VERSION "HNPBNNNYNNNNNNNNNNNNNNNNNNNNNNNNYNYYYYYYYY>4>%%%/4>'%**4YYY///"

NS_ :

BS_:

BU_: TPM TCM SCCM RF_HUB PTS ORC IC HaLF ETM ESM ESC EPS ECM Diagnost DTCM DASM CBC AFLS ADCM

BO_ 1099 VehCfgBu5: 8 RF_HUB
 SG_ VC_BU_VehCfg5_Stat : 0|2@1+ (1,0) [0|0] ""  CBC
 SG_ VC_BU_LUCI_PRSNT : 2|1@1+ (1,0) [0|0] ""  CBC
 SG_ VC_BU_RR_DuallyPrsnt : 3|1@1+ (1,0) [0|0] ""  CBC
 SG_ VC_BU_NonReg_TPIS : 4|1@1+ (1,0) [0|0] ""  CBC
 SG_ VC_BU_WTS_Prsnt : 5|1@1+ (1,0) [0|0] ""  CBC
 SG_ VC_BU_AmbTempLct : 6|2@1+ (1,0) [0|0] ""  CBC
 SG_ VC_BU_Strng_Rt_0 : 8|8@1+ (0.1,0) [0|25.4] ""  CBC
 SG_ VC_BU_Strng_Rt_pls1 : 16|8@1+ (0.1,0) [0|25.4] ""  CBC
 SG_ VC_BU_Strng_Rt_pls2 : 24|8@1+ (0.1,0) [0|25.4] ""  CBC
 SG_ VC_BU_Strng_Rt_pls3 : 32|8@1+ (0.1,0) [0|25.4] ""  CBC
 SG_ VC_BU_Strng_Rt_pls4 : 40|8@1+ (0.1,0) [0|25.4] ""  CBC
 SG_ VC_BU_Strng_Rt_pls5 : 48|8@1+ (0.1,0) [0|25.4] ""  CBC
 SG_ VC_BU_RearDoorLocks2DCM : 56|1@1+ (1,0) [0|0] ""  CBC
 SG_ VC_BU_SpdLmt_PRSNT : 57|1@1+ (1,0) [0|0] ""  CBC
 SG_ VC_BU_SBR_Prsnt : 58|1@1+ (1,0) [0|0] ""  CBC
 SG_ VC_BU_ChildDisp_Prsnt : 59|1@1+ (1,0) [0|0] ""  CBC
 SG_ VC_BU_OffRoadPg : 60|1@1+ (1,0) [0|0] ""  CBC
 SG_ VC_BU_AmbLtgPrsnt : 61|1@1+ (1,0) [0|0] ""  CBC
 SG_ VC_BU_PPPA_Prsnt : 62|1@1+ (1,0) [0|0] ""  CBC
 SG_ VC_BU_ParkStopPrsnt : 63|1@1+ (1,0) [0|0] ""  CBC

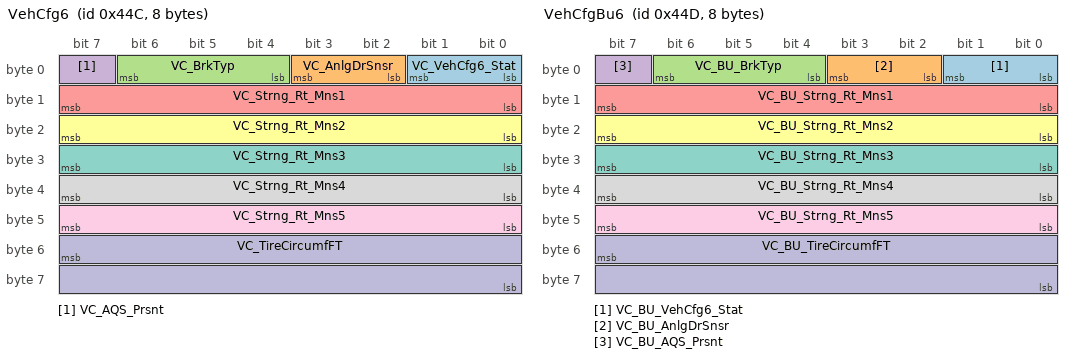
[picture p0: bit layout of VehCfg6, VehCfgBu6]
BO_ 1100 VehCfg6: 8 CBC
 SG_ VC_VehCfg6_Stat : 0|2@1+ (1,0) [0|0] ""  ORC,TCM,ECM,ESC,RF_HUB
 SG_ VC_AnlgDrSnsr : 2|2@1+ (1,0) [0|0] ""  ECM,RF_HUB
 SG_ VC_BrkTyp : 4|3@1+ (1,0) [0|0] ""  TCM,RF_HUB
 SG_ VC_AQS_Prsnt : 7|1@1+ (1,0) [0|0] ""  RF_HUB
 SG_ VC_Strng_Rt_Mns1 : 8|8@1+ (0.1,0) [0|25.4] ""  ESC,RF_HUB
 SG_ VC_Strng_Rt_Mns2 : 16|8@1+ (0.1,0) [0|25.4] ""  ESC,RF_HUB
 SG_ VC_Strng_Rt_Mns3 : 24|8@1+ (0.1,0) [0|25.4] ""  ESC,RF_HUB
 SG_ VC_Strng_Rt_Mns4 : 32|8@1+ (0.1,0) [0|25.4] ""  ESC,RF_HUB
 SG_ VC_Strng_Rt_Mns5 : 40|8@1+ (0.1,0) [0|25.4] ""  ESC,RF_HUB
 SG_ VC_TireCircumfFT : 55|16@0+ (1,0) [0|65534] "mm"  ORC,TCM,ECM,ESC,RF_HUB

BO_ 1101 VehCfgBu6: 8 RF_HUB
 SG_ VC_BU_VehCfg6_Stat : 0|2@1+ (1,0) [0|0] ""  CBC
 SG_ VC_BU_AnlgDrSnsr : 2|2@1+ (1,0) [0|0] ""  CBC
 SG_ VC_BU_BrkTyp : 4|3@1+ (1,0) [0|0] ""  CBC
 SG_ VC_BU_AQS_Prsnt : 7|1@1+ (1,0) [0|0] ""  CBC
 SG_ VC_BU_Strng_Rt_Mns1 : 8|8@1+ (0.1,0) [0|25.4] ""  CBC
 SG_ VC_BU_Strng_Rt_Mns2 : 16|8@1+ (0.1,0) [0|25.4] ""  CBC
 SG_ VC_BU_Strng_Rt_Mns3 : 24|8@1+ (0.1,0) [0|25.4] ""  CBC
 SG_ VC_BU_Strng_Rt_Mns4 : 32|8@1+ (0.1,0) [0|25.4] ""  CBC
 SG_ VC_BU_Strng_Rt_Mns5 : 40|8@1+ (0.1,0) [0|25.4] ""  CBC
 SG_ VC_BU_TireCircumfFT : 55|16@0+ (1,0) [0|65534] "mm"  CBC

BO_ 1216 D_RS_RF_HUB: 8 RF_HUB
 SG_ D_RS_RF_HUB : 7|64@0+ (1,0) [0|0] ""  Diagnost,ETM

BO_ 1218 D_RS_IC: 8 IC
 SG_ D_RS_IC : 7|64@0+ (1,0) [0|0] ""  Diagnost,ETM

BO_ 1219 D_RS_TPM: 8 TPM
 SG_ D_RS_TPM : 7|64@0+ (1,0) [0|0] ""  Diagnost,ETM

BO_ 1220 D_RS_ORC: 8 ORC
 SG_ D_RS_ORC : 7|64@0+ (1,0) [0|0] ""  Diagnost,ETM

BO_ 1221 D_RS_RBT_DR: 8 Vector__XXX
 SG_ D_RS_RBT_DR : 7|64@0+ (1,0) [0|0] ""  Diagnost,ETM

BO_ 1222 D_RS_RBT_PASS: 8 Vector__XXX
 SG_ D_RS_RBT_PASS : 7|64@0+ (1,0) [0|0] ""  Diagnost,ETM

BO_ 1223 D_RS_ESC: 8 ESC
 SG_ D_RS_ESC : 7|64@0+ (1,0) [0|0] ""  Diagnost,ETM

BO_ 1225 D_RS_ESM: 8 ESM
 SG_ D_RS_ESM : 7|64@0+ (1,0) [0|0] ""  Diagnost,ETM

BO_ 1227 D_RS_DTCM: 8 DTCM
 SG_ D_RS_DTCM : 7|64@0+ (1,0) [0|0] ""  Diagnost,ETM

BO_ 1228 D_RS_FDCM: 8 Vector__XXX
 SG_ D_RS_FDCM : 7|64@0+ (1,0) [0|0] ""  Diagnost,ETM

BO_ 1232 D_RS_SCRSM: 8 Vector__XXX
 SG_ D_RS_SCRSM : 7|64@0+ (1,0) [0|0] ""  Diagnost,ETM

BO_ 1235 D_RS_DASM: 8 DASM
 SG_ D_RS_DASM : 7|64@0+ (1,0) [0|0] ""  Diagnost,ETM

BO_ 1236 D_RS_ITBM: 8 Vector__XXX
 SG_ D_RS_ITBM : 7|64@0+ (1,0) [0|0] ""  Diagnost,ETM

BO_ 1239 D_RS_ADCM: 8 ADCM
 SG_ D_RS_ADCM : 7|64@0+ (1,0) [0|0] ""  Diagnost,ETM

BO_ 1241 D_RS_EPB: 8 Vector__XXX
 SG_ D_RS_EPB : 7|64@0+ (1,0) [0|0] ""  Diagnost,ETM

BO_ 1242 D_RS_EPS: 8 EPS
 SG_ D_RS_EPS : 7|64@0+ (1,0) [0|0] ""  Diagnost,ETM

BO_ 1246 D_RS_OCM: 8 Vector__XXX
 SG_ D_RS_OCM : 7|64@0+ (1,0) [0|0] ""  Diagnost,ETM

BO_ 1247 D_RS_EPPM: 8 Vector__XXX
 SG_ D_RS_EPPM : 7|64@0+ (1,0) [0|0] ""  Diagnost,ETM

BO_ 1250 D_RS_PTS: 8 PTS
 SG_ D_RS_PTS : 7|64@0+ (1,0) [0|0] ""  Diagnost,ETM

BO_ 1251 D_RS_SCCM: 8 SCCM
 SG_ D_RS_SCCM : 7|64@0+ (1,0) [0|0] ""  Diagnost,ETM

BO_ 1252 D_RS_HaLF: 8 HaLF
 SG_ D_RS_HaLF : 7|64@0+ (1,0) [0|0] ""  Diagnost,ETM

BO_ 1253 D_RS_ANC: 8 Vector__XXX
 SG_ D_RS_ANC : 7|64@0+ (1,0) [0|0] ""  Diagnost

BO_ 1254 D_RS_ASCM: 8 Vector__XXX
 SG_ D_RS_ASCM : 7|64@0+ (1,0) [0|0] ""  Diagnost,ETM

BO_ 1256 D_RS_AFLS: 8 AFLS
 SG_ D_RS_AFLS : 7|64@0+ (1,0) [0|0] ""  Diagnost,ETM

BO_ 1257 D_RS_AHLM: 8 Vector__XXX
 SG_ D_RS_AHLM : 7|64@0+ (1,0) [0|0] ""  Diagnost,ETM

BO_ 1264 D_RS_ELSD: 8 Vector__XXX
 SG_ D_RS_ELSD : 7|64@0+ (1,0) [0|0] ""  Diagnost,ETM

BO_ 1265 D_RS_VSIM: 8 Vector__XXX
 SG_ D_RS_VSIM : 7|64@0+ (1,0) [0|0] ""  Diagnost

BO_ 1271 D_RS_VGT: 8 Vector__XXX
 SG_ D_RS_VGT : 7|64@0+ (1,0) [0|0] ""  Diagnost

BO_ 1284 D_RS_CBC: 8 CBC
 SG_ D_RS_CBC : 7|64@0+ (1,0) [0|0] ""  Diagnost,ETM

BO_ 1408 ECU_APPL_RF_HUB: 8 RF_HUB
 SG_ ECU_APPL_RF_HUB : 7|64@0+ (1,0) [0|0] ""  Diagnost

BO_ 1409 ECU_APPL_CBC: 8 CBC
 SG_ ECU_APPL_CBC : 7|64@0+ (1,0) [0|0] ""  Diagnost

BO_ 1410 ECU_APPL_IC: 8 IC
 SG_ ECU_APPL_IC : 7|64@0+ (1,0) [0|0] ""  Diagnost

BO_ 1411 ECU_APPL_TPM: 8 TPM
 SG_ ECU_APPL_TPM : 7|64@0+ (1,0) [0|0] ""  Diagnost

BO_ 1412 ECU_APPL_ORC: 8 ORC
 SG_ ECU_APPL_ORC : 7|64@0+ (1,0) [0|0] ""  Diagnost

BO_ 1413 ECU_APPL_RBT_DR: 8 Vector__XXX
 SG_ ECU_APPL_RBT_DR : 7|64@0+ (1,0) [0|0] ""  Diagnost

BO_ 1414 ECU_APPL_RBT_PASS: 8 Vector__XXX
 SG_ ECU_APPL_RBT_PASS : 7|64@0+ (1,0) [0|0] ""  Diagnost

BO_ 1415 ECU_APPL_ESC: 8 ESC
 SG_ ECU_APPL_ESC : 7|64@0+ (1,0) [0|0] ""  Diagnost

BO_ 1417 ECU_APPL_ESM: 8 ESM
 SG_ ECU_APPL_ESM : 7|64@0+ (1,0) [0|0] ""  Diagnost

BO_ 1419 ECU_APPL_DTCM: 8 DTCM
 SG_ ECU_APPL_DTCM : 7|64@0+ (1,0) [0|0] ""  Diagnost

BO_ 1420 ECU_APPL_FDCM: 8 Vector__XXX
 SG_ ECU_APPL_FDCM : 7|64@0+ (1,0) [0|0] ""  Diagnost

BO_ 1427 ECU_APPL_DASM: 8 DASM
 SG_ ECU_APPL_DASM : 7|64@0+ (1,0) [0|0] ""  Diagnost

BO_ 1428 ECU_APPL_ITBM: 8 Vector__XXX
 SG_ ECU_APPL_ITBM : 7|64@0+ (1,0) [0|0] ""  Diagnost

BO_ 1431 ECU_APPL_ADCM: 8 ADCM
 SG_ ECU_APPL_ADCM : 7|64@0+ (1,0) [0|0] ""  Diagnost

BO_ 1433 ECU_APPL_EPB: 8 Vector__XXX
 SG_ ECU_APPL_EPB : 7|64@0+ (1,0) [0|0] ""  Diagnost

BO_ 1434 ECU_APPL_EPS: 8 EPS
 SG_ ECU_APPL_EPS : 7|64@0+ (1,0) [0|0] ""  Diagnost

BO_ 1438 ECU_APPL_OCM: 8 Vector__XXX
 SG_ ECU_APPL_OCM : 7|64@0+ (1,0) [0|0] ""  Diagnost

BO_ 1439 ECU_APPL_EPPM: 8 Vector__XXX
 SG_ ECU_APPL_EPPM : 7|64@0+ (1,0) [0|0] ""  Diagnost

BO_ 1442 ECU_APPL_PTS: 8 PTS
 SG_ ECU_APPL_PTS : 7|64@0+ (1,0) [0|0] ""  Diagnost

BO_ 1443 ECU_APPL_SCCM: 8 SCCM
 SG_ ECU_APPL_SCCM : 7|64@0+ (1,0) [0|0] ""  Diagnost

BO_ 1444 ECU_APPL_HaLF: 8 HaLF
 SG_ ECU_APPL_HaLF : 7|64@0+ (1,0) [0|0] ""  Diagnost

BO_ 1445 ECU_APPL_ANC: 8 Vector__XXX
 SG_ ECU_APPL_ANC : 7|64@0+ (1,0) [0|0] ""  Diagnost

BO_ 1446 ECU_APPL_ASCM: 8 Vector__XXX
 SG_ ECU_APPL_ASCM : 7|64@0+ (1,0) [0|0] ""  Diagnost

BO_ 1448 ECU_APPL_AFLS: 8 AFLS
 SG_ ECU_APPL_AFLS : 7|64@0+ (1,0) [0|0] ""  Diagnost

BO_ 1449 ECU_APPL_AHLM: 8 Vector__XXX
 SG_ ECU_APPL_AHLM : 7|64@0+ (1,0) [0|0] ""  Diagnost

BO_ 1456 ECU_APPL_ELSD: 8 Vector__XXX
 SG_ ECU_APPL_ELSD : 7|64@0+ (1,0) [0|0] ""  Diagnost

BO_ 1457 ECU_APPL_VSIM: 8 Vector__XXX
 SG_ ECU_APPL_VSIM : 7|64@0+ (1,0) [0|0] ""  Diagnost

BO_ 1464 ECU_APPL_ECM: 8 ECM
 SG_ ECU_APPL_ECM : 7|64@0+ (1,0) [0|0] ""  Diagnost

BO_ 1465 ECU_APPL_TCM: 8 ECM
 SG_ ECU_APPL_TCM : 7|64@0+ (1,0) [0|0] ""  Diagnost

BO_ 1536 SD_RS_RF_HUB: 8 RF_HUB
 SG_ SD_RS_RF_HUB : 7|64@0+ (1,0) [0|0] ""  Diagnost,ETM

BO_ 1537 SD_RS_CBC: 8 CBC
 SG_ SD_RS_CBC : 7|64@0+ (1,0) [0|0] ""  Diagnost,ETM

BO_ 1538 SD_RS_IC: 8 IC
 SG_ SD_RS_IC : 7|64@0+ (1,0) [0|0] ""  Diagnost,ETM

BO_ 1539 SD_RS_TPM: 8 TPM
 SG_ SD_RS_TPM : 7|64@0+ (1,0) [0|0] ""  Diagnost,ETM

BO_ 1540 SD_RS_ORC: 8 ORC
 SG_ SD_RS_ORC : 7|64@0+ (1,0) [0|0] ""  Diagnost,ETM

BO_ 1541 SD_RS_RBT_DR: 8 Vector__XXX
 SG_ SD_RS_RBT_DR : 7|64@0+ (1,0) [0|0] ""  Diagnost,ETM

BO_ 1542 SD_RS_RBT_PASS: 8 Vector__XXX
 SG_ SD_RS_RBT_PASS : 7|64@0+ (1,0) [0|0] ""  Diagnost,ETM

BO_ 1543 SD_RS_ESC: 8 ESC
 SG_ SD_RS_ESC : 7|64@0+ (1,0) [0|0] ""  Diagnost,ETM

BO_ 1545 SD_RS_ESM: 8 ESM
 SG_ SD_RS_ESM : 7|64@0+ (1,0) [0|0] ""  Diagnost,ETM

BO_ 1547 SD_RS_DTCM: 8 DTCM
 SG_ SD_RS_DTCM : 7|64@0+ (1,0) [0|0] ""  Diagnost,ETM

BO_ 1548 SD_RS_FDCM: 8 Vector__XXX
 SG_ SD_RS_FDCM : 7|64@0+ (1,0) [0|0] ""  Diagnost,ETM

BO_ 1555 SD_RS_DASM: 8 DASM
 SG_ SD_RS_DASM : 7|64@0+ (1,0) [0|0] ""  Diagnost,ETM

BO_ 1556 SD_RS_ITBM: 8 Vector__XXX
 SG_ SD_RS_ITBM : 7|64@0+ (1,0) [0|0] ""  Diagnost,ETM

BO_ 1559 SD_RS_ADCM: 8 ADCM
 SG_ SD_RS_ADCM : 7|64@0+ (1,0) [0|0] ""  Diagnost,ETM

BO_ 1561 SD_RS_EPB: 8 Vector__XXX
 SG_ SD_RS_EPB : 7|64@0+ (1,0) [0|0] ""  Diagnost,ETM

BO_ 1562 SD_RS_EPS: 8 EPS
 SG_ SD_RS_EPS : 7|64@0+ (1,0) [0|0] ""  Diagnost,ETM

BO_ 1566 SD_RS_OCM: 8 Vector__XXX
 SG_ SD_RS_OCM : 7|64@0+ (1,0) [0|0] ""  Diagnost,ETM

BO_ 1567 SD_RS_EPPM: 8 Vector__XXX
 SG_ SD_RS_EPPM : 7|64@0+ (1,0) [0|0] ""  Diagnost,ETM

BO_ 1568 D_RQ_CBC: 8 ETM
 SG_ D_RQ_CBC : 7|64@0+ (1,0) [0|0] ""  CBC

BO_ 1570 SD_RS_PTS: 8 PTS
 SG_ SD_RS_PTS : 7|64@0+ (1,0) [0|0] ""  Diagnost,ETM

BO_ 1571 SD_RS_SCCM: 8 SCCM
 SG_ SD_RS_SCCM : 7|64@0+ (1,0) [0|0] ""  Diagnost,ETM

BO_ 1572 SD_RS_HaLF: 8 HaLF
 SG_ SD_RS_HaLF : 7|64@0+ (1,0) [0|0] ""  Diagnost,ETM

BO_ 1573 SD_RS_ANC: 8 Vector__XXX
 SG_ SD_RS_ANC : 7|64@0+ (1,0) [0|0] ""  Diagnost

BO_ 1574 SD_RS_ASCM: 8 Vector__XXX
 SG_ SD_RS_ASCM : 7|64@0+ (1,0) [0|0] ""  Diagnost,ETM

BO_ 1576 SD_RS_AFLS: 8 AFLS
 SG_ SD_RS_AFLS : 7|64@0+ (1,0) [0|0] ""  Diagnost,ETM

BO_ 1577 SD_RS_AHLM: 8 Vector__XXX
 SG_ SD_RS_AHLM : 7|64@0+ (1,0) [0|0] ""  Diagnost,ETM

BO_ 1584 SD_RS_ELSD: 8 Vector__XXX
 SG_ SD_RS_ELSD : 7|64@0+ (1,0) [0|0] ""  Diagnost,ETM

BO_ 1585 SD_RS_VSIM: 8 Vector__XXX
 SG_ SD_RS_VSIM : 7|64@0+ (1,0) [0|0] ""  Diagnost

BO_ 1592 SD_RS_ECM: 8 ECM
 SG_ SD_RS_ECM : 7|64@0+ (1,0) [0|0] ""  Diagnost,ETM

BO_ 1593 SD_RS_TCM: 8 ECM
 SG_ SD_RS_TCM : 7|64@0+ (1,0) [0|0] ""  Diagnost,ETM

BO_ 1728 APPL_ECU_RF_HUB: 8 Diagnost
 SG_ APPL_ECU_RF_HUB : 7|64@0+ (1,0) [0|0] ""  RF_HUB

BO_ 1729 APPL_ECU_CBC: 8 Diagnost
 SG_ APPL_ECU_CBC : 7|64@0+ (1,0) [0|0] ""  CBC

BO_ 1730 APPL_ECU_IC: 8 Diagnost
 SG_ APPL_ECU_IC : 7|64@0+ (1,0) [0|0] ""  IC

BO_ 1731 APPL_ECU_TPM: 8 Diagnost
 SG_ APPL_ECU_TPM : 7|64@0+ (1,0) [0|0] ""  TPM

BO_ 1732 APPL_ECU_ORC: 8 Diagnost
 SG_ APPL_ECU_ORC : 7|64@0+ (1,0) [0|0] ""  ORC

BO_ 1733 APPL_ECU_RBT_DR: 8 Diagnost
 SG_ APPL_ECU_RBT_DR : 7|64@0+ (1,0) [0|0] "" Vector__XXX

BO_ 1734 APPL_ECU_RBT_PASS: 8 Diagnost
 SG_ APPL_ECU_RBT_PASS : 7|64@0+ (1,0) [0|0] "" Vector__XXX

BO_ 1735 APPL_ECU_ESC: 8 Diagnost
 SG_ APPL_ECU_ESC : 7|64@0+ (1,0) [0|0] ""  ESC

BO_ 1737 APPL_ECU_ESM: 8 Diagnost
 SG_ APPL_ECU_ESM : 7|64@0+ (1,0) [0|0] ""  ESM

BO_ 1739 APPL_ECU_DTCM: 8 Diagnost
 SG_ APPL_ECU_DTCM : 7|64@0+ (1,0) [0|0] ""  DTCM

BO_ 1740 APPL_ECU_FDCM: 8 Diagnost
 SG_ APPL_ECU_FDCM : 7|64@0+ (1,0) [0|0] "" Vector__XXX

BO_ 1747 APPL_ECU_DASM: 8 Diagnost
 SG_ APPL_ECU_DASM : 7|64@0+ (1,0) [0|0] ""  DASM

BO_ 1748 APPL_ECU_ITBM: 8 Diagnost
 SG_ APPL_ECU_ITBM : 7|64@0+ (1,0) [0|0] "" Vector__XXX

BO_ 1751 APPL_ECU_ADCM: 8 Diagnost
 SG_ APPL_ECU_ADCM : 7|64@0+ (1,0) [0|0] ""  ADCM

BO_ 1753 APPL_ECU_EPB: 8 Diagnost
 SG_ APPL_ECU_EPB : 7|64@0+ (1,0) [0|0] "" Vector__XXX

BO_ 1754 APPL_ECU_EPS: 8 Diagnost
 SG_ APPL_ECU_EPS : 7|64@0+ (1,0) [0|0] ""  EPS

BO_ 1758 APPL_ECU_OCM: 8 Diagnost
 SG_ APPL_ECU_OCM : 7|64@0+ (1,0) [0|0] "" Vector__XXX

BO_ 1759 APPL_ECU_EPPM: 8 Diagnost
 SG_ APPL_ECU_EPPM : 7|64@0+ (1,0) [0|0] "" Vector__XXX

BO_ 1762 APPL_ECU_PTS: 8 Diagnost
 SG_ APPL_ECU_PTS : 7|64@0+ (1,0) [0|0] ""  PTS

BO_ 1763 APPL_ECU_SCCM: 8 Diagnost
 SG_ APPL_ECU_SCCM : 7|64@0+ (1,0) [0|0] ""  SCCM

BO_ 1764 APPL_ECU_HALF: 8 Diagnost
 SG_ APPL_ECU_HaLF : 7|64@0+ (1,0) [0|0] ""  HaLF

BO_ 1765 APPL_ECU_ANC: 8 Diagnost
 SG_ APPL_ECU_ANC : 7|64@0+ (1,0) [0|0] "" Vector__XXX

BO_ 1766 APPL_ECU_ASCM: 8 Diagnost
 SG_ APPL_ECU_ASCM : 7|64@0+ (1,0) [0|0] "" Vector__XXX

BO_ 1768 APPL_ECU_AFLS: 8 Diagnost
 SG_ APPL_ECU_AFLS : 7|64@0+ (1,0) [0|0] ""  AFLS

BO_ 1769 APPL_ECU_AHLM: 8 Diagnost
 SG_ APPL_ECU_AHLM : 7|64@0+ (1,0) [0|0] "" Vector__XXX

BO_ 1776 APPL_ECU_ELSD: 8 Diagnost
 SG_ APPL_ECU_ELSD : 7|64@0+ (1,0) [0|0] "" Vector__XXX

BO_ 1777 APPL_ECU_VSIM: 8 Diagnost
 SG_ APPL_ECU_VSIM : 7|64@0+ (1,0) [0|0] "" Vector__XXX

BO_ 1784 APPL_ECU_ECM: 8 Diagnost
 SG_ APPL_ECU_ECM : 7|64@0+ (1,0) [0|0] ""  ECM

BO_ 1785 APPL_ECU_TCM: 8 Diagnost
 SG_ APPL_ECU_TCM : 7|64@0+ (1,0) [0|0] ""  ECM

BO_ 1856 D_RQ_RF_HUB: 8 ETM
 SG_ D_RQ_RF_HUB : 7|64@0+ (1,0) [0|0] ""  RF_HUB

BO_ 1858 D_RQ_IC: 8 ETM
 SG_ D_RQ_IC : 7|64@0+ (1,0) [0|0] ""  IC

BO_ 1859 D_RQ_TPM: 8 ETM
 SG_ D_RQ_TPM : 7|64@0+ (1,0) [0|0] ""  TPM

BO_ 1860 D_RQ_ORC: 8 ETM
 SG_ D_RQ_ORC : 7|64@0+ (1,0) [0|0] ""  ORC

BO_ 1861 D_RQ_RBT_DR: 8 ETM
 SG_ D_RQ_RBT_DR : 7|64@0+ (1,0) [0|0] "" Vector__XXX

BO_ 1862 D_RQ_RBT_PASS: 8 ETM
 SG_ D_RQ_RBT_PASS : 7|64@0+ (1,0) [0|0] "" Vector__XXX

BO_ 1863 D_RQ_ESC: 8 ETM
 SG_ D_RQ_ESC : 7|64@0+ (1,0) [0|0] ""  ESC

BO_ 1865 D_RQ_ESM: 8 ETM
 SG_ D_RQ_ESM : 7|64@0+ (1,0) [0|0] ""  ESM

BO_ 1867 D_RQ_DTCM: 8 ETM
 SG_ D_RQ_DTCM : 7|64@0+ (1,0) [0|0] ""  DTCM

BO_ 1868 D_RQ_FDCM: 8 ETM
 SG_ D_RQ_FDCM : 7|64@0+ (1,0) [0|0] "" Vector__XXX

BO_ 1872 D_RQ_SCRSM: 8 ETM
 SG_ D_RQ_SCRSM : 7|64@0+ (1,0) [0|0] "" Vector__XXX

BO_ 1875 D_RQ_DASM: 8 ETM
 SG_ D_RQ_DASM : 7|64@0+ (1,0) [0|0] ""  DASM

BO_ 1876 D_RQ_ITBM: 8 ETM
 SG_ D_RQ_ITBM : 7|64@0+ (1,0) [0|0] "" Vector__XXX

BO_ 1879 D_RQ_ADCM: 8 ETM
 SG_ D_RQ_ADCM : 7|64@0+ (1,0) [0|0] ""  ADCM

BO_ 1881 D_RQ_EPB: 8 ETM
 SG_ D_RQ_EPB : 7|64@0+ (1,0) [0|0] "" Vector__XXX

BO_ 1882 D_RQ_EPS: 8 ETM
 SG_ D_RQ_EPS : 7|64@0+ (1,0) [0|0] ""  EPS

BO_ 1883 APPL_ECU_75Bh: 8 Diagnost
 SG_ APPL_ECU_75Bh : 7|64@0+ (1,0) [0|0] ""  Diagnost

BO_ 1884 APPL_ECU_75Ch: 8 Diagnost
 SG_ APPL_ECU_75Ch : 7|64@0+ (1,0) [0|0] ""  Diagnost

BO_ 1885 APPL_ECU_75Dh: 8 Diagnost
 SG_ APPL_ECU_75Dh : 7|64@0+ (1,0) [0|0] ""  Diagnost

BO_ 1886 D_RQ_OCM: 8 ETM
 SG_ D_RQ_OCM : 7|64@0+ (1,0) [0|0] "" Vector__XXX

BO_ 1887 D_RQ_EPPM: 8 ETM
 SG_ D_RQ_EPPM : 7|64@0+ (1,0) [0|0] "" Vector__XXX

BO_ 1890 D_RQ_PTS: 8 ETM
 SG_ D_RQ_PTS : 7|64@0+ (1,0) [0|0] ""  PTS

BO_ 1891 D_RQ_SCCM: 8 ETM
 SG_ D_RQ_SCCM : 7|64@0+ (1,0) [0|0] ""  SCCM

BO_ 1892 D_RQ_HaLF: 8 ETM
 SG_ D_RQ_HaLF : 7|64@0+ (1,0) [0|0] ""  HaLF

BO_ 1893 D_RQ_ANC: 8 Diagnost
 SG_ D_RQ_ANC : 7|64@0+ (1,0) [0|0] "" Vector__XXX

BO_ 1894 D_RQ_ASCM: 8 ETM
 SG_ D_RQ_ASCM : 7|64@0+ (1,0) [0|0] "" Vector__XXX

BO_ 1896 D_RQ_AFLS: 8 ETM
 SG_ D_RQ_AFLS : 7|64@0+ (1,0) [0|0] ""  AFLS

BO_ 1897 D_RQ_AHLM: 8 ETM
 SG_ D_RQ_AHLM : 7|64@0+ (1,0) [0|0] "" Vector__XXX

BO_ 1904 D_RQ_ELSD: 8 ETM
 SG_ D_RQ_ELSD : 7|64@0+ (1,0) [0|0] "" Vector__XXX

BO_ 1905 D_RQ_VSIM: 8 Diagnost
 SG_ D_RQ_VSIM : 7|64@0+ (1,0) [0|0] "" Vector__XXX

BO_ 1911 D_RQ_VGT: 8 Diagnost
 SG_ D_RQ_VGT : 7|64@0+ (1,0) [0|0] "" Vector__XXX

BO_ 2015 DG_RQ_GLOBAL: 8 Diagnost
 SG_ DG_RQ_GLOBAL : 7|64@0+ (1,0) [0|0] ""  ETM,DTCM,TCM,ECM

BO_ 2016 D_RQ_ECM: 8 ETM
 SG_ D_RQ_ECM : 7|64@0+ (1,0) [0|0] ""  ECM

BO_ 2017 D_RQ_TCM: 8 ETM
 SG_ D_RQ_TCM : 7|64@0+ (1,0) [0|0] ""  TCM,ECM

BO_ 2024 D_RS_ECM: 8 ECM
 SG_ D_RS_ECM : 7|64@0+ (1,0) [0|0] ""  Diagnost,ETM

BO_ 2025 D_RS_TCM: 8 ECM
 SG_ D_RS_TCM : 7|64@0+ (1,0) [0|0] ""  Diagnost,ETM

CM_ SG_ 1099 VC_BU_VehCfg5_Stat "Backup for Configuration messages status 5";
CM_ SG_ 1099 VC_BU_LUCI_PRSNT "Backup for Luci feature present; present = [1]";
CM_ SG_ 1099 VC_BU_RR_DuallyPrsnt "Backup for vehicle is equipped with rear duals; present = [1]";
CM_ SG_ 1099 VC_BU_NonReg_TPIS "Backup for non-regulated tire pressure indicator system; True = 1";
CM_ SG_ 1099 VC_BU_WTS_Prsnt "Backup for wait to start feature is present; present = [1]";
CM_ SG_ 1099 VC_BU_AmbTempLct "Backup for ambient temperature sensor location";
CM_ SG_ 1099 VC_BU_Strng_Rt_0 "Backup for Steering Ratio at zero";
CM_ SG_ 1099 VC_BU_Strng_Rt_pls1 "Backup for Steering Ratio at positve angle 1";
CM_ SG_ 1099 VC_BU_Strng_Rt_pls2 "Backup for Steering Ratio at positve angle 2";
CM_ SG_ 1099 VC_BU_Strng_Rt_pls3 "Backup for Steering Ratio at positve angle 3";
CM_ SG_ 1099 VC_BU_Strng_Rt_pls4 "Backup for Steering Ratio at positve angle 4";
CM_ SG_ 1099 VC_BU_Strng_Rt_pls5 "Backup for Steering Ratio at positve angle 5";
CM_ SG_ 1099 VC_BU_RearDoorLocks2DCM "Backup for Rear door lock switch present; present = [1]";
CM_ SG_ 1099 VC_BU_SpdLmt_PRSNT "Backup for Speed limiter is present; present = [1]";
CM_ SG_ 1099 VC_BU_SBR_Prsnt "Backup for seat belt reminder module is present; True = 1";
CM_ SG_ 1099 VC_BU_ChildDisp_Prsnt "Backup for child display feature is present; True = 1";
CM_ SG_ 1099 VC_BU_OffRoadPg "Backup for off road pages present; True = [1]";
CM_ SG_ 1099 VC_BU_AmbLtgPrsnt "Backup for ambient lighting feature is present; True = 1";
CM_ SG_ 1099 VC_BU_PPPA_Prsnt "Backup for semi automatic parking system present; True = 1";
CM_ SG_ 1099 VC_BU_ParkStopPrsnt "Backup for park with stop is present; True = 1";
CM_ SG_ 1100 VC_VehCfg6_Stat "Configuration messages status 6";
CM_ SG_ 1100 VC_AnlgDrSnsr "Analog door sensor configuration";
CM_ SG_ 1100 VC_BrkTyp "Brake type configuration (M156/7)";
CM_ SG_ 1100 VC_AQS_Prsnt "Air quality sensor present; present = [1]";
CM_ SG_ 1100 VC_Strng_Rt_Mns1 "Steering Ratio at negative angle 1";
CM_ SG_ 1100 VC_Strng_Rt_Mns2 "Steering Ratio at negative angle 2";
CM_ SG_ 1100 VC_Strng_Rt_Mns3 "Steering Ratio at negative angle 3";
CM_ SG_ 1100 VC_Strng_Rt_Mns4 "Steering Ratio at negative angle 4";
CM_ SG_ 1100 VC_Strng_Rt_Mns5 "Steering Ratio at negative angle 5";
CM_ SG_ 1100 VC_TireCircumfFT "Dynamic tire circumference - front only";
CM_ SG_ 1101 VC_BU_VehCfg6_Stat "Backup for Configuration messages status 6";
CM_ SG_ 1101 VC_BU_AnlgDrSnsr "Analog door sensor configuration backup";
CM_ SG_ 1101 VC_BU_BrkTyp "Backup for brake type configuration (M156/7)";
CM_ SG_ 1101 VC_BU_AQS_Prsnt "Backup for air quality sensor present; present = [1]";
CM_ SG_ 1101 VC_BU_Strng_Rt_Mns1 "Backup for Steering Ratio at negative angle 1";
CM_ SG_ 1101 VC_BU_Strng_Rt_Mns2 "Backup for Steering Ratio at negative angle 2";
CM_ SG_ 1101 VC_BU_Strng_Rt_Mns3 "Backup for Steering Ratio at negative angle 3";
CM_ SG_ 1101 VC_BU_Strng_Rt_Mns4 "Backup for Steering Ratio at negative angle 4";
CM_ SG_ 1101 VC_BU_Strng_Rt_Mns5 "Backup for Steering Ratio at negative angle 5";
CM_ SG_ 1101 VC_BU_TireCircumfFT "Backup for Dynamic tire circumference - front only";
CM_ SG_ 1216 D_RS_RF_HUB "Diagnostic-Response";
CM_ SG_ 1218 D_RS_IC "Diagnostic-Response";
CM_ SG_ 1219 D_RS_TPM "Diagnostic-Response";
CM_ SG_ 1220 D_RS_ORC "Diagnostic-Response";
CM_ SG_ 1221 D_RS_RBT_DR "Diagnostic-Response";
CM_ SG_ 1222 D_RS_RBT_PASS "Diagnostic-Response";
CM_ SG_ 1223 D_RS_ESC "Diagnostic-Response";
CM_ SG_ 1225 D_RS_ESM "Diagnostic-Response";
CM_ SG_ 1227 D_RS_DTCM "Diagnostic-Response";
CM_ SG_ 1228 D_RS_FDCM "Diagnostic-Response";
CM_ SG_ 1232 D_RS_SCRSM "Diagnostic-Response";
CM_ SG_ 1235 D_RS_DASM "Diagnostic-Response";
CM_ SG_ 1236 D_RS_ITBM "Diagnostic-Response";
CM_ SG_ 1239 D_RS_ADCM "Diagnostic-Response";
CM_ SG_ 1241 D_RS_EPB "Diagnostic-Response";
CM_ SG_ 1242 D_RS_EPS "Diagnostic-Response";
CM_ SG_ 1246 D_RS_OCM "Diagnostic-Response";
CM_ SG_ 1247 D_RS_EPPM "Diagnostic-Response";
CM_ SG_ 1250 D_RS_PTS "Diagnostic-Response";
CM_ SG_ 1251 D_RS_SCCM "Diagnostic-Response";
CM_ SG_ 1252 D_RS_HaLF "Diagnostic-Response";
CM_ SG_ 1253 D_RS_ANC "Diagnostic-Response";
CM_ SG_ 1254 D_RS_ASCM "Diagnostic-Response";
CM_ SG_ 1256 D_RS_AFLS "Diagnostic-Response";
CM_ SG_ 1257 D_RS_AHLM "Diagnostic-Response";
CM_ SG_ 1264 D_RS_ELSD "Diagnostic-Response";
CM_ SG_ 1265 D_RS_VSIM "Diagnostic-Response";
CM_ SG_ 1271 D_RS_VGT "Diagnostic-Response";
CM_ SG_ 1284 D_RS_CBC "Diagnostic-Response";
CM_ SG_ 1408 ECU_APPL_RF_HUB "ECU to External Application";
CM_ SG_ 1409 ECU_APPL_CBC "ECU to External Application";
CM_ SG_ 1410 ECU_APPL_IC "ECU to External Application";
CM_ SG_ 1411 ECU_APPL_TPM "ECU to External Application";
CM_ SG_ 1412 ECU_APPL_ORC "ECU to External Application";
CM_ SG_ 1413 ECU_APPL_RBT_DR "ECU to External Application";
CM_ SG_ 1414 ECU_APPL_RBT_PASS "ECU to External Application";
CM_ SG_ 1415 ECU_APPL_ESC "ECU to External Application";
CM_ SG_ 1417 ECU_APPL_ESM "ECU to External Application";
CM_ SG_ 1419 ECU_APPL_DTCM "ECU to External Application";
CM_ SG_ 1420 ECU_APPL_FDCM "ECU to External Application";
CM_ SG_ 1427 ECU_APPL_DASM "ECU to External Application";
CM_ SG_ 1428 ECU_APPL_ITBM "ECU to External Application";
CM_ SG_ 1431 ECU_APPL_ADCM "ECU to External Application";
CM_ SG_ 1433 ECU_APPL_EPB "ECU to External Application";
CM_ SG_ 1434 ECU_APPL_EPS "ECU to External Application";
CM_ SG_ 1438 ECU_APPL_OCM "ECU to External Application";
CM_ SG_ 1439 ECU_APPL_EPPM "ECU to External Application";
CM_ SG_ 1442 ECU_APPL_PTS "ECU to External Application";
CM_ SG_ 1443 ECU_APPL_SCCM "ECU to External Application";
CM_ SG_ 1444 ECU_APPL_HaLF "ECU to External Application";
CM_ SG_ 1445 ECU_APPL_ANC "ECU to External Application";
CM_ SG_ 1446 ECU_APPL_ASCM "ECU to External Application";
CM_ SG_ 1448 ECU_APPL_AFLS "ECU to External Application";
CM_ SG_ 1449 ECU_APPL_AHLM "ECU to External Application";
CM_ SG_ 1456 ECU_APPL_ELSD "ECU to External Application";
CM_ SG_ 1457 ECU_APPL_VSIM "ECU to External Application";
CM_ SG_ 1464 ECU_APPL_ECM "ECU to External Application";
CM_ SG_ 1465 ECU_APPL_TCM "ECU to External Application";
CM_ SG_ 1536 SD_RS_RF_HUB "Response on Event - light";
CM_ SG_ 1537 SD_RS_CBC "Response on Event - light";
CM_ SG_ 1538 SD_RS_IC "Response on Event - light";
CM_ SG_ 1539 SD_RS_TPM "Response on Event - light";
CM_ SG_ 1540 SD_RS_ORC "Response on Event - light";
CM_ SG_ 1541 SD_RS_RBT_DR "Response on Event - light";
CM_ SG_ 1542 SD_RS_RBT_PASS "Response on Event - light";
CM_ SG_ 1543 SD_RS_ESC "Response on Event - light";
CM_ SG_ 1545 SD_RS_ESM "Response on Event - light";
CM_ SG_ 1547 SD_RS_DTCM "Response on Event - light";
CM_ SG_ 1548 SD_RS_FDCM "Response on Event - light";
CM_ SG_ 1555 SD_RS_DASM "Response on Event - light";
CM_ SG_ 1556 SD_RS_ITBM "Response on Event - light";
CM_ SG_ 1559 SD_RS_ADCM "Response on Event - light";
CM_ SG_ 1561 SD_RS_EPB "Response on Event - light";
CM_ SG_ 1562 SD_RS_EPS "Response on Event - light";
CM_ SG_ 1566 SD_RS_OCM "Response on Event - light";
CM_ SG_ 1567 SD_RS_EPPM "Response on Event - light";
CM_ SG_ 1568 D_RQ_CBC "Diagnostic-Request";
CM_ SG_ 1570 SD_RS_PTS "Response on Event - light";
CM_ SG_ 1571 SD_RS_SCCM "Response on Event - light";
CM_ SG_ 1572 SD_RS_HaLF "Response on Event - light";
CM_ SG_ 1573 SD_RS_ANC "Response on Event - light";
CM_ SG_ 1574 SD_RS_ASCM "Response on Event - light";
CM_ SG_ 1576 SD_RS_AFLS "Response on Event - light";
CM_ SG_ 1577 SD_RS_AHLM "Response on Event - light";
CM_ SG_ 1584 SD_RS_ELSD "Response on Event - light";
CM_ SG_ 1585 SD_RS_VSIM "Response on Event - light";
CM_ SG_ 1592 SD_RS_ECM "Response on Event - light";
CM_ SG_ 1593 SD_RS_TCM "Response on Event - light";
CM_ SG_ 1728 APPL_ECU_RF_HUB "External Application to ECU";
CM_ SG_ 1729 APPL_ECU_CBC "External Application to ECU";
CM_ SG_ 1730 APPL_ECU_IC "External Application to ECU";
CM_ SG_ 1731 APPL_ECU_TPM "External Application to ECU";
CM_ SG_ 1732 APPL_ECU_ORC "External Application to ECU";
CM_ SG_ 1733 APPL_ECU_RBT_DR "External Application to ECU";
CM_ SG_ 1734 APPL_ECU_RBT_PASS "External Application to ECU";
CM_ SG_ 1735 APPL_ECU_ESC "External Application to ECU";
CM_ SG_ 1737 APPL_ECU_ESM "External Application to ECU";
CM_ SG_ 1739 APPL_ECU_DTCM "External Application to ECU";
CM_ SG_ 1740 APPL_ECU_FDCM "External Application to ECU";
CM_ SG_ 1747 APPL_ECU_DASM "External Application to ECU";
CM_ SG_ 1748 APPL_ECU_ITBM "External Application to ECU";
CM_ SG_ 1751 APPL_ECU_ADCM "External Application to ECU";
CM_ SG_ 1753 APPL_ECU_EPB "External Application to ECU";
CM_ SG_ 1754 APPL_ECU_EPS "External Application to ECU";
CM_ SG_ 1758 APPL_ECU_OCM "External Application to ECU";
CM_ SG_ 1759 APPL_ECU_EPPM "External Application to ECU";
CM_ SG_ 1762 APPL_ECU_PTS "External Application to ECU";
CM_ SG_ 1763 APPL_ECU_SCCM "External Application to ECU";
CM_ SG_ 1764 APPL_ECU_HaLF "External Application to ECU";
CM_ SG_ 1765 APPL_ECU_ANC "External Application to ECU";
CM_ SG_ 1766 APPL_ECU_ASCM "External Application to ECU";
CM_ SG_ 1768 APPL_ECU_AFLS "External Application to ECU";
CM_ SG_ 1769 APPL_ECU_AHLM "External Application to ECU";
CM_ SG_ 1776 APPL_ECU_ELSD "External Application to ECU";
CM_ SG_ 1777 APPL_ECU_VSIM "External Application to ECU";
CM_ SG_ 1784 APPL_ECU_ECM "External Application to ECU";
CM_ SG_ 1785 APPL_ECU_TCM "External Application to ECU";
CM_ SG_ 1856 D_RQ_RF_HUB "Diagnostic-Request";
CM_ SG_ 1858 D_RQ_IC "Diagnostic-Request";
CM_ SG_ 1859 D_RQ_TPM "Diagnostic-Request";
CM_ SG_ 1860 D_RQ_ORC "Diagnostic-Request";
CM_ SG_ 1861 D_RQ_RBT_DR "Diagnostic-Request";
CM_ SG_ 1862 D_RQ_RBT_PASS "Diagnostic-Request";
CM_ SG_ 1863 D_RQ_ESC "Diagnostic-Request";
CM_ SG_ 1865 D_RQ_ESM "Diagnostic-Request";
CM_ SG_ 1867 D_RQ_DTCM "Diagnostic-Request";
CM_ SG_ 1868 D_RQ_FDCM "Diagnostic-Request";
CM_ SG_ 1872 D_RQ_SCRSM "Diagnostic-Request";
CM_ SG_ 1875 D_RQ_DASM "Diagnostic-Request";
CM_ SG_ 1876 D_RQ_ITBM "Diagnostic-Request";
CM_ SG_ 1879 D_RQ_ADCM "Diagnostic-Request";
CM_ SG_ 1881 D_RQ_EPB "Diagnostic-Request";
CM_ SG_ 1882 D_RQ_EPS "Diagnostic-Request";
CM_ SG_ 1883 APPL_ECU_75Bh "ID 75Bh held for use by CPG/APG test equipment";
CM_ SG_ 1884 APPL_ECU_75Ch "ID 75Ch held for use by CPG/APG test equipment";
CM_ SG_ 1885 APPL_ECU_75Dh "ID 75Dh held for use by CPG/APG test equipment";
CM_ SG_ 1886 D_RQ_OCM "Diagnostic-Request";
CM_ SG_ 1887 D_RQ_EPPM "Diagnostic-Request";
CM_ SG_ 1890 D_RQ_PTS "Diagnostic-Request";
CM_ SG_ 1891 D_RQ_SCCM "Diagnostic-Request";
CM_ SG_ 1892 D_RQ_HaLF "Diagnostic-Request";
CM_ SG_ 1893 D_RQ_ANC "Diagnostic-Request";
CM_ SG_ 1894 D_RQ_ASCM "Diagnostic-Request";
CM_ SG_ 1896 D_RQ_AFLS "Diagnostic-Request";
CM_ SG_ 1897 D_RQ_AHLM "Diagnostic-Request";
CM_ SG_ 1904 D_RQ_ELSD "Diagnostic-Request";
CM_ SG_ 1905 D_RQ_VSIM "Diagnostic-Request";
CM_ SG_ 1911 D_RQ_VGT "Diagnostic-Request";
CM_ SG_ 2015 DG_RQ_GLOBAL "Diagnostic-Request";
CM_ SG_ 2016 D_RQ_ECM "Diagnostic-Request";
CM_ SG_ 2017 D_RQ_TCM "Diagnostic-Request";
CM_ SG_ 2024 D_RS_ECM "Diagnostic-Response";
CM_ SG_ 2025 D_RS_TCM "Diagnostic-Response";
BA_DEF_ SG_  "GenSigTimeout_ADCM" INT 0 65535;
BA_DEF_ SG_  "GenSigTimeout_AFLS" INT 0 65535;
BA_DEF_ SG_  "GenSigTimeout_CBC" INT 0 65535;
BA_DEF_ SG_  "GenSigTimeout_DTCM" INT 0 65535;
BA_DEF_ SG_  "GenSigTimeout_ECM" INT 0 65535;
BA_DEF_ SG_  "GenSigTimeout_EPS" INT 0 65535;
BA_DEF_ SG_  "GenSigTimeout_ESC" INT 0 65535;
BA_DEF_ SG_  "GenSigTimeout_ESM" INT 0 65535;
BA_DEF_ SG_  "GenSigTimeout_ETM" INT 0 65535;
BA_DEF_ SG_  "GenSigTimeout_HaLF" INT 0 65535;
BA_DEF_ SG_  "GenSigTimeout_IC" INT 0 65535;
BA_DEF_ SG_  "GenSigTimeout_ORC" INT 0 65535;
BA_DEF_ SG_  "GenSigTimeout_PTS" INT 0 65535;
BA_DEF_ SG_  "GenSigTimeout_RF_HUB" INT 0 65535;
BA_DEF_ SG_  "GenSigTimeout_SCCM" INT 0 65535;
BA_DEF_ SG_  "GenSigTimeout_TPM" INT 0 65535;
BA_DEF_ BO_  "GenMsgStartValue" STRING ;
BA_DEF_ SG_  "GenSigSNA" STRING ;
BA_DEF_ SG_  "FlexKomIsMotorola" ENUM  "nein","ja";
BA_DEF_ SG_  "FlexKomSigLaenge" INT 0 64;
BA_DEF_ SG_  "FlexKomSigStartPos" INT 0 63;
BA_DEF_ SG_  "FlexKomComment" STRING ;
BA_DEF_ SG_  "FlexKomSigName" STRING ;
BA_DEF_ SG_  "FlexKomSID" INT 0 2147483647;
BA_DEF_ SG_  "GenSigStartValue" HEX 0 4294967295;
BA_DEF_ SG_  "FlexKomSigStartValue" STRING ;
BA_DEF_ SG_  "GenSigCycleTimeActive" INT 0 65535;
BA_DEF_ SG_  "GenSigCycleTime" INT 0 65535;
BA_DEF_ SG_  "GenSigSendType" ENUM  "cyclicX","spontanX","cyclicIfActiveX","spontanWithDelay","cyclicAndSpontanX","cyclicAndSpontanWithDelay","spontanWithRepitition","cyclicIfActiveAndSpontanWD","cyclicIfActiveFast","cyclicWithRepeatOnDemand","none";
BA_DEF_ BO_  "GenMsgNrOfRepetitions" INT 0 65535;
BA_DEF_ BO_  "GenMsgDelayTime" INT 0 65535;
BA_DEF_ BO_  "GenMsgStartDelayTime" INT 0 65535;
BA_DEF_ BO_  "GenMsgCycleTimeActive" INT 0 65535;
BA_DEF_ BO_  "GenMsgCycleTime" INT 0 65535;
BA_DEF_ BO_  "GenMsgSendType" ENUM  "cyclicX","spontanX","cyclicIfActiveX","spontanWithDelay","cyclicAndSpontanX","cyclicAndSpontanWithDelay","spontanWithRepitition","cyclicIfActiveAndSpontanWD","cyclicIfActiveFast","cyclicWithRepeatOnDemand","none";
BA_DEF_ BO_  "DiagResponse" ENUM  "nein","ja";
BA_DEF_ BO_  "DiagRequest" ENUM  "nein","ja";
BA_DEF_ BO_  "DiagState" ENUM  "nein","ja";
BA_DEF_ BO_  "App-Botschaft" ENUM  "nein","ja";
BA_DEF_ BO_  "NWM-Botschaft" ENUM  "nein","ja";
BA_DEF_DEF_  "GenSigTimeout_ADCM" 0;
BA_DEF_DEF_  "GenSigTimeout_AFLS" 0;
BA_DEF_DEF_  "GenSigTimeout_CBC" 0;
BA_DEF_DEF_  "GenSigTimeout_DTCM" 0;
BA_DEF_DEF_  "GenSigTimeout_ECM" 0;
BA_DEF_DEF_  "GenSigTimeout_EPS" 0;
BA_DEF_DEF_  "GenSigTimeout_ESC" 0;
BA_DEF_DEF_  "GenSigTimeout_ESM" 0;
BA_DEF_DEF_  "GenSigTimeout_ETM" 0;
BA_DEF_DEF_  "GenSigTimeout_HaLF" 0;
BA_DEF_DEF_  "GenSigTimeout_IC" 0;
BA_DEF_DEF_  "GenSigTimeout_ORC" 0;
BA_DEF_DEF_  "GenSigTimeout_PTS" 0;
BA_DEF_DEF_  "GenSigTimeout_RF_HUB" 0;
BA_DEF_DEF_  "GenSigTimeout_SCCM" 0;
BA_DEF_DEF_  "GenSigTimeout_TPM" 0;
BA_DEF_DEF_  "GenMsgStartValue" "";
BA_DEF_DEF_  "GenSigSNA" "";
BA_DEF_DEF_  "FlexKomIsMotorola" "nein";
BA_DEF_DEF_  "FlexKomSigLaenge" 0;
BA_DEF_DEF_  "FlexKomSigStartPos" 0;
BA_DEF_DEF_  "FlexKomComment" "";
BA_DEF_DEF_  "FlexKomSigName" "";
BA_DEF_DEF_  "FlexKomSID" 0;
BA_DEF_DEF_  "GenSigStartValue" 0;
BA_DEF_DEF_  "FlexKomSigStartValue" "";
BA_DEF_DEF_  "GenSigCycleTimeActive" 0;
BA_DEF_DEF_  "GenSigCycleTime" 0;
BA_DEF_DEF_  "GenSigSendType" "cyclicX";
BA_DEF_DEF_  "GenMsgNrOfRepetitions" 0;
BA_DEF_DEF_  "GenMsgDelayTime" 0;
BA_DEF_DEF_  "GenMsgStartDelayTime" 0;
BA_DEF_DEF_  "GenMsgCycleTimeActive" 0;
BA_DEF_DEF_  "GenMsgCycleTime" 0;
BA_DEF_DEF_  "GenMsgSendType" "cyclicX";
BA_DEF_DEF_  "DiagResponse" "nein";
BA_DEF_DEF_  "DiagRequest" "nein";
BA_DEF_DEF_  "DiagState" "nein";
BA_DEF_DEF_  "App-Botschaft" "nein";
BA_DEF_DEF_  "NWM-Botschaft" "nein";
BA_ "GenMsgSendType" BO_ 1099 1;
BA_ "GenMsgDelayTime" BO_ 1099 20;
BA_ "GenMsgNrOfRepetitions" BO_ 1099 2;
BA_ "GenMsgStartValue" BO_ 1099 "C3FFFFFFFFFFFF00h";
BA_ "GenMsgSendType" BO_ 1100 5;
BA_ "GenMsgCycleTime" BO_ 1100 2000;
BA_ "GenMsgDelayTime" BO_ 1100 20;
BA_ "GenMsgNrOfRepetitions" BO_ 1100 2;
BA_ "GenMsgStartValue" BO_ 1100 "73FFFFFFFFFFFFFFh";
BA_ "GenMsgStartDelayTime" BO_ 1100 70;
BA_ "GenMsgSendType" BO_ 1101 1;
BA_ "GenMsgDelayTime" BO_ 1101 20;
BA_ "GenMsgNrOfRepetitions" BO_ 1101 2;
BA_ "GenMsgStartValue" BO_ 1101 "73FFFFFFFFFFFFFFh";
BA_ "DiagResponse" BO_ 1216 1;
BA_ "GenMsgDelayTime" BO_ 1216 20;
BA_ "GenMsgNrOfRepetitions" BO_ 1216 2;
BA_ "GenMsgStartValue" BO_ 1216 "0000000000000000h";
BA_ "DiagResponse" BO_ 1218 1;
BA_ "GenMsgDelayTime" BO_ 1218 20;
BA_ "GenMsgNrOfRepetitions" BO_ 1218 2;
BA_ "GenMsgStartValue" BO_ 1218 "0000000000000000h";
BA_ "DiagResponse" BO_ 1219 1;
BA_ "GenMsgDelayTime" BO_ 1219 20;
BA_ "GenMsgNrOfRepetitions" BO_ 1219 2;
BA_ "GenMsgStartValue" BO_ 1219 "0000000000000000h";
BA_ "DiagResponse" BO_ 1220 1;
BA_ "GenMsgDelayTime" BO_ 1220 20;
BA_ "GenMsgNrOfRepetitions" BO_ 1220 2;
BA_ "GenMsgStartValue" BO_ 1220 "0000000000000000h";
BA_ "DiagResponse" BO_ 1221 1;
BA_ "GenMsgDelayTime" BO_ 1221 20;
BA_ "GenMsgNrOfRepetitions" BO_ 1221 2;
BA_ "GenMsgStartValue" BO_ 1221 "0000000000000000h";
BA_ "DiagResponse" BO_ 1222 1;
BA_ "GenMsgDelayTime" BO_ 1222 20;
BA_ "GenMsgNrOfRepetitions" BO_ 1222 2;
BA_ "GenMsgStartValue" BO_ 1222 "0000000000000000h";
BA_ "DiagResponse" BO_ 1223 1;
BA_ "GenMsgDelayTime" BO_ 1223 20;
BA_ "GenMsgNrOfRepetitions" BO_ 1223 2;
BA_ "GenMsgStartValue" BO_ 1223 "0000000000000000h";
BA_ "DiagResponse" BO_ 1225 1;
BA_ "GenMsgDelayTime" BO_ 1225 20;
BA_ "GenMsgNrOfRepetitions" BO_ 1225 2;
BA_ "GenMsgStartValue" BO_ 1225 "0000000000000000h";
BA_ "DiagResponse" BO_ 1227 1;
BA_ "GenMsgDelayTime" BO_ 1227 20;
BA_ "GenMsgNrOfRepetitions" BO_ 1227 2;
BA_ "GenMsgStartValue" BO_ 1227 "0000000000000000h";
BA_ "DiagResponse" BO_ 1228 1;
BA_ "GenMsgDelayTime" BO_ 1228 20;
BA_ "GenMsgNrOfRepetitions" BO_ 1228 2;
BA_ "GenMsgStartValue" BO_ 1228 "0000000000000000h";
BA_ "DiagResponse" BO_ 1232 1;
BA_ "GenMsgDelayTime" BO_ 1232 20;
BA_ "GenMsgNrOfRepetitions" BO_ 1232 2;
BA_ "GenMsgStartValue" BO_ 1232 "0000000000000000h";
BA_ "DiagResponse" BO_ 1235 1;
BA_ "GenMsgDelayTime" BO_ 1235 20;
BA_ "GenMsgNrOfRepetitions" BO_ 1235 2;
BA_ "GenMsgStartValue" BO_ 1235 "0000000000000000h";
BA_ "DiagResponse" BO_ 1236 1;
BA_ "GenMsgDelayTime" BO_ 1236 20;
BA_ "GenMsgNrOfRepetitions" BO_ 1236 2;
BA_ "GenMsgStartValue" BO_ 1236 "0000000000000000h";
BA_ "DiagResponse" BO_ 1239 1;
BA_ "GenMsgDelayTime" BO_ 1239 20;
BA_ "GenMsgNrOfRepetitions" BO_ 1239 2;
BA_ "GenMsgStartValue" BO_ 1239 "0000000000000000h";
BA_ "DiagResponse" BO_ 1241 1;
BA_ "GenMsgDelayTime" BO_ 1241 20;
BA_ "GenMsgNrOfRepetitions" BO_ 1241 2;
BA_ "GenMsgStartValue" BO_ 1241 "0000000000000000h";
BA_ "DiagResponse" BO_ 1242 1;
BA_ "GenMsgDelayTime" BO_ 1242 20;
BA_ "GenMsgNrOfRepetitions" BO_ 1242 2;
BA_ "GenMsgStartValue" BO_ 1242 "0000000000000000h";
BA_ "DiagResponse" BO_ 1246 1;
BA_ "GenMsgDelayTime" BO_ 1246 20;
BA_ "GenMsgNrOfRepetitions" BO_ 1246 2;
BA_ "GenMsgStartValue" BO_ 1246 "0000000000000000h";
BA_ "DiagResponse" BO_ 1247 1;
BA_ "GenMsgDelayTime" BO_ 1247 20;
BA_ "GenMsgNrOfRepetitions" BO_ 1247 2;
BA_ "GenMsgStartValue" BO_ 1247 "0000000000000000h";
BA_ "DiagResponse" BO_ 1250 1;
BA_ "GenMsgDelayTime" BO_ 1250 20;
BA_ "GenMsgNrOfRepetitions" BO_ 1250 2;
BA_ "GenMsgStartValue" BO_ 1250 "0000000000000000h";
BA_ "DiagResponse" BO_ 1251 1;
BA_ "GenMsgDelayTime" BO_ 1251 20;
BA_ "GenMsgNrOfRepetitions" BO_ 1251 2;
BA_ "GenMsgStartValue" BO_ 1251 "0000000000000000h";
BA_ "DiagResponse" BO_ 1252 1;
BA_ "GenMsgDelayTime" BO_ 1252 20;
BA_ "GenMsgNrOfRepetitions" BO_ 1252 2;
BA_ "GenMsgStartValue" BO_ 1252 "0000000000000000h";
BA_ "DiagResponse" BO_ 1253 1;
BA_ "GenMsgDelayTime" BO_ 1253 20;
BA_ "GenMsgNrOfRepetitions" BO_ 1253 2;
BA_ "GenMsgStartValue" BO_ 1253 "0000000000000000h";
BA_ "DiagResponse" BO_ 1254 1;
BA_ "GenMsgDelayTime" BO_ 1254 20;
BA_ "GenMsgNrOfRepetitions" BO_ 1254 2;
BA_ "GenMsgStartValue" BO_ 1254 "0000000000000000h";
BA_ "DiagResponse" BO_ 1256 1;
BA_ "GenMsgDelayTime" BO_ 1256 20;
BA_ "GenMsgNrOfRepetitions" BO_ 1256 2;
BA_ "GenMsgStartValue" BO_ 1256 "0000000000000000h";
BA_ "DiagResponse" BO_ 1257 1;
BA_ "GenMsgDelayTime" BO_ 1257 20;
BA_ "GenMsgNrOfRepetitions" BO_ 1257 2;
BA_ "GenMsgStartValue" BO_ 1257 "0000000000000000h";
BA_ "DiagResponse" BO_ 1264 1;
BA_ "GenMsgDelayTime" BO_ 1264 20;
BA_ "GenMsgNrOfRepetitions" BO_ 1264 2;
BA_ "GenMsgStartValue" BO_ 1264 "0000000000000000h";
BA_ "DiagResponse" BO_ 1265 1;
BA_ "GenMsgDelayTime" BO_ 1265 20;
BA_ "GenMsgNrOfRepetitions" BO_ 1265 2;
BA_ "GenMsgStartValue" BO_ 1265 "0000000000000000h";
BA_ "DiagResponse" BO_ 1271 1;
BA_ "GenMsgDelayTime" BO_ 1271 20;
BA_ "GenMsgNrOfRepetitions" BO_ 1271 2;
BA_ "GenMsgStartValue" BO_ 1271 "0000000000000000h";
BA_ "DiagResponse" BO_ 1284 1;
BA_ "GenMsgDelayTime" BO_ 1284 20;
BA_ "GenMsgNrOfRepetitions" BO_ 1284 2;
BA_ "GenMsgStartValue" BO_ 1284 "0000000000000000h";
BA_ "App-Botschaft" BO_ 1408 1;
BA_ "GenMsgSendType" BO_ 1408 1;
BA_ "GenMsgDelayTime" BO_ 1408 20;
BA_ "GenMsgNrOfRepetitions" BO_ 1408 2;
BA_ "GenMsgStartValue" BO_ 1408 "0000000000000000h";
BA_ "App-Botschaft" BO_ 1409 1;
BA_ "GenMsgSendType" BO_ 1409 1;
BA_ "GenMsgDelayTime" BO_ 1409 20;
BA_ "GenMsgNrOfRepetitions" BO_ 1409 2;
BA_ "GenMsgStartValue" BO_ 1409 "0000000000000000h";
BA_ "App-Botschaft" BO_ 1410 1;
BA_ "GenMsgSendType" BO_ 1410 1;
BA_ "GenMsgDelayTime" BO_ 1410 20;
BA_ "GenMsgNrOfRepetitions" BO_ 1410 2;
BA_ "GenMsgStartValue" BO_ 1410 "0000000000000000h";
BA_ "App-Botschaft" BO_ 1411 1;
BA_ "GenMsgSendType" BO_ 1411 1;
BA_ "GenMsgDelayTime" BO_ 1411 20;
BA_ "GenMsgNrOfRepetitions" BO_ 1411 2;
BA_ "GenMsgStartValue" BO_ 1411 "0000000000000000h";
BA_ "App-Botschaft" BO_ 1412 1;
BA_ "GenMsgSendType" BO_ 1412 1;
BA_ "GenMsgDelayTime" BO_ 1412 20;
BA_ "GenMsgNrOfRepetitions" BO_ 1412 2;
BA_ "GenMsgStartValue" BO_ 1412 "0000000000000000h";
BA_ "App-Botschaft" BO_ 1413 1;
BA_ "GenMsgSendType" BO_ 1413 1;
BA_ "GenMsgDelayTime" BO_ 1413 20;
BA_ "GenMsgNrOfRepetitions" BO_ 1413 2;
BA_ "GenMsgStartValue" BO_ 1413 "0000000000000000h";
BA_ "App-Botschaft" BO_ 1414 1;
BA_ "GenMsgSendType" BO_ 1414 1;
BA_ "GenMsgDelayTime" BO_ 1414 20;
BA_ "GenMsgNrOfRepetitions" BO_ 1414 2;
BA_ "GenMsgStartValue" BO_ 1414 "0000000000000000h";
BA_ "App-Botschaft" BO_ 1415 1;
BA_ "GenMsgSendType" BO_ 1415 1;
BA_ "GenMsgDelayTime" BO_ 1415 20;
BA_ "GenMsgNrOfRepetitions" BO_ 1415 2;
BA_ "GenMsgStartValue" BO_ 1415 "0000000000000000h";
BA_ "App-Botschaft" BO_ 1417 1;
BA_ "GenMsgSendType" BO_ 1417 1;
BA_ "GenMsgDelayTime" BO_ 1417 20;
BA_ "GenMsgNrOfRepetitions" BO_ 1417 2;
BA_ "GenMsgStartValue" BO_ 1417 "0000000000000000h";
BA_ "App-Botschaft" BO_ 1419 1;
BA_ "GenMsgSendType" BO_ 1419 1;
BA_ "GenMsgDelayTime" BO_ 1419 20;
BA_ "GenMsgNrOfRepetitions" BO_ 1419 2;
BA_ "GenMsgStartValue" BO_ 1419 "0000000000000000h";
BA_ "App-Botschaft" BO_ 1420 1;
BA_ "GenMsgSendType" BO_ 1420 1;
BA_ "GenMsgDelayTime" BO_ 1420 20;
BA_ "GenMsgNrOfRepetitions" BO_ 1420 2;
BA_ "GenMsgStartValue" BO_ 1420 "0000000000000000h";
BA_ "App-Botschaft" BO_ 1427 1;
BA_ "GenMsgSendType" BO_ 1427 1;
BA_ "GenMsgDelayTime" BO_ 1427 20;
BA_ "GenMsgNrOfRepetitions" BO_ 1427 2;
BA_ "GenMsgStartValue" BO_ 1427 "0000000000000000h";
BA_ "App-Botschaft" BO_ 1428 1;
BA_ "GenMsgSendType" BO_ 1428 1;
BA_ "GenMsgDelayTime" BO_ 1428 20;
BA_ "GenMsgNrOfRepetitions" BO_ 1428 2;
BA_ "GenMsgStartValue" BO_ 1428 "0000000000000000h";
BA_ "App-Botschaft" BO_ 1431 1;
BA_ "GenMsgSendType" BO_ 1431 1;
BA_ "GenMsgDelayTime" BO_ 1431 20;
BA_ "GenMsgNrOfRepetitions" BO_ 1431 2;
BA_ "GenMsgStartValue" BO_ 1431 "0000000000000000h";
BA_ "App-Botschaft" BO_ 1433 1;
BA_ "GenMsgSendType" BO_ 1433 1;
BA_ "GenMsgDelayTime" BO_ 1433 20;
BA_ "GenMsgNrOfRepetitions" BO_ 1433 2;
BA_ "GenMsgStartValue" BO_ 1433 "0000000000000000h";
BA_ "App-Botschaft" BO_ 1434 1;
BA_ "GenMsgSendType" BO_ 1434 1;
BA_ "GenMsgDelayTime" BO_ 1434 20;
BA_ "GenMsgNrOfRepetitions" BO_ 1434 2;
BA_ "GenMsgStartValue" BO_ 1434 "0000000000000000h";
BA_ "App-Botschaft" BO_ 1438 1;
BA_ "GenMsgSendType" BO_ 1438 1;
BA_ "GenMsgDelayTime" BO_ 1438 20;
BA_ "GenMsgNrOfRepetitions" BO_ 1438 2;
BA_ "GenMsgStartValue" BO_ 1438 "0000000000000000h";
BA_ "App-Botschaft" BO_ 1439 1;
BA_ "GenMsgSendType" BO_ 1439 1;
BA_ "GenMsgDelayTime" BO_ 1439 20;
BA_ "GenMsgNrOfRepetitions" BO_ 1439 2;
BA_ "GenMsgStartValue" BO_ 1439 "0000000000000000h";
BA_ "App-Botschaft" BO_ 1442 1;
BA_ "GenMsgSendType" BO_ 1442 1;
BA_ "GenMsgDelayTime" BO_ 1442 20;
BA_ "GenMsgNrOfRepetitions" BO_ 1442 2;
BA_ "GenMsgStartValue" BO_ 1442 "0000000000000000h";
BA_ "App-Botschaft" BO_ 1443 1;
BA_ "GenMsgSendType" BO_ 1443 1;
BA_ "GenMsgDelayTime" BO_ 1443 20;
BA_ "GenMsgNrOfRepetitions" BO_ 1443 2;
BA_ "GenMsgStartValue" BO_ 1443 "0000000000000000h";
BA_ "App-Botschaft" BO_ 1444 1;
BA_ "GenMsgSendType" BO_ 1444 1;
BA_ "GenMsgDelayTime" BO_ 1444 20;
BA_ "GenMsgNrOfRepetitions" BO_ 1444 2;
BA_ "GenMsgStartValue" BO_ 1444 "0000000000000000h";
BA_ "App-Botschaft" BO_ 1445 1;
BA_ "GenMsgSendType" BO_ 1445 1;
BA_ "GenMsgDelayTime" BO_ 1445 20;
BA_ "GenMsgNrOfRepetitions" BO_ 1445 2;
BA_ "GenMsgStartValue" BO_ 1445 "0000000000000000h";
BA_ "App-Botschaft" BO_ 1446 1;
BA_ "GenMsgSendType" BO_ 1446 1;
BA_ "GenMsgDelayTime" BO_ 1446 20;
BA_ "GenMsgNrOfRepetitions" BO_ 1446 2;
BA_ "GenMsgStartValue" BO_ 1446 "0000000000000000h";
BA_ "App-Botschaft" BO_ 1448 1;
BA_ "GenMsgSendType" BO_ 1448 1;
BA_ "GenMsgDelayTime" BO_ 1448 20;
BA_ "GenMsgNrOfRepetitions" BO_ 1448 2;
BA_ "GenMsgStartValue" BO_ 1448 "0000000000000000h";
BA_ "App-Botschaft" BO_ 1449 1;
BA_ "GenMsgSendType" BO_ 1449 1;
BA_ "GenMsgDelayTime" BO_ 1449 20;
BA_ "GenMsgNrOfRepetitions" BO_ 1449 2;
BA_ "GenMsgStartValue" BO_ 1449 "0000000000000000h";
BA_ "App-Botschaft" BO_ 1456 1;
BA_ "GenMsgSendType" BO_ 1456 1;
BA_ "GenMsgDelayTime" BO_ 1456 20;
BA_ "GenMsgNrOfRepetitions" BO_ 1456 2;
BA_ "GenMsgStartValue" BO_ 1456 "0000000000000000h";
BA_ "App-Botschaft" BO_ 1457 1;
BA_ "GenMsgSendType" BO_ 1457 1;
BA_ "GenMsgDelayTime" BO_ 1457 20;
BA_ "GenMsgNrOfRepetitions" BO_ 1457 2;
BA_ "GenMsgStartValue" BO_ 1457 "0000000000000000h";
BA_ "App-Botschaft" BO_ 1464 1;
BA_ "GenMsgSendType" BO_ 1464 1;
BA_ "GenMsgDelayTime" BO_ 1464 20;
BA_ "GenMsgNrOfRepetitions" BO_ 1464 2;
BA_ "GenMsgStartValue" BO_ 1464 "0000000000000000h";
BA_ "App-Botschaft" BO_ 1465 1;
BA_ "GenMsgSendType" BO_ 1465 1;
BA_ "GenMsgDelayTime" BO_ 1465 20;
BA_ "GenMsgNrOfRepetitions" BO_ 1465 2;
BA_ "GenMsgStartValue" BO_ 1465 "0000000000000000h";
BA_ "GenMsgSendType" BO_ 1536 1;
BA_ "GenMsgDelayTime" BO_ 1536 20;
BA_ "GenMsgNrOfRepetitions" BO_ 1536 2;
BA_ "GenMsgStartValue" BO_ 1536 "0000000000000000h";
BA_ "GenMsgSendType" BO_ 1537 1;
BA_ "GenMsgDelayTime" BO_ 1537 20;
BA_ "GenMsgNrOfRepetitions" BO_ 1537 2;
BA_ "GenMsgStartValue" BO_ 1537 "0000000000000000h";
BA_ "GenMsgSendType" BO_ 1538 1;
BA_ "GenMsgDelayTime" BO_ 1538 20;
BA_ "GenMsgNrOfRepetitions" BO_ 1538 2;
BA_ "GenMsgStartValue" BO_ 1538 "0000000000000000h";
BA_ "GenMsgSendType" BO_ 1539 1;
BA_ "GenMsgDelayTime" BO_ 1539 20;
BA_ "GenMsgNrOfRepetitions" BO_ 1539 2;
BA_ "GenMsgStartValue" BO_ 1539 "0000000000000000h";
BA_ "GenMsgSendType" BO_ 1540 1;
BA_ "GenMsgDelayTime" BO_ 1540 20;
BA_ "GenMsgNrOfRepetitions" BO_ 1540 2;
BA_ "GenMsgStartValue" BO_ 1540 "0000000000000000h";
BA_ "GenMsgSendType" BO_ 1541 1;
BA_ "GenMsgDelayTime" BO_ 1541 20;
BA_ "GenMsgNrOfRepetitions" BO_ 1541 2;
BA_ "GenMsgStartValue" BO_ 1541 "0000000000000000h";
BA_ "GenMsgSendType" BO_ 1542 1;
BA_ "GenMsgDelayTime" BO_ 1542 20;
BA_ "GenMsgNrOfRepetitions" BO_ 1542 2;
BA_ "GenMsgStartValue" BO_ 1542 "0000000000000000h";
BA_ "GenMsgSendType" BO_ 1543 1;
BA_ "GenMsgDelayTime" BO_ 1543 20;
BA_ "GenMsgNrOfRepetitions" BO_ 1543 2;
BA_ "GenMsgStartValue" BO_ 1543 "0000000000000000h";
BA_ "GenMsgSendType" BO_ 1545 1;
BA_ "GenMsgDelayTime" BO_ 1545 20;
BA_ "GenMsgNrOfRepetitions" BO_ 1545 2;
BA_ "GenMsgStartValue" BO_ 1545 "0000000000000000h";
BA_ "GenMsgSendType" BO_ 1547 1;
BA_ "GenMsgDelayTime" BO_ 1547 20;
BA_ "GenMsgNrOfRepetitions" BO_ 1547 2;
BA_ "GenMsgStartValue" BO_ 1547 "0000000000000000h";
BA_ "GenMsgSendType" BO_ 1548 1;
BA_ "GenMsgDelayTime" BO_ 1548 20;
BA_ "GenMsgNrOfRepetitions" BO_ 1548 2;
BA_ "GenMsgStartValue" BO_ 1548 "0000000000000000h";
BA_ "GenMsgSendType" BO_ 1555 1;
BA_ "GenMsgDelayTime" BO_ 1555 20;
BA_ "GenMsgNrOfRepetitions" BO_ 1555 2;
BA_ "GenMsgStartValue" BO_ 1555 "0000000000000000h";
BA_ "GenMsgSendType" BO_ 1556 1;
BA_ "GenMsgDelayTime" BO_ 1556 20;
BA_ "GenMsgNrOfRepetitions" BO_ 1556 2;
BA_ "GenMsgStartValue" BO_ 1556 "0000000000000000h";
BA_ "GenMsgSendType" BO_ 1559 1;
BA_ "GenMsgDelayTime" BO_ 1559 20;
BA_ "GenMsgNrOfRepetitions" BO_ 1559 2;
BA_ "GenMsgStartValue" BO_ 1559 "0000000000000000h";
BA_ "GenMsgSendType" BO_ 1561 1;
BA_ "GenMsgDelayTime" BO_ 1561 20;
BA_ "GenMsgNrOfRepetitions" BO_ 1561 2;
BA_ "GenMsgStartValue" BO_ 1561 "0000000000000000h";
BA_ "GenMsgSendType" BO_ 1562 1;
BA_ "GenMsgDelayTime" BO_ 1562 20;
BA_ "GenMsgNrOfRepetitions" BO_ 1562 2;
BA_ "GenMsgStartValue" BO_ 1562 "0000000000000000h";
BA_ "GenMsgSendType" BO_ 1566 9;
BA_ "GenMsgCycleTime" BO_ 1566 200;
BA_ "GenMsgDelayTime" BO_ 1566 200;
BA_ "GenMsgStartValue" BO_ 1566 "0000000000000000h";
BA_ "GenMsgSendType" BO_ 1567 1;
BA_ "GenMsgDelayTime" BO_ 1567 20;
BA_ "GenMsgNrOfRepetitions" BO_ 1567 2;
BA_ "GenMsgStartValue" BO_ 1567 "0000000000000000h";
BA_ "DiagRequest" BO_ 1568 1;
BA_ "GenMsgDelayTime" BO_ 1568 20;
BA_ "GenMsgNrOfRepetitions" BO_ 1568 2;
BA_ "GenMsgStartValue" BO_ 1568 "0000000000000000h";
BA_ "GenMsgSendType" BO_ 1570 1;
BA_ "GenMsgDelayTime" BO_ 1570 20;
BA_ "GenMsgNrOfRepetitions" BO_ 1570 2;
BA_ "GenMsgStartValue" BO_ 1570 "0000000000000000h";
BA_ "GenMsgSendType" BO_ 1571 1;
BA_ "GenMsgDelayTime" BO_ 1571 20;
BA_ "GenMsgNrOfRepetitions" BO_ 1571 2;
BA_ "GenMsgStartValue" BO_ 1571 "0000000000000000h";
BA_ "GenMsgSendType" BO_ 1572 1;
BA_ "GenMsgDelayTime" BO_ 1572 20;
BA_ "GenMsgNrOfRepetitions" BO_ 1572 2;
BA_ "GenMsgStartValue" BO_ 1572 "0000000000000000h";
BA_ "GenMsgSendType" BO_ 1573 1;
BA_ "GenMsgDelayTime" BO_ 1573 20;
BA_ "GenMsgNrOfRepetitions" BO_ 1573 2;
BA_ "GenMsgStartValue" BO_ 1573 "0000000000000000h";
BA_ "GenMsgSendType" BO_ 1574 1;
BA_ "GenMsgDelayTime" BO_ 1574 20;
BA_ "GenMsgNrOfRepetitions" BO_ 1574 2;
BA_ "GenMsgStartValue" BO_ 1574 "0000000000000000h";
BA_ "GenMsgSendType" BO_ 1576 1;
BA_ "GenMsgDelayTime" BO_ 1576 20;
BA_ "GenMsgNrOfRepetitions" BO_ 1576 2;
BA_ "GenMsgStartValue" BO_ 1576 "0000000000000000h";
BA_ "GenMsgSendType" BO_ 1577 1;
BA_ "GenMsgDelayTime" BO_ 1577 20;
BA_ "GenMsgNrOfRepetitions" BO_ 1577 2;
BA_ "GenMsgStartValue" BO_ 1577 "0000000000000000h";
BA_ "GenMsgSendType" BO_ 1584 1;
BA_ "GenMsgDelayTime" BO_ 1584 20;
BA_ "GenMsgNrOfRepetitions" BO_ 1584 2;
BA_ "GenMsgStartValue" BO_ 1584 "0000000000000000h";
BA_ "GenMsgSendType" BO_ 1585 1;
BA_ "GenMsgDelayTime" BO_ 1585 20;
BA_ "GenMsgNrOfRepetitions" BO_ 1585 2;
BA_ "GenMsgStartValue" BO_ 1585 "0000000000000000h";
BA_ "GenMsgSendType" BO_ 1592 1;
BA_ "GenMsgDelayTime" BO_ 1592 20;
BA_ "GenMsgNrOfRepetitions" BO_ 1592 2;
BA_ "GenMsgStartValue" BO_ 1592 "0000000000000000h";
BA_ "GenMsgSendType" BO_ 1593 1;
BA_ "GenMsgDelayTime" BO_ 1593 20;
BA_ "GenMsgNrOfRepetitions" BO_ 1593 2;
BA_ "GenMsgStartValue" BO_ 1593 "0000000000000000h";
BA_ "App-Botschaft" BO_ 1728 1;
BA_ "GenMsgSendType" BO_ 1728 1;
BA_ "GenMsgDelayTime" BO_ 1728 20;
BA_ "GenMsgNrOfRepetitions" BO_ 1728 2;
BA_ "GenMsgStartValue" BO_ 1728 "0000000000000000h";
BA_ "App-Botschaft" BO_ 1729 1;
BA_ "GenMsgSendType" BO_ 1729 1;
BA_ "GenMsgDelayTime" BO_ 1729 20;
BA_ "GenMsgNrOfRepetitions" BO_ 1729 2;
BA_ "GenMsgStartValue" BO_ 1729 "0000000000000000h";
BA_ "App-Botschaft" BO_ 1730 1;
BA_ "GenMsgSendType" BO_ 1730 1;
BA_ "GenMsgDelayTime" BO_ 1730 20;
BA_ "GenMsgNrOfRepetitions" BO_ 1730 2;
BA_ "GenMsgStartValue" BO_ 1730 "0000000000000000h";
BA_ "App-Botschaft" BO_ 1731 1;
BA_ "GenMsgSendType" BO_ 1731 1;
BA_ "GenMsgDelayTime" BO_ 1731 20;
BA_ "GenMsgNrOfRepetitions" BO_ 1731 2;
BA_ "GenMsgStartValue" BO_ 1731 "0000000000000000h";
BA_ "App-Botschaft" BO_ 1732 1;
BA_ "GenMsgSendType" BO_ 1732 1;
BA_ "GenMsgDelayTime" BO_ 1732 20;
BA_ "GenMsgNrOfRepetitions" BO_ 1732 2;
BA_ "GenMsgStartValue" BO_ 1732 "0000000000000000h";
BA_ "App-Botschaft" BO_ 1733 1;
BA_ "GenMsgSendType" BO_ 1733 1;
BA_ "GenMsgDelayTime" BO_ 1733 20;
BA_ "GenMsgNrOfRepetitions" BO_ 1733 2;
BA_ "GenMsgStartValue" BO_ 1733 "0000000000000000h";
BA_ "App-Botschaft" BO_ 1734 1;
BA_ "GenMsgSendType" BO_ 1734 1;
BA_ "GenMsgDelayTime" BO_ 1734 20;
BA_ "GenMsgNrOfRepetitions" BO_ 1734 2;
BA_ "GenMsgStartValue" BO_ 1734 "0000000000000000h";
BA_ "App-Botschaft" BO_ 1735 1;
BA_ "GenMsgSendType" BO_ 1735 1;
BA_ "GenMsgDelayTime" BO_ 1735 20;
BA_ "GenMsgNrOfRepetitions" BO_ 1735 2;
BA_ "GenMsgStartValue" BO_ 1735 "0000000000000000h";
BA_ "App-Botschaft" BO_ 1737 1;
BA_ "GenMsgSendType" BO_ 1737 1;
BA_ "GenMsgDelayTime" BO_ 1737 20;
BA_ "GenMsgNrOfRepetitions" BO_ 1737 2;
BA_ "GenMsgStartValue" BO_ 1737 "0000000000000000h";
BA_ "App-Botschaft" BO_ 1739 1;
BA_ "GenMsgSendType" BO_ 1739 1;
BA_ "GenMsgDelayTime" BO_ 1739 20;
BA_ "GenMsgNrOfRepetitions" BO_ 1739 2;
BA_ "GenMsgStartValue" BO_ 1739 "0000000000000000h";
BA_ "App-Botschaft" BO_ 1740 1;
BA_ "GenMsgSendType" BO_ 1740 1;
BA_ "GenMsgDelayTime" BO_ 1740 20;
BA_ "GenMsgNrOfRepetitions" BO_ 1740 2;
BA_ "GenMsgStartValue" BO_ 1740 "0000000000000000h";
BA_ "App-Botschaft" BO_ 1747 1;
BA_ "GenMsgSendType" BO_ 1747 1;
BA_ "GenMsgDelayTime" BO_ 1747 20;
BA_ "GenMsgNrOfRepetitions" BO_ 1747 2;
BA_ "GenMsgStartValue" BO_ 1747 "0000000000000000h";
BA_ "App-Botschaft" BO_ 1748 1;
BA_ "GenMsgSendType" BO_ 1748 1;
BA_ "GenMsgDelayTime" BO_ 1748 20;
BA_ "GenMsgNrOfRepetitions" BO_ 1748 2;
BA_ "GenMsgStartValue" BO_ 1748 "0000000000000000h";
BA_ "App-Botschaft" BO_ 1751 1;
BA_ "GenMsgSendType" BO_ 1751 1;
BA_ "GenMsgDelayTime" BO_ 1751 20;
BA_ "GenMsgNrOfRepetitions" BO_ 1751 2;
BA_ "GenMsgStartValue" BO_ 1751 "0000000000000000h";
BA_ "App-Botschaft" BO_ 1753 1;
BA_ "GenMsgSendType" BO_ 1753 1;
BA_ "GenMsgDelayTime" BO_ 1753 20;
BA_ "GenMsgNrOfRepetitions" BO_ 1753 2;
BA_ "GenMsgStartValue" BO_ 1753 "0000000000000000h";
BA_ "App-Botschaft" BO_ 1754 1;
BA_ "GenMsgSendType" BO_ 1754 1;
BA_ "GenMsgDelayTime" BO_ 1754 20;
BA_ "GenMsgNrOfRepetitions" BO_ 1754 2;
BA_ "GenMsgStartValue" BO_ 1754 "0000000000000000h";
BA_ "App-Botschaft" BO_ 1758 1;
BA_ "GenMsgSendType" BO_ 1758 1;
BA_ "GenMsgDelayTime" BO_ 1758 20;
BA_ "GenMsgNrOfRepetitions" BO_ 1758 2;
BA_ "GenMsgStartValue" BO_ 1758 "0000000000000000h";
BA_ "App-Botschaft" BO_ 1759 1;
BA_ "GenMsgSendType" BO_ 1759 1;
BA_ "GenMsgDelayTime" BO_ 1759 20;
BA_ "GenMsgNrOfRepetitions" BO_ 1759 2;
BA_ "GenMsgStartValue" BO_ 1759 "0000000000000000h";
BA_ "App-Botschaft" BO_ 1762 1;
BA_ "GenMsgSendType" BO_ 1762 1;
BA_ "GenMsgDelayTime" BO_ 1762 20;
BA_ "GenMsgNrOfRepetitions" BO_ 1762 2;
BA_ "GenMsgStartValue" BO_ 1762 "0000000000000000h";
BA_ "App-Botschaft" BO_ 1763 1;
BA_ "GenMsgSendType" BO_ 1763 1;
BA_ "GenMsgDelayTime" BO_ 1763 20;
BA_ "GenMsgNrOfRepetitions" BO_ 1763 2;
BA_ "GenMsgStartValue" BO_ 1763 "0000000000000000h";
BA_ "App-Botschaft" BO_ 1764 1;
BA_ "GenMsgSendType" BO_ 1764 1;
BA_ "GenMsgDelayTime" BO_ 1764 20;
BA_ "GenMsgNrOfRepetitions" BO_ 1764 2;
BA_ "GenMsgStartValue" BO_ 1764 "0000000000000000h";
BA_ "App-Botschaft" BO_ 1765 1;
BA_ "GenMsgSendType" BO_ 1765 1;
BA_ "GenMsgDelayTime" BO_ 1765 20;
BA_ "GenMsgNrOfRepetitions" BO_ 1765 2;
BA_ "GenMsgStartValue" BO_ 1765 "0000000000000000h";
BA_ "App-Botschaft" BO_ 1766 1;
BA_ "GenMsgSendType" BO_ 1766 1;
BA_ "GenMsgDelayTime" BO_ 1766 20;
BA_ "GenMsgNrOfRepetitions" BO_ 1766 2;
BA_ "GenMsgStartValue" BO_ 1766 "0000000000000000h";
BA_ "App-Botschaft" BO_ 1768 1;
BA_ "GenMsgSendType" BO_ 1768 1;
BA_ "GenMsgDelayTime" BO_ 1768 20;
BA_ "GenMsgNrOfRepetitions" BO_ 1768 2;
BA_ "GenMsgStartValue" BO_ 1768 "0000000000000000h";
BA_ "App-Botschaft" BO_ 1769 1;
BA_ "GenMsgSendType" BO_ 1769 1;
BA_ "GenMsgDelayTime" BO_ 1769 20;
BA_ "GenMsgNrOfRepetitions" BO_ 1769 2;
BA_ "GenMsgStartValue" BO_ 1769 "0000000000000000h";
BA_ "App-Botschaft" BO_ 1776 1;
BA_ "GenMsgSendType" BO_ 1776 1;
BA_ "GenMsgDelayTime" BO_ 1776 20;
BA_ "GenMsgNrOfRepetitions" BO_ 1776 2;
BA_ "GenMsgStartValue" BO_ 1776 "0000000000000000h";
BA_ "App-Botschaft" BO_ 1777 1;
BA_ "GenMsgSendType" BO_ 1777 1;
BA_ "GenMsgDelayTime" BO_ 1777 20;
BA_ "GenMsgNrOfRepetitions" BO_ 1777 2;
BA_ "GenMsgStartValue" BO_ 1777 "0000000000000000h";
BA_ "App-Botschaft" BO_ 1784 1;
BA_ "GenMsgSendType" BO_ 1784 1;
BA_ "GenMsgDelayTime" BO_ 1784 20;
BA_ "GenMsgNrOfRepetitions" BO_ 1784 2;
BA_ "GenMsgStartValue" BO_ 1784 "0000000000000000h";
BA_ "App-Botschaft" BO_ 1785 1;
BA_ "GenMsgSendType" BO_ 1785 1;
BA_ "GenMsgDelayTime" BO_ 1785 20;
BA_ "GenMsgNrOfRepetitions" BO_ 1785 2;
BA_ "GenMsgStartValue" BO_ 1785 "0000000000000000h";
BA_ "DiagRequest" BO_ 1856 1;
BA_ "GenMsgDelayTime" BO_ 1856 20;
BA_ "GenMsgNrOfRepetitions" BO_ 1856 2;
BA_ "GenMsgStartValue" BO_ 1856 "0000000000000000h";
BA_ "DiagRequest" BO_ 1858 1;
BA_ "GenMsgDelayTime" BO_ 1858 20;
BA_ "GenMsgNrOfRepetitions" BO_ 1858 2;
BA_ "GenMsgStartValue" BO_ 1858 "0000000000000000h";
BA_ "DiagRequest" BO_ 1859 1;
BA_ "GenMsgDelayTime" BO_ 1859 20;
BA_ "GenMsgNrOfRepetitions" BO_ 1859 2;
BA_ "GenMsgStartValue" BO_ 1859 "0000000000000000h";
BA_ "DiagRequest" BO_ 1860 1;
BA_ "GenMsgDelayTime" BO_ 1860 20;
BA_ "GenMsgNrOfRepetitions" BO_ 1860 2;
BA_ "GenMsgStartValue" BO_ 1860 "0000000000000000h";
BA_ "DiagRequest" BO_ 1861 1;
BA_ "GenMsgDelayTime" BO_ 1861 20;
BA_ "GenMsgNrOfRepetitions" BO_ 1861 2;
BA_ "GenMsgStartValue" BO_ 1861 "0000000000000000h";
BA_ "DiagRequest" BO_ 1862 1;
BA_ "GenMsgDelayTime" BO_ 1862 20;
BA_ "GenMsgNrOfRepetitions" BO_ 1862 2;
BA_ "GenMsgStartValue" BO_ 1862 "0000000000000000h";
BA_ "DiagRequest" BO_ 1863 1;
BA_ "GenMsgDelayTime" BO_ 1863 20;
BA_ "GenMsgNrOfRepetitions" BO_ 1863 2;
BA_ "GenMsgStartValue" BO_ 1863 "0000000000000000h";
BA_ "DiagRequest" BO_ 1865 1;
BA_ "GenMsgDelayTime" BO_ 1865 20;
BA_ "GenMsgNrOfRepetitions" BO_ 1865 2;
BA_ "GenMsgStartValue" BO_ 1865 "0000000000000000h";
BA_ "DiagRequest" BO_ 1867 1;
BA_ "GenMsgDelayTime" BO_ 1867 20;
BA_ "GenMsgNrOfRepetitions" BO_ 1867 2;
BA_ "GenMsgStartValue" BO_ 1867 "0000000000000000h";
BA_ "DiagRequest" BO_ 1868 1;
BA_ "GenMsgDelayTime" BO_ 1868 20;
BA_ "GenMsgNrOfRepetitions" BO_ 1868 2;
BA_ "GenMsgStartValue" BO_ 1868 "0000000000000000h";
BA_ "DiagRequest" BO_ 1872 1;
BA_ "GenMsgDelayTime" BO_ 1872 20;
BA_ "GenMsgNrOfRepetitions" BO_ 1872 2;
BA_ "GenMsgStartValue" BO_ 1872 "0000000000000000h";
BA_ "DiagRequest" BO_ 1875 1;
BA_ "GenMsgDelayTime" BO_ 1875 20;
BA_ "GenMsgNrOfRepetitions" BO_ 1875 2;
BA_ "GenMsgStartValue" BO_ 1875 "0000000000000000h";
BA_ "DiagRequest" BO_ 1876 1;
BA_ "GenMsgDelayTime" BO_ 1876 20;
BA_ "GenMsgNrOfRepetitions" BO_ 1876 2;
BA_ "GenMsgStartValue" BO_ 1876 "0000000000000000h";
BA_ "DiagRequest" BO_ 1879 1;
BA_ "GenMsgDelayTime" BO_ 1879 20;
BA_ "GenMsgNrOfRepetitions" BO_ 1879 2;
BA_ "GenMsgStartValue" BO_ 1879 "0000000000000000h";
BA_ "DiagRequest" BO_ 1881 1;
BA_ "GenMsgDelayTime" BO_ 1881 20;
BA_ "GenMsgNrOfRepetitions" BO_ 1881 2;
BA_ "GenMsgStartValue" BO_ 1881 "0000000000000000h";
BA_ "DiagRequest" BO_ 1882 1;
BA_ "GenMsgDelayTime" BO_ 1882 20;
BA_ "GenMsgNrOfRepetitions" BO_ 1882 2;
BA_ "GenMsgStartValue" BO_ 1882 "0000000000000000h";
BA_ "App-Botschaft" BO_ 1883 1;
BA_ "GenMsgSendType" BO_ 1883 1;
BA_ "GenMsgDelayTime" BO_ 1883 20;
BA_ "GenMsgNrOfRepetitions" BO_ 1883 2;
BA_ "GenMsgStartValue" BO_ 1883 "0000000000000000h";
BA_ "App-Botschaft" BO_ 1884 1;
BA_ "GenMsgSendType" BO_ 1884 1;
BA_ "GenMsgDelayTime" BO_ 1884 20;
BA_ "GenMsgNrOfRepetitions" BO_ 1884 2;
BA_ "GenMsgStartValue" BO_ 1884 "0000000000000000h";
BA_ "App-Botschaft" BO_ 1885 1;
BA_ "GenMsgSendType" BO_ 1885 1;
BA_ "GenMsgDelayTime" BO_ 1885 20;
BA_ "GenMsgNrOfRepetitions" BO_ 1885 2;
BA_ "GenMsgStartValue" BO_ 1885 "0000000000000000h";
BA_ "DiagRequest" BO_ 1886 1;
BA_ "GenMsgDelayTime" BO_ 1886 20;
BA_ "GenMsgNrOfRepetitions" BO_ 1886 2;
BA_ "GenMsgStartValue" BO_ 1886 "0000000000000000h";
BA_ "DiagRequest" BO_ 1887 1;
BA_ "GenMsgDelayTime" BO_ 1887 20;
BA_ "GenMsgNrOfRepetitions" BO_ 1887 2;
BA_ "GenMsgStartValue" BO_ 1887 "0000000000000000h";
BA_ "DiagRequest" BO_ 1890 1;
BA_ "GenMsgDelayTime" BO_ 1890 20;
BA_ "GenMsgNrOfRepetitions" BO_ 1890 2;
BA_ "GenMsgStartValue" BO_ 1890 "0000000000000000h";
BA_ "DiagRequest" BO_ 1891 1;
BA_ "GenMsgDelayTime" BO_ 1891 20;
BA_ "GenMsgNrOfRepetitions" BO_ 1891 2;
BA_ "GenMsgStartValue" BO_ 1891 "0000000000000000h";
BA_ "DiagRequest" BO_ 1892 1;
BA_ "GenMsgDelayTime" BO_ 1892 20;
BA_ "GenMsgNrOfRepetitions" BO_ 1892 2;
BA_ "GenMsgStartValue" BO_ 1892 "0000000000000000h";
BA_ "DiagRequest" BO_ 1893 1;
BA_ "GenMsgDelayTime" BO_ 1893 20;
BA_ "GenMsgNrOfRepetitions" BO_ 1893 2;
BA_ "GenMsgStartValue" BO_ 1893 "0000000000000000h";
BA_ "DiagRequest" BO_ 1894 1;
BA_ "GenMsgDelayTime" BO_ 1894 20;
BA_ "GenMsgNrOfRepetitions" BO_ 1894 2;
BA_ "GenMsgStartValue" BO_ 1894 "0000000000000000h";
BA_ "DiagRequest" BO_ 1896 1;
BA_ "GenMsgDelayTime" BO_ 1896 20;
BA_ "GenMsgNrOfRepetitions" BO_ 1896 2;
BA_ "GenMsgStartValue" BO_ 1896 "0000000000000000h";
BA_ "DiagRequest" BO_ 1897 1;
BA_ "GenMsgDelayTime" BO_ 1897 20;
BA_ "GenMsgNrOfRepetitions" BO_ 1897 2;
BA_ "GenMsgStartValue" BO_ 1897 "0000000000000000h";
BA_ "DiagRequest" BO_ 1904 1;
BA_ "GenMsgDelayTime" BO_ 1904 20;
BA_ "GenMsgNrOfRepetitions" BO_ 1904 2;
BA_ "GenMsgStartValue" BO_ 1904 "0000000000000000h";
BA_ "DiagRequest" BO_ 1905 1;
BA_ "GenMsgDelayTime" BO_ 1905 20;
BA_ "GenMsgNrOfRepetitions" BO_ 1905 2;
BA_ "GenMsgStartValue" BO_ 1905 "0000000000000000h";
BA_ "DiagRequest" BO_ 1911 1;
BA_ "GenMsgDelayTime" BO_ 1911 20;
BA_ "GenMsgNrOfRepetitions" BO_ 1911 2;
BA_ "GenMsgStartValue" BO_ 1911 "0000000000000000h";
BA_ "DiagState" BO_ 2015 1;
BA_ "GenMsgDelayTime" BO_ 2015 20;
BA_ "GenMsgNrOfRepetitions" BO_ 2015 2;
BA_ "GenMsgStartValue" BO_ 2015 "0000000000000000h";
BA_ "DiagRequest" BO_ 2016 1;
BA_ "GenMsgDelayTime" BO_ 2016 20;
BA_ "GenMsgNrOfRepetitions" BO_ 2016 2;
BA_ "GenMsgStartValue" BO_ 2016 "0000000000000000h";
BA_ "DiagRequest" BO_ 2017 1;
BA_ "GenMsgDelayTime" BO_ 2017 20;
BA_ "GenMsgNrOfRepetitions" BO_ 2017 2;
BA_ "GenMsgStartValue" BO_ 2017 "0000000000000000h";
BA_ "DiagResponse" BO_ 2024 1;
BA_ "GenMsgDelayTime" BO_ 2024 20;
BA_ "GenMsgNrOfRepetitions" BO_ 2024 2;
BA_ "GenMsgStartValue" BO_ 2024 "0000000000000000h";
BA_ "DiagResponse" BO_ 2025 1;
BA_ "GenMsgDelayTime" BO_ 2025 20;
BA_ "GenMsgNrOfRepetitions" BO_ 2025 2;
BA_ "GenMsgStartValue" BO_ 2025 "0000000000000000h";
BA_ "GenSigSendType" SG_ 1099 VC_BU_VehCfg5_Stat 1;
BA_ "FlexKomSigStartValue" SG_ 1099 VC_BU_VehCfg5_Stat "C3FFFFFFFFFFFF00h";
BA_ "GenSigStartValue" SG_ 1099 VC_BU_VehCfg5_Stat 3;
BA_ "FlexKomSID" SG_ 1099 VC_BU_VehCfg5_Stat 1196;
BA_ "FlexKomSigStartPos" SG_ 1099 VC_BU_VehCfg5_Stat 7;
BA_ "FlexKomSigLaenge" SG_ 1099 VC_BU_VehCfg5_Stat 64;
BA_ "FlexKomSigName" SG_ 1099 VC_BU_VehCfg5_Stat "VehCfgBU5_Pkt";
BA_ "FlexKomComment" SG_ 1099 VC_BU_VehCfg5_Stat "Backup for Vehicle Configuration 5 Packet";
BA_ "FlexKomIsMotorola" SG_ 1099 VC_BU_VehCfg5_Stat 1;
BA_ "GenSigSNA" SG_ 1099 VC_BU_VehCfg5_Stat "3h";
BA_ "GenSigSendType" SG_ 1099 VC_BU_LUCI_PRSNT 1;
BA_ "FlexKomSigStartValue" SG_ 1099 VC_BU_LUCI_PRSNT "C3FFFFFFFFFFFF00h";
BA_ "FlexKomSID" SG_ 1099 VC_BU_LUCI_PRSNT 1196;
BA_ "FlexKomSigStartPos" SG_ 1099 VC_BU_LUCI_PRSNT 7;
BA_ "FlexKomSigLaenge" SG_ 1099 VC_BU_LUCI_PRSNT 64;
BA_ "FlexKomSigName" SG_ 1099 VC_BU_LUCI_PRSNT "VehCfgBU5_Pkt";
BA_ "FlexKomComment" SG_ 1099 VC_BU_LUCI_PRSNT "Backup for Vehicle Configuration 5 Packet";
BA_ "FlexKomIsMotorola" SG_ 1099 VC_BU_LUCI_PRSNT 1;
BA_ "GenSigSNA" SG_ 1099 VC_BU_LUCI_PRSNT "0h";
BA_ "GenSigSendType" SG_ 1099 VC_BU_RR_DuallyPrsnt 1;
BA_ "FlexKomSigStartValue" SG_ 1099 VC_BU_RR_DuallyPrsnt "C3FFFFFFFFFFFF00h";
BA_ "FlexKomSID" SG_ 1099 VC_BU_RR_DuallyPrsnt 1196;
BA_ "FlexKomSigStartPos" SG_ 1099 VC_BU_RR_DuallyPrsnt 7;
BA_ "FlexKomSigLaenge" SG_ 1099 VC_BU_RR_DuallyPrsnt 64;
BA_ "FlexKomSigName" SG_ 1099 VC_BU_RR_DuallyPrsnt "VehCfgBU5_Pkt";
BA_ "FlexKomComment" SG_ 1099 VC_BU_RR_DuallyPrsnt "Backup for Vehicle Configuration 5 Packet";
BA_ "FlexKomIsMotorola" SG_ 1099 VC_BU_RR_DuallyPrsnt 1;
BA_ "GenSigSNA" SG_ 1099 VC_BU_RR_DuallyPrsnt "0h";
BA_ "GenSigSendType" SG_ 1099 VC_BU_NonReg_TPIS 1;
BA_ "FlexKomSigStartValue" SG_ 1099 VC_BU_NonReg_TPIS "C3FFFFFFFFFFFF00h";
BA_ "FlexKomSID" SG_ 1099 VC_BU_NonReg_TPIS 1196;
BA_ "FlexKomSigStartPos" SG_ 1099 VC_BU_NonReg_TPIS 7;
BA_ "FlexKomSigLaenge" SG_ 1099 VC_BU_NonReg_TPIS 64;
BA_ "FlexKomSigName" SG_ 1099 VC_BU_NonReg_TPIS "VehCfgBU5_Pkt";
BA_ "FlexKomComment" SG_ 1099 VC_BU_NonReg_TPIS "Backup for Vehicle Configuration 5 Packet";
BA_ "FlexKomIsMotorola" SG_ 1099 VC_BU_NonReg_TPIS 1;
BA_ "GenSigSNA" SG_ 1099 VC_BU_NonReg_TPIS "0h";
BA_ "GenSigSendType" SG_ 1099 VC_BU_WTS_Prsnt 1;
BA_ "FlexKomSigStartValue" SG_ 1099 VC_BU_WTS_Prsnt "C3FFFFFFFFFFFF00h";
BA_ "FlexKomSID" SG_ 1099 VC_BU_WTS_Prsnt 1196;
BA_ "FlexKomSigStartPos" SG_ 1099 VC_BU_WTS_Prsnt 7;
BA_ "FlexKomSigLaenge" SG_ 1099 VC_BU_WTS_Prsnt 64;
BA_ "FlexKomSigName" SG_ 1099 VC_BU_WTS_Prsnt "VehCfgBU5_Pkt";
BA_ "FlexKomComment" SG_ 1099 VC_BU_WTS_Prsnt "Backup for Vehicle Configuration 5 Packet";
BA_ "FlexKomIsMotorola" SG_ 1099 VC_BU_WTS_Prsnt 1;
BA_ "GenSigSNA" SG_ 1099 VC_BU_WTS_Prsnt "0h";
BA_ "GenSigSendType" SG_ 1099 VC_BU_AmbTempLct 1;
BA_ "FlexKomSigStartValue" SG_ 1099 VC_BU_AmbTempLct "C3FFFFFFFFFFFF00h";
BA_ "GenSigStartValue" SG_ 1099 VC_BU_AmbTempLct 3;
BA_ "FlexKomSID" SG_ 1099 VC_BU_AmbTempLct 1196;
BA_ "FlexKomSigStartPos" SG_ 1099 VC_BU_AmbTempLct 7;
BA_ "FlexKomSigLaenge" SG_ 1099 VC_BU_AmbTempLct 64;
BA_ "FlexKomSigName" SG_ 1099 VC_BU_AmbTempLct "VehCfgBU5_Pkt";
BA_ "FlexKomComment" SG_ 1099 VC_BU_AmbTempLct "Backup for Vehicle Configuration 5 Packet";
BA_ "FlexKomIsMotorola" SG_ 1099 VC_BU_AmbTempLct 1;
BA_ "GenSigSNA" SG_ 1099 VC_BU_AmbTempLct "3h";
BA_ "GenSigSendType" SG_ 1099 VC_BU_Strng_Rt_0 1;
BA_ "FlexKomSigStartValue" SG_ 1099 VC_BU_Strng_Rt_0 "C3FFFFFFFFFFFF00h";
BA_ "GenSigStartValue" SG_ 1099 VC_BU_Strng_Rt_0 255;
BA_ "FlexKomSID" SG_ 1099 VC_BU_Strng_Rt_0 1196;
BA_ "FlexKomSigStartPos" SG_ 1099 VC_BU_Strng_Rt_0 7;
BA_ "FlexKomSigLaenge" SG_ 1099 VC_BU_Strng_Rt_0 64;
BA_ "FlexKomSigName" SG_ 1099 VC_BU_Strng_Rt_0 "VehCfgBU5_Pkt";
BA_ "FlexKomComment" SG_ 1099 VC_BU_Strng_Rt_0 "Backup for Vehicle Configuration 5 Packet";
BA_ "FlexKomIsMotorola" SG_ 1099 VC_BU_Strng_Rt_0 1;
BA_ "GenSigSNA" SG_ 1099 VC_BU_Strng_Rt_0 "FFh";
BA_ "GenSigSendType" SG_ 1099 VC_BU_Strng_Rt_pls1 1;
BA_ "FlexKomSigStartValue" SG_ 1099 VC_BU_Strng_Rt_pls1 "C3FFFFFFFFFFFF00h";
BA_ "GenSigStartValue" SG_ 1099 VC_BU_Strng_Rt_pls1 255;
BA_ "FlexKomSID" SG_ 1099 VC_BU_Strng_Rt_pls1 1196;
BA_ "FlexKomSigStartPos" SG_ 1099 VC_BU_Strng_Rt_pls1 7;
BA_ "FlexKomSigLaenge" SG_ 1099 VC_BU_Strng_Rt_pls1 64;
BA_ "FlexKomSigName" SG_ 1099 VC_BU_Strng_Rt_pls1 "VehCfgBU5_Pkt";
BA_ "FlexKomComment" SG_ 1099 VC_BU_Strng_Rt_pls1 "Backup for Vehicle Configuration 5 Packet";
BA_ "FlexKomIsMotorola" SG_ 1099 VC_BU_Strng_Rt_pls1 1;
BA_ "GenSigSNA" SG_ 1099 VC_BU_Strng_Rt_pls1 "FFh";
BA_ "GenSigSendType" SG_ 1099 VC_BU_Strng_Rt_pls2 1;
BA_ "FlexKomSigStartValue" SG_ 1099 VC_BU_Strng_Rt_pls2 "C3FFFFFFFFFFFF00h";
BA_ "GenSigStartValue" SG_ 1099 VC_BU_Strng_Rt_pls2 255;
BA_ "FlexKomSID" SG_ 1099 VC_BU_Strng_Rt_pls2 1196;
BA_ "FlexKomSigStartPos" SG_ 1099 VC_BU_Strng_Rt_pls2 7;
BA_ "FlexKomSigLaenge" SG_ 1099 VC_BU_Strng_Rt_pls2 64;
BA_ "FlexKomSigName" SG_ 1099 VC_BU_Strng_Rt_pls2 "VehCfgBU5_Pkt";
BA_ "FlexKomComment" SG_ 1099 VC_BU_Strng_Rt_pls2 "Backup for Vehicle Configuration 5 Packet";
BA_ "FlexKomIsMotorola" SG_ 1099 VC_BU_Strng_Rt_pls2 1;
BA_ "GenSigSNA" SG_ 1099 VC_BU_Strng_Rt_pls2 "FFh";
BA_ "GenSigSendType" SG_ 1099 VC_BU_Strng_Rt_pls3 1;
BA_ "FlexKomSigStartValue" SG_ 1099 VC_BU_Strng_Rt_pls3 "C3FFFFFFFFFFFF00h";
BA_ "GenSigStartValue" SG_ 1099 VC_BU_Strng_Rt_pls3 255;
BA_ "FlexKomSID" SG_ 1099 VC_BU_Strng_Rt_pls3 1196;
BA_ "FlexKomSigStartPos" SG_ 1099 VC_BU_Strng_Rt_pls3 7;
BA_ "FlexKomSigLaenge" SG_ 1099 VC_BU_Strng_Rt_pls3 64;
BA_ "FlexKomSigName" SG_ 1099 VC_BU_Strng_Rt_pls3 "VehCfgBU5_Pkt";
BA_ "FlexKomComment" SG_ 1099 VC_BU_Strng_Rt_pls3 "Backup for Vehicle Configuration 5 Packet";
BA_ "FlexKomIsMotorola" SG_ 1099 VC_BU_Strng_Rt_pls3 1;
BA_ "GenSigSNA" SG_ 1099 VC_BU_Strng_Rt_pls3 "FFh";
BA_ "GenSigSendType" SG_ 1099 VC_BU_Strng_Rt_pls4 1;
BA_ "FlexKomSigStartValue" SG_ 1099 VC_BU_Strng_Rt_pls4 "C3FFFFFFFFFFFF00h";
BA_ "GenSigStartValue" SG_ 1099 VC_BU_Strng_Rt_pls4 255;
BA_ "FlexKomSID" SG_ 1099 VC_BU_Strng_Rt_pls4 1196;
BA_ "FlexKomSigStartPos" SG_ 1099 VC_BU_Strng_Rt_pls4 7;
BA_ "FlexKomSigLaenge" SG_ 1099 VC_BU_Strng_Rt_pls4 64;
BA_ "FlexKomSigName" SG_ 1099 VC_BU_Strng_Rt_pls4 "VehCfgBU5_Pkt";
BA_ "FlexKomComment" SG_ 1099 VC_BU_Strng_Rt_pls4 "Backup for Vehicle Configuration 5 Packet";
BA_ "FlexKomIsMotorola" SG_ 1099 VC_BU_Strng_Rt_pls4 1;
BA_ "GenSigSNA" SG_ 1099 VC_BU_Strng_Rt_pls4 "FFh";
BA_ "GenSigSendType" SG_ 1099 VC_BU_Strng_Rt_pls5 1;
BA_ "FlexKomSigStartValue" SG_ 1099 VC_BU_Strng_Rt_pls5 "C3FFFFFFFFFFFF00h";
BA_ "GenSigStartValue" SG_ 1099 VC_BU_Strng_Rt_pls5 255;
BA_ "FlexKomSID" SG_ 1099 VC_BU_Strng_Rt_pls5 1196;
BA_ "FlexKomSigStartPos" SG_ 1099 VC_BU_Strng_Rt_pls5 7;
BA_ "FlexKomSigLaenge" SG_ 1099 VC_BU_Strng_Rt_pls5 64;
BA_ "FlexKomSigName" SG_ 1099 VC_BU_Strng_Rt_pls5 "VehCfgBU5_Pkt";
BA_ "FlexKomComment" SG_ 1099 VC_BU_Strng_Rt_pls5 "Backup for Vehicle Configuration 5 Packet";
BA_ "FlexKomIsMotorola" SG_ 1099 VC_BU_Strng_Rt_pls5 1;
BA_ "GenSigSNA" SG_ 1099 VC_BU_Strng_Rt_pls5 "FFh";
BA_ "GenSigSendType" SG_ 1099 VC_BU_RearDoorLocks2DCM 1;
BA_ "FlexKomSigStartValue" SG_ 1099 VC_BU_RearDoorLocks2DCM "C3FFFFFFFFFFFF00h";
BA_ "FlexKomSID" SG_ 1099 VC_BU_RearDoorLocks2DCM 1196;
BA_ "FlexKomSigStartPos" SG_ 1099 VC_BU_RearDoorLocks2DCM 7;
BA_ "FlexKomSigLaenge" SG_ 1099 VC_BU_RearDoorLocks2DCM 64;
BA_ "FlexKomSigName" SG_ 1099 VC_BU_RearDoorLocks2DCM "VehCfgBU5_Pkt";
BA_ "FlexKomComment" SG_ 1099 VC_BU_RearDoorLocks2DCM "Backup for Vehicle Configuration 5 Packet";
BA_ "FlexKomIsMotorola" SG_ 1099 VC_BU_RearDoorLocks2DCM 1;
BA_ "GenSigSNA" SG_ 1099 VC_BU_RearDoorLocks2DCM "0h";
BA_ "GenSigSendType" SG_ 1099 VC_BU_SpdLmt_PRSNT 1;
BA_ "FlexKomSigStartValue" SG_ 1099 VC_BU_SpdLmt_PRSNT "C3FFFFFFFFFFFF00h";
BA_ "FlexKomSID" SG_ 1099 VC_BU_SpdLmt_PRSNT 1196;
BA_ "FlexKomSigStartPos" SG_ 1099 VC_BU_SpdLmt_PRSNT 7;
BA_ "FlexKomSigLaenge" SG_ 1099 VC_BU_SpdLmt_PRSNT 64;
BA_ "FlexKomSigName" SG_ 1099 VC_BU_SpdLmt_PRSNT "VehCfgBU5_Pkt";
BA_ "FlexKomComment" SG_ 1099 VC_BU_SpdLmt_PRSNT "Backup for Vehicle Configuration 5 Packet";
BA_ "FlexKomIsMotorola" SG_ 1099 VC_BU_SpdLmt_PRSNT 1;
BA_ "GenSigSNA" SG_ 1099 VC_BU_SpdLmt_PRSNT "0h";
BA_ "GenSigSendType" SG_ 1099 VC_BU_SBR_Prsnt 1;
BA_ "FlexKomSigStartValue" SG_ 1099 VC_BU_SBR_Prsnt "C3FFFFFFFFFFFF00h";
BA_ "FlexKomSID" SG_ 1099 VC_BU_SBR_Prsnt 1196;
BA_ "FlexKomSigStartPos" SG_ 1099 VC_BU_SBR_Prsnt 7;
BA_ "FlexKomSigLaenge" SG_ 1099 VC_BU_SBR_Prsnt 64;
BA_ "FlexKomSigName" SG_ 1099 VC_BU_SBR_Prsnt "VehCfgBU5_Pkt";
BA_ "FlexKomComment" SG_ 1099 VC_BU_SBR_Prsnt "Backup for Vehicle Configuration 5 Packet";
BA_ "FlexKomIsMotorola" SG_ 1099 VC_BU_SBR_Prsnt 1;
BA_ "GenSigSNA" SG_ 1099 VC_BU_SBR_Prsnt "0h";
BA_ "GenSigSendType" SG_ 1099 VC_BU_ChildDisp_Prsnt 1;
BA_ "FlexKomSigStartValue" SG_ 1099 VC_BU_ChildDisp_Prsnt "C3FFFFFFFFFFFF00h";
BA_ "FlexKomSID" SG_ 1099 VC_BU_ChildDisp_Prsnt 1196;
BA_ "FlexKomSigStartPos" SG_ 1099 VC_BU_ChildDisp_Prsnt 7;
BA_ "FlexKomSigLaenge" SG_ 1099 VC_BU_ChildDisp_Prsnt 64;
BA_ "FlexKomSigName" SG_ 1099 VC_BU_ChildDisp_Prsnt "VehCfgBU5_Pkt";
BA_ "FlexKomComment" SG_ 1099 VC_BU_ChildDisp_Prsnt "Backup for Vehicle Configuration 5 Packet";
BA_ "FlexKomIsMotorola" SG_ 1099 VC_BU_ChildDisp_Prsnt 1;
BA_ "GenSigSNA" SG_ 1099 VC_BU_ChildDisp_Prsnt "0h";
BA_ "GenSigSendType" SG_ 1099 VC_BU_OffRoadPg 1;
BA_ "FlexKomSigStartValue" SG_ 1099 VC_BU_OffRoadPg "C3FFFFFFFFFFFF00h";
BA_ "FlexKomSID" SG_ 1099 VC_BU_OffRoadPg 1196;
BA_ "FlexKomSigStartPos" SG_ 1099 VC_BU_OffRoadPg 7;
BA_ "FlexKomSigLaenge" SG_ 1099 VC_BU_OffRoadPg 64;
BA_ "FlexKomSigName" SG_ 1099 VC_BU_OffRoadPg "VehCfgBU5_Pkt";
BA_ "FlexKomComment" SG_ 1099 VC_BU_OffRoadPg "Backup for Vehicle Configuration 5 Packet";
BA_ "FlexKomIsMotorola" SG_ 1099 VC_BU_OffRoadPg 1;
BA_ "GenSigSNA" SG_ 1099 VC_BU_OffRoadPg "0h";
BA_ "GenSigSendType" SG_ 1099 VC_BU_AmbLtgPrsnt 1;
BA_ "FlexKomSigStartValue" SG_ 1099 VC_BU_AmbLtgPrsnt "C3FFFFFFFFFFFF00h";
BA_ "FlexKomSID" SG_ 1099 VC_BU_AmbLtgPrsnt 1196;
BA_ "FlexKomSigStartPos" SG_ 1099 VC_BU_AmbLtgPrsnt 7;
BA_ "FlexKomSigLaenge" SG_ 1099 VC_BU_AmbLtgPrsnt 64;
BA_ "FlexKomSigName" SG_ 1099 VC_BU_AmbLtgPrsnt "VehCfgBU5_Pkt";
BA_ "FlexKomComment" SG_ 1099 VC_BU_AmbLtgPrsnt "Backup for Vehicle Configuration 5 Packet";
BA_ "FlexKomIsMotorola" SG_ 1099 VC_BU_AmbLtgPrsnt 1;
BA_ "GenSigSNA" SG_ 1099 VC_BU_AmbLtgPrsnt "0h";
BA_ "GenSigSendType" SG_ 1099 VC_BU_PPPA_Prsnt 1;
BA_ "FlexKomSigStartValue" SG_ 1099 VC_BU_PPPA_Prsnt "C3FFFFFFFFFFFF00h";
BA_ "FlexKomSID" SG_ 1099 VC_BU_PPPA_Prsnt 1196;
BA_ "FlexKomSigStartPos" SG_ 1099 VC_BU_PPPA_Prsnt 7;
BA_ "FlexKomSigLaenge" SG_ 1099 VC_BU_PPPA_Prsnt 64;
BA_ "FlexKomSigName" SG_ 1099 VC_BU_PPPA_Prsnt "VehCfgBU5_Pkt";
BA_ "FlexKomComment" SG_ 1099 VC_BU_PPPA_Prsnt "Backup for Vehicle Configuration 5 Packet";
BA_ "FlexKomIsMotorola" SG_ 1099 VC_BU_PPPA_Prsnt 1;
BA_ "GenSigSNA" SG_ 1099 VC_BU_PPPA_Prsnt "0h";
BA_ "GenSigSendType" SG_ 1099 VC_BU_ParkStopPrsnt 1;
BA_ "FlexKomSigStartValue" SG_ 1099 VC_BU_ParkStopPrsnt "C3FFFFFFFFFFFF00h";
BA_ "FlexKomSID" SG_ 1099 VC_BU_ParkStopPrsnt 1196;
BA_ "FlexKomSigStartPos" SG_ 1099 VC_BU_ParkStopPrsnt 7;
BA_ "FlexKomSigLaenge" SG_ 1099 VC_BU_ParkStopPrsnt 64;
BA_ "FlexKomSigName" SG_ 1099 VC_BU_ParkStopPrsnt "VehCfgBU5_Pkt";
BA_ "FlexKomComment" SG_ 1099 VC_BU_ParkStopPrsnt "Backup for Vehicle Configuration 5 Packet";
BA_ "FlexKomIsMotorola" SG_ 1099 VC_BU_ParkStopPrsnt 1;
BA_ "GenSigSNA" SG_ 1099 VC_BU_ParkStopPrsnt "0h";
BA_ "GenSigSendType" SG_ 1100 VC_VehCfg6_Stat 5;
BA_ "GenSigCycleTime" SG_ 1100 VC_VehCfg6_Stat 2000;
BA_ "FlexKomSigStartValue" SG_ 1100 VC_VehCfg6_Stat "73FFFFFFFFFFFFFFh";
BA_ "GenSigStartValue" SG_ 1100 VC_VehCfg6_Stat 3;
BA_ "GenSigTimeout_ORC" SG_ 1100 VC_VehCfg6_Stat 7000;
BA_ "FlexKomSID" SG_ 1100 VC_VehCfg6_Stat 1199;
BA_ "FlexKomSigStartPos" SG_ 1100 VC_VehCfg6_Stat 7;
BA_ "FlexKomSigLaenge" SG_ 1100 VC_VehCfg6_Stat 64;
BA_ "FlexKomSigName" SG_ 1100 VC_VehCfg6_Stat "VehCfg6_Pkt";
BA_ "FlexKomComment" SG_ 1100 VC_VehCfg6_Stat "Vehicle Configuration 6 Packet";
BA_ "FlexKomIsMotorola" SG_ 1100 VC_VehCfg6_Stat 1;
BA_ "GenSigSNA" SG_ 1100 VC_VehCfg6_Stat "3h";
BA_ "GenSigSendType" SG_ 1100 VC_AnlgDrSnsr 5;
BA_ "GenSigCycleTime" SG_ 1100 VC_AnlgDrSnsr 2000;
BA_ "FlexKomSigStartValue" SG_ 1100 VC_AnlgDrSnsr "73FFFFFFFFFFFFFFh";
BA_ "FlexKomSID" SG_ 1100 VC_AnlgDrSnsr 1199;
BA_ "FlexKomSigStartPos" SG_ 1100 VC_AnlgDrSnsr 7;
BA_ "FlexKomSigLaenge" SG_ 1100 VC_AnlgDrSnsr 64;
BA_ "FlexKomSigName" SG_ 1100 VC_AnlgDrSnsr "VehCfg6_Pkt";
BA_ "FlexKomComment" SG_ 1100 VC_AnlgDrSnsr "Vehicle Configuration 6 Packet";
BA_ "FlexKomIsMotorola" SG_ 1100 VC_AnlgDrSnsr 1;
BA_ "GenSigSNA" SG_ 1100 VC_AnlgDrSnsr "0h";
BA_ "GenSigSendType" SG_ 1100 VC_BrkTyp 5;
BA_ "GenSigCycleTime" SG_ 1100 VC_BrkTyp 2000;
BA_ "FlexKomSigStartValue" SG_ 1100 VC_BrkTyp "73FFFFFFFFFFFFFFh";
BA_ "GenSigStartValue" SG_ 1100 VC_BrkTyp 7;
BA_ "FlexKomSID" SG_ 1100 VC_BrkTyp 1199;
BA_ "FlexKomSigStartPos" SG_ 1100 VC_BrkTyp 7;
BA_ "FlexKomSigLaenge" SG_ 1100 VC_BrkTyp 64;
BA_ "FlexKomSigName" SG_ 1100 VC_BrkTyp "VehCfg6_Pkt";
BA_ "FlexKomComment" SG_ 1100 VC_BrkTyp "Vehicle Configuration 6 Packet";
BA_ "FlexKomIsMotorola" SG_ 1100 VC_BrkTyp 1;
BA_ "GenSigSNA" SG_ 1100 VC_BrkTyp "7h";
BA_ "GenSigSendType" SG_ 1100 VC_AQS_Prsnt 5;
BA_ "GenSigCycleTime" SG_ 1100 VC_AQS_Prsnt 2000;
BA_ "FlexKomSigStartValue" SG_ 1100 VC_AQS_Prsnt "73FFFFFFFFFFFFFFh";
BA_ "FlexKomSID" SG_ 1100 VC_AQS_Prsnt 1199;
BA_ "FlexKomSigStartPos" SG_ 1100 VC_AQS_Prsnt 7;
BA_ "FlexKomSigLaenge" SG_ 1100 VC_AQS_Prsnt 64;
BA_ "FlexKomSigName" SG_ 1100 VC_AQS_Prsnt "VehCfg6_Pkt";
BA_ "FlexKomComment" SG_ 1100 VC_AQS_Prsnt "Vehicle Configuration 6 Packet";
BA_ "FlexKomIsMotorola" SG_ 1100 VC_AQS_Prsnt 1;
BA_ "GenSigSNA" SG_ 1100 VC_AQS_Prsnt "0h";
BA_ "GenSigSendType" SG_ 1100 VC_Strng_Rt_Mns1 5;
BA_ "GenSigCycleTime" SG_ 1100 VC_Strng_Rt_Mns1 2000;
BA_ "FlexKomSigStartValue" SG_ 1100 VC_Strng_Rt_Mns1 "73FFFFFFFFFFFFFFh";
BA_ "GenSigStartValue" SG_ 1100 VC_Strng_Rt_Mns1 255;
BA_ "FlexKomSID" SG_ 1100 VC_Strng_Rt_Mns1 1199;
BA_ "FlexKomSigStartPos" SG_ 1100 VC_Strng_Rt_Mns1 7;
BA_ "FlexKomSigLaenge" SG_ 1100 VC_Strng_Rt_Mns1 64;
BA_ "FlexKomSigName" SG_ 1100 VC_Strng_Rt_Mns1 "VehCfg6_Pkt";
BA_ "FlexKomComment" SG_ 1100 VC_Strng_Rt_Mns1 "Vehicle Configuration 6 Packet";
BA_ "FlexKomIsMotorola" SG_ 1100 VC_Strng_Rt_Mns1 1;
BA_ "GenSigSNA" SG_ 1100 VC_Strng_Rt_Mns1 "FFh";
BA_ "GenSigSendType" SG_ 1100 VC_Strng_Rt_Mns2 5;
BA_ "GenSigCycleTime" SG_ 1100 VC_Strng_Rt_Mns2 2000;
BA_ "FlexKomSigStartValue" SG_ 1100 VC_Strng_Rt_Mns2 "73FFFFFFFFFFFFFFh";
BA_ "GenSigStartValue" SG_ 1100 VC_Strng_Rt_Mns2 255;
BA_ "FlexKomSID" SG_ 1100 VC_Strng_Rt_Mns2 1199;
BA_ "FlexKomSigStartPos" SG_ 1100 VC_Strng_Rt_Mns2 7;
BA_ "FlexKomSigLaenge" SG_ 1100 VC_Strng_Rt_Mns2 64;
BA_ "FlexKomSigName" SG_ 1100 VC_Strng_Rt_Mns2 "VehCfg6_Pkt";
BA_ "FlexKomComment" SG_ 1100 VC_Strng_Rt_Mns2 "Vehicle Configuration 6 Packet";
BA_ "FlexKomIsMotorola" SG_ 1100 VC_Strng_Rt_Mns2 1;
BA_ "GenSigSNA" SG_ 1100 VC_Strng_Rt_Mns2 "FFh";
BA_ "GenSigSendType" SG_ 1100 VC_Strng_Rt_Mns3 5;
BA_ "GenSigCycleTime" SG_ 1100 VC_Strng_Rt_Mns3 2000;
BA_ "FlexKomSigStartValue" SG_ 1100 VC_Strng_Rt_Mns3 "73FFFFFFFFFFFFFFh";
BA_ "GenSigStartValue" SG_ 1100 VC_Strng_Rt_Mns3 255;
BA_ "FlexKomSID" SG_ 1100 VC_Strng_Rt_Mns3 1199;
BA_ "FlexKomSigStartPos" SG_ 1100 VC_Strng_Rt_Mns3 7;
BA_ "FlexKomSigLaenge" SG_ 1100 VC_Strng_Rt_Mns3 64;
BA_ "FlexKomSigName" SG_ 1100 VC_Strng_Rt_Mns3 "VehCfg6_Pkt";
BA_ "FlexKomComment" SG_ 1100 VC_Strng_Rt_Mns3 "Vehicle Configuration 6 Packet";
BA_ "FlexKomIsMotorola" SG_ 1100 VC_Strng_Rt_Mns3 1;
BA_ "GenSigSNA" SG_ 1100 VC_Strng_Rt_Mns3 "FFh";
BA_ "GenSigSendType" SG_ 1100 VC_Strng_Rt_Mns4 5;
BA_ "GenSigCycleTime" SG_ 1100 VC_Strng_Rt_Mns4 2000;
BA_ "FlexKomSigStartValue" SG_ 1100 VC_Strng_Rt_Mns4 "73FFFFFFFFFFFFFFh";
BA_ "GenSigStartValue" SG_ 1100 VC_Strng_Rt_Mns4 255;
BA_ "FlexKomSID" SG_ 1100 VC_Strng_Rt_Mns4 1199;
BA_ "FlexKomSigStartPos" SG_ 1100 VC_Strng_Rt_Mns4 7;
BA_ "FlexKomSigLaenge" SG_ 1100 VC_Strng_Rt_Mns4 64;
BA_ "FlexKomSigName" SG_ 1100 VC_Strng_Rt_Mns4 "VehCfg6_Pkt";
BA_ "FlexKomComment" SG_ 1100 VC_Strng_Rt_Mns4 "Vehicle Configuration 6 Packet";
BA_ "FlexKomIsMotorola" SG_ 1100 VC_Strng_Rt_Mns4 1;
BA_ "GenSigSNA" SG_ 1100 VC_Strng_Rt_Mns4 "FFh";
BA_ "GenSigSendType" SG_ 1100 VC_Strng_Rt_Mns5 5;
BA_ "GenSigCycleTime" SG_ 1100 VC_Strng_Rt_Mns5 2000;
BA_ "FlexKomSigStartValue" SG_ 1100 VC_Strng_Rt_Mns5 "73FFFFFFFFFFFFFFh";
BA_ "GenSigStartValue" SG_ 1100 VC_Strng_Rt_Mns5 255;
BA_ "FlexKomSID" SG_ 1100 VC_Strng_Rt_Mns5 1199;
BA_ "FlexKomSigStartPos" SG_ 1100 VC_Strng_Rt_Mns5 7;
BA_ "FlexKomSigLaenge" SG_ 1100 VC_Strng_Rt_Mns5 64;
BA_ "FlexKomSigName" SG_ 1100 VC_Strng_Rt_Mns5 "VehCfg6_Pkt";
BA_ "FlexKomComment" SG_ 1100 VC_Strng_Rt_Mns5 "Vehicle Configuration 6 Packet";
BA_ "FlexKomIsMotorola" SG_ 1100 VC_Strng_Rt_Mns5 1;
BA_ "GenSigSNA" SG_ 1100 VC_Strng_Rt_Mns5 "FFh";
BA_ "GenSigSendType" SG_ 1100 VC_TireCircumfFT 5;
BA_ "GenSigCycleTime" SG_ 1100 VC_TireCircumfFT 2000;
BA_ "FlexKomSigStartValue" SG_ 1100 VC_TireCircumfFT "73FFFFFFFFFFFFFFh";
BA_ "GenSigStartValue" SG_ 1100 VC_TireCircumfFT 65535;
BA_ "GenSigTimeout_ORC" SG_ 1100 VC_TireCircumfFT 7000;
BA_ "FlexKomSID" SG_ 1100 VC_TireCircumfFT 1199;
BA_ "FlexKomSigStartPos" SG_ 1100 VC_TireCircumfFT 7;
BA_ "FlexKomSigLaenge" SG_ 1100 VC_TireCircumfFT 64;
BA_ "FlexKomSigName" SG_ 1100 VC_TireCircumfFT "VehCfg6_Pkt";
BA_ "FlexKomComment" SG_ 1100 VC_TireCircumfFT "Vehicle Configuration 6 Packet";
BA_ "FlexKomIsMotorola" SG_ 1100 VC_TireCircumfFT 1;
BA_ "GenSigSNA" SG_ 1100 VC_TireCircumfFT "FFFFh";
BA_ "GenSigSendType" SG_ 1101 VC_BU_VehCfg6_Stat 1;
BA_ "FlexKomSigStartValue" SG_ 1101 VC_BU_VehCfg6_Stat "73FFFFFFFFFFFFFFh";
BA_ "GenSigStartValue" SG_ 1101 VC_BU_VehCfg6_Stat 3;
BA_ "FlexKomSID" SG_ 1101 VC_BU_VehCfg6_Stat 1197;
BA_ "FlexKomSigStartPos" SG_ 1101 VC_BU_VehCfg6_Stat 7;
BA_ "FlexKomSigLaenge" SG_ 1101 VC_BU_VehCfg6_Stat 64;
BA_ "FlexKomSigName" SG_ 1101 VC_BU_VehCfg6_Stat "VehCfgBU6_Pkt";
BA_ "FlexKomComment" SG_ 1101 VC_BU_VehCfg6_Stat "Backup for Vehicle Configuration 6 Packet";
BA_ "FlexKomIsMotorola" SG_ 1101 VC_BU_VehCfg6_Stat 1;
BA_ "GenSigSNA" SG_ 1101 VC_BU_VehCfg6_Stat "3h";
BA_ "GenSigSendType" SG_ 1101 VC_BU_AnlgDrSnsr 1;
BA_ "FlexKomSigStartValue" SG_ 1101 VC_BU_AnlgDrSnsr "73FFFFFFFFFFFFFFh";
BA_ "FlexKomSID" SG_ 1101 VC_BU_AnlgDrSnsr 1197;
BA_ "FlexKomSigStartPos" SG_ 1101 VC_BU_AnlgDrSnsr 7;
BA_ "FlexKomSigLaenge" SG_ 1101 VC_BU_AnlgDrSnsr 64;
BA_ "FlexKomSigName" SG_ 1101 VC_BU_AnlgDrSnsr "VehCfgBU6_Pkt";
BA_ "FlexKomComment" SG_ 1101 VC_BU_AnlgDrSnsr "Backup for Vehicle Configuration 6 Packet";
BA_ "FlexKomIsMotorola" SG_ 1101 VC_BU_AnlgDrSnsr 1;
BA_ "GenSigSNA" SG_ 1101 VC_BU_AnlgDrSnsr "0h";
BA_ "GenSigSendType" SG_ 1101 VC_BU_BrkTyp 1;
BA_ "FlexKomSigStartValue" SG_ 1101 VC_BU_BrkTyp "73FFFFFFFFFFFFFFh";
BA_ "GenSigStartValue" SG_ 1101 VC_BU_BrkTyp 7;
BA_ "FlexKomSID" SG_ 1101 VC_BU_BrkTyp 1197;
BA_ "FlexKomSigStartPos" SG_ 1101 VC_BU_BrkTyp 7;
BA_ "FlexKomSigLaenge" SG_ 1101 VC_BU_BrkTyp 64;
BA_ "FlexKomSigName" SG_ 1101 VC_BU_BrkTyp "VehCfgBU6_Pkt";
BA_ "FlexKomComment" SG_ 1101 VC_BU_BrkTyp "Backup for Vehicle Configuration 6 Packet";
BA_ "FlexKomIsMotorola" SG_ 1101 VC_BU_BrkTyp 1;
BA_ "GenSigSNA" SG_ 1101 VC_BU_BrkTyp "7h";
BA_ "GenSigSendType" SG_ 1101 VC_BU_AQS_Prsnt 1;
BA_ "FlexKomSigStartValue" SG_ 1101 VC_BU_AQS_Prsnt "73FFFFFFFFFFFFFFh";
BA_ "FlexKomSID" SG_ 1101 VC_BU_AQS_Prsnt 1197;
BA_ "FlexKomSigStartPos" SG_ 1101 VC_BU_AQS_Prsnt 7;
BA_ "FlexKomSigLaenge" SG_ 1101 VC_BU_AQS_Prsnt 64;
BA_ "FlexKomSigName" SG_ 1101 VC_BU_AQS_Prsnt "VehCfgBU6_Pkt";
BA_ "FlexKomComment" SG_ 1101 VC_BU_AQS_Prsnt "Backup for Vehicle Configuration 6 Packet";
BA_ "FlexKomIsMotorola" SG_ 1101 VC_BU_AQS_Prsnt 1;
BA_ "GenSigSNA" SG_ 1101 VC_BU_AQS_Prsnt "0h";
BA_ "GenSigSendType" SG_ 1101 VC_BU_Strng_Rt_Mns1 1;
BA_ "FlexKomSigStartValue" SG_ 1101 VC_BU_Strng_Rt_Mns1 "73FFFFFFFFFFFFFFh";
BA_ "GenSigStartValue" SG_ 1101 VC_BU_Strng_Rt_Mns1 255;
BA_ "FlexKomSID" SG_ 1101 VC_BU_Strng_Rt_Mns1 1197;
BA_ "FlexKomSigStartPos" SG_ 1101 VC_BU_Strng_Rt_Mns1 7;
BA_ "FlexKomSigLaenge" SG_ 1101 VC_BU_Strng_Rt_Mns1 64;
BA_ "FlexKomSigName" SG_ 1101 VC_BU_Strng_Rt_Mns1 "VehCfgBU6_Pkt";
BA_ "FlexKomComment" SG_ 1101 VC_BU_Strng_Rt_Mns1 "Backup for Vehicle Configuration 6 Packet";
BA_ "FlexKomIsMotorola" SG_ 1101 VC_BU_Strng_Rt_Mns1 1;
BA_ "GenSigSNA" SG_ 1101 VC_BU_Strng_Rt_Mns1 "FFh";
BA_ "GenSigSendType" SG_ 1101 VC_BU_Strng_Rt_Mns2 1;
BA_ "FlexKomSigStartValue" SG_ 1101 VC_BU_Strng_Rt_Mns2 "73FFFFFFFFFFFFFFh";
BA_ "GenSigStartValue" SG_ 1101 VC_BU_Strng_Rt_Mns2 255;
BA_ "FlexKomSID" SG_ 1101 VC_BU_Strng_Rt_Mns2 1197;
BA_ "FlexKomSigStartPos" SG_ 1101 VC_BU_Strng_Rt_Mns2 7;
BA_ "FlexKomSigLaenge" SG_ 1101 VC_BU_Strng_Rt_Mns2 64;
BA_ "FlexKomSigName" SG_ 1101 VC_BU_Strng_Rt_Mns2 "VehCfgBU6_Pkt";
BA_ "FlexKomComment" SG_ 1101 VC_BU_Strng_Rt_Mns2 "Backup for Vehicle Configuration 6 Packet";
BA_ "FlexKomIsMotorola" SG_ 1101 VC_BU_Strng_Rt_Mns2 1;
BA_ "GenSigSNA" SG_ 1101 VC_BU_Strng_Rt_Mns2 "FFh";
BA_ "GenSigSendType" SG_ 1101 VC_BU_Strng_Rt_Mns3 1;
BA_ "FlexKomSigStartValue" SG_ 1101 VC_BU_Strng_Rt_Mns3 "73FFFFFFFFFFFFFFh";
BA_ "GenSigStartValue" SG_ 1101 VC_BU_Strng_Rt_Mns3 255;
BA_ "FlexKomSID" SG_ 1101 VC_BU_Strng_Rt_Mns3 1197;
BA_ "FlexKomSigStartPos" SG_ 1101 VC_BU_Strng_Rt_Mns3 7;
BA_ "FlexKomSigLaenge" SG_ 1101 VC_BU_Strng_Rt_Mns3 64;
BA_ "FlexKomSigName" SG_ 1101 VC_BU_Strng_Rt_Mns3 "VehCfgBU6_Pkt";
BA_ "FlexKomComment" SG_ 1101 VC_BU_Strng_Rt_Mns3 "Backup for Vehicle Configuration 6 Packet";
BA_ "FlexKomIsMotorola" SG_ 1101 VC_BU_Strng_Rt_Mns3 1;
BA_ "GenSigSNA" SG_ 1101 VC_BU_Strng_Rt_Mns3 "FFh";
BA_ "GenSigSendType" SG_ 1101 VC_BU_Strng_Rt_Mns4 1;
BA_ "FlexKomSigStartValue" SG_ 1101 VC_BU_Strng_Rt_Mns4 "73FFFFFFFFFFFFFFh";
BA_ "GenSigStartValue" SG_ 1101 VC_BU_Strng_Rt_Mns4 255;
BA_ "FlexKomSID" SG_ 1101 VC_BU_Strng_Rt_Mns4 1197;
BA_ "FlexKomSigStartPos" SG_ 1101 VC_BU_Strng_Rt_Mns4 7;
BA_ "FlexKomSigLaenge" SG_ 1101 VC_BU_Strng_Rt_Mns4 64;
BA_ "FlexKomSigName" SG_ 1101 VC_BU_Strng_Rt_Mns4 "VehCfgBU6_Pkt";
BA_ "FlexKomComment" SG_ 1101 VC_BU_Strng_Rt_Mns4 "Backup for Vehicle Configuration 6 Packet";
BA_ "FlexKomIsMotorola" SG_ 1101 VC_BU_Strng_Rt_Mns4 1;
BA_ "GenSigSNA" SG_ 1101 VC_BU_Strng_Rt_Mns4 "FFh";
BA_ "GenSigSendType" SG_ 1101 VC_BU_Strng_Rt_Mns5 1;
BA_ "FlexKomSigStartValue" SG_ 1101 VC_BU_Strng_Rt_Mns5 "73FFFFFFFFFFFFFFh";
BA_ "GenSigStartValue" SG_ 1101 VC_BU_Strng_Rt_Mns5 255;
BA_ "FlexKomSID" SG_ 1101 VC_BU_Strng_Rt_Mns5 1197;
BA_ "FlexKomSigStartPos" SG_ 1101 VC_BU_Strng_Rt_Mns5 7;
BA_ "FlexKomSigLaenge" SG_ 1101 VC_BU_Strng_Rt_Mns5 64;
BA_ "FlexKomSigName" SG_ 1101 VC_BU_Strng_Rt_Mns5 "VehCfgBU6_Pkt";
BA_ "FlexKomComment" SG_ 1101 VC_BU_Strng_Rt_Mns5 "Backup for Vehicle Configuration 6 Packet";
BA_ "FlexKomIsMotorola" SG_ 1101 VC_BU_Strng_Rt_Mns5 1;
BA_ "GenSigSNA" SG_ 1101 VC_BU_Strng_Rt_Mns5 "FFh";
BA_ "GenSigSendType" SG_ 1101 VC_BU_TireCircumfFT 1;
BA_ "FlexKomSigStartValue" SG_ 1101 VC_BU_TireCircumfFT "73FFFFFFFFFFFFFFh";
BA_ "GenSigStartValue" SG_ 1101 VC_BU_TireCircumfFT 65535;
BA_ "FlexKomSID" SG_ 1101 VC_BU_TireCircumfFT 1197;
BA_ "FlexKomSigStartPos" SG_ 1101 VC_BU_TireCircumfFT 7;
BA_ "FlexKomSigLaenge" SG_ 1101 VC_BU_TireCircumfFT 64;
BA_ "FlexKomSigName" SG_ 1101 VC_BU_TireCircumfFT "VehCfgBU6_Pkt";
BA_ "FlexKomComment" SG_ 1101 VC_BU_TireCircumfFT "Backup for Vehicle Configuration 6 Packet";
BA_ "FlexKomIsMotorola" SG_ 1101 VC_BU_TireCircumfFT 1;
BA_ "GenSigSNA" SG_ 1101 VC_BU_TireCircumfFT "FFFFh";
BA_ "FlexKomSigStartValue" SG_ 1216 D_RS_RF_HUB "0000000000000000h";
BA_ "FlexKomSID" SG_ 1216 D_RS_RF_HUB 144;
BA_ "FlexKomSigStartPos" SG_ 1216 D_RS_RF_HUB 7;
BA_ "FlexKomSigLaenge" SG_ 1216 D_RS_RF_HUB 64;
BA_ "FlexKomSigName" SG_ 1216 D_RS_RF_HUB "D_RS_RF_HUB";
BA_ "FlexKomComment" SG_ 1216 D_RS_RF_HUB "Diagnostic-Response";
BA_ "FlexKomIsMotorola" SG_ 1216 D_RS_RF_HUB 1;
BA_ "GenSigSNA" SG_ 1216 D_RS_RF_HUB "0h";
BA_ "FlexKomSigStartValue" SG_ 1218 D_RS_IC "0000000000000000h";
BA_ "FlexKomSID" SG_ 1218 D_RS_IC 147;
BA_ "FlexKomSigStartPos" SG_ 1218 D_RS_IC 7;
BA_ "FlexKomSigLaenge" SG_ 1218 D_RS_IC 64;
BA_ "FlexKomSigName" SG_ 1218 D_RS_IC "D_RS_IC";
BA_ "FlexKomComment" SG_ 1218 D_RS_IC "Diagnostic-Response";
BA_ "FlexKomIsMotorola" SG_ 1218 D_RS_IC 1;
BA_ "GenSigSNA" SG_ 1218 D_RS_IC "0h";
BA_ "FlexKomSigStartValue" SG_ 1219 D_RS_TPM "0000000000000000h";
BA_ "FlexKomSID" SG_ 1219 D_RS_TPM 172;
BA_ "FlexKomSigStartPos" SG_ 1219 D_RS_TPM 7;
BA_ "FlexKomSigLaenge" SG_ 1219 D_RS_TPM 64;
BA_ "FlexKomSigName" SG_ 1219 D_RS_TPM "D_RS_TPM";
BA_ "FlexKomComment" SG_ 1219 D_RS_TPM "Diagnostic-Response";
BA_ "FlexKomIsMotorola" SG_ 1219 D_RS_TPM 1;
BA_ "GenSigSNA" SG_ 1219 D_RS_TPM "0h";
BA_ "FlexKomSigStartValue" SG_ 1220 D_RS_ORC "0000000000000000h";
BA_ "FlexKomSID" SG_ 1220 D_RS_ORC 153;
BA_ "FlexKomSigStartPos" SG_ 1220 D_RS_ORC 7;
BA_ "FlexKomSigLaenge" SG_ 1220 D_RS_ORC 64;
BA_ "FlexKomSigName" SG_ 1220 D_RS_ORC "D_RS_ORC";
BA_ "FlexKomComment" SG_ 1220 D_RS_ORC "Diagnostic-Response";
BA_ "FlexKomIsMotorola" SG_ 1220 D_RS_ORC 1;
BA_ "GenSigSNA" SG_ 1220 D_RS_ORC "0h";
BA_ "FlexKomSigStartValue" SG_ 1221 D_RS_RBT_DR "0000000000000000h";
BA_ "FlexKomSID" SG_ 1221 D_RS_RBT_DR 163;
BA_ "FlexKomSigStartPos" SG_ 1221 D_RS_RBT_DR 7;
BA_ "FlexKomSigLaenge" SG_ 1221 D_RS_RBT_DR 64;
BA_ "FlexKomSigName" SG_ 1221 D_RS_RBT_DR "D_RS_RBT_DR";
BA_ "FlexKomComment" SG_ 1221 D_RS_RBT_DR "Diagnostic-Response";
BA_ "FlexKomIsMotorola" SG_ 1221 D_RS_RBT_DR 1;
BA_ "GenSigSNA" SG_ 1221 D_RS_RBT_DR "0h";
BA_ "FlexKomSigStartValue" SG_ 1222 D_RS_RBT_PASS "0000000000000000h";
BA_ "FlexKomSID" SG_ 1222 D_RS_RBT_PASS 164;
BA_ "FlexKomSigStartPos" SG_ 1222 D_RS_RBT_PASS 7;
BA_ "FlexKomSigLaenge" SG_ 1222 D_RS_RBT_PASS 64;
BA_ "FlexKomSigName" SG_ 1222 D_RS_RBT_PASS "D_RS_RBT_PASS";
BA_ "FlexKomComment" SG_ 1222 D_RS_RBT_PASS "Diagnostic-Response";
BA_ "FlexKomIsMotorola" SG_ 1222 D_RS_RBT_PASS 1;
BA_ "GenSigSNA" SG_ 1222 D_RS_RBT_PASS "0h";
BA_ "FlexKomSigStartValue" SG_ 1223 D_RS_ESC "0000000000000000h";
BA_ "FlexKomSID" SG_ 1223 D_RS_ESC 15;
BA_ "FlexKomSigStartPos" SG_ 1223 D_RS_ESC 7;
BA_ "FlexKomSigLaenge" SG_ 1223 D_RS_ESC 64;
BA_ "FlexKomSigName" SG_ 1223 D_RS_ESC "D_RS_ESC";
BA_ "FlexKomComment" SG_ 1223 D_RS_ESC "Diagnostic-Response";
BA_ "FlexKomIsMotorola" SG_ 1223 D_RS_ESC 1;
BA_ "GenSigSNA" SG_ 1223 D_RS_ESC "0h";
BA_ "FlexKomSigStartValue" SG_ 1225 D_RS_ESM "0000000000000000h";
BA_ "FlexKomSID" SG_ 1225 D_RS_ESM 142;
BA_ "FlexKomSigStartPos" SG_ 1225 D_RS_ESM 7;
BA_ "FlexKomSigLaenge" SG_ 1225 D_RS_ESM 64;
BA_ "FlexKomSigName" SG_ 1225 D_RS_ESM "D_RS_ESM";
BA_ "FlexKomComment" SG_ 1225 D_RS_ESM "Diagnostic-Response";
BA_ "FlexKomIsMotorola" SG_ 1225 D_RS_ESM 1;
BA_ "GenSigSNA" SG_ 1225 D_RS_ESM "0h";
BA_ "FlexKomSigStartValue" SG_ 1227 D_RS_DTCM "0000000000000000h";
BA_ "FlexKomSID" SG_ 1227 D_RS_DTCM 138;
BA_ "FlexKomSigStartPos" SG_ 1227 D_RS_DTCM 7;
BA_ "FlexKomSigLaenge" SG_ 1227 D_RS_DTCM 64;
BA_ "FlexKomSigName" SG_ 1227 D_RS_DTCM "D_RS_DTCM";
BA_ "FlexKomComment" SG_ 1227 D_RS_DTCM "Diagnostic-Response";
BA_ "FlexKomIsMotorola" SG_ 1227 D_RS_DTCM 1;
BA_ "GenSigSNA" SG_ 1227 D_RS_DTCM "0h";
BA_ "FlexKomSigStartValue" SG_ 1228 D_RS_FDCM "0000000000000000h";
BA_ "FlexKomSID" SG_ 1228 D_RS_FDCM 1601;
BA_ "FlexKomSigStartPos" SG_ 1228 D_RS_FDCM 7;
BA_ "FlexKomSigLaenge" SG_ 1228 D_RS_FDCM 64;
BA_ "FlexKomSigName" SG_ 1228 D_RS_FDCM "D_RS_FDCM";
BA_ "FlexKomComment" SG_ 1228 D_RS_FDCM "Diagnostic-Response";
BA_ "FlexKomIsMotorola" SG_ 1228 D_RS_FDCM 1;
BA_ "GenSigSNA" SG_ 1228 D_RS_FDCM "0h";
BA_ "FlexKomSigStartValue" SG_ 1232 D_RS_SCRSM "0000000000000000h";
BA_ "FlexKomSID" SG_ 1232 D_RS_SCRSM 166;
BA_ "FlexKomSigStartPos" SG_ 1232 D_RS_SCRSM 7;
BA_ "FlexKomSigLaenge" SG_ 1232 D_RS_SCRSM 64;
BA_ "FlexKomSigName" SG_ 1232 D_RS_SCRSM "D_RS_SCRSM";
BA_ "FlexKomComment" SG_ 1232 D_RS_SCRSM "Diagnostic-Response";
BA_ "FlexKomIsMotorola" SG_ 1232 D_RS_SCRSM 1;
BA_ "GenSigSNA" SG_ 1232 D_RS_SCRSM "0h";
BA_ "FlexKomSigStartValue" SG_ 1235 D_RS_DASM "0000000000000000h";
BA_ "FlexKomSID" SG_ 1235 D_RS_DASM 149;
BA_ "FlexKomSigStartPos" SG_ 1235 D_RS_DASM 7;
BA_ "FlexKomSigLaenge" SG_ 1235 D_RS_DASM 64;
BA_ "FlexKomSigName" SG_ 1235 D_RS_DASM "D_RS_DASM";
BA_ "FlexKomComment" SG_ 1235 D_RS_DASM "Diagnostic-Response";
BA_ "FlexKomIsMotorola" SG_ 1235 D_RS_DASM 1;
BA_ "GenSigSNA" SG_ 1235 D_RS_DASM "0h";
BA_ "FlexKomSigStartValue" SG_ 1236 D_RS_ITBM "0000000000000000h";
BA_ "FlexKomSID" SG_ 1236 D_RS_ITBM 1481;
BA_ "FlexKomSigStartPos" SG_ 1236 D_RS_ITBM 7;
BA_ "FlexKomSigLaenge" SG_ 1236 D_RS_ITBM 64;
BA_ "FlexKomSigName" SG_ 1236 D_RS_ITBM "D_RS_ITBM";
BA_ "FlexKomComment" SG_ 1236 D_RS_ITBM "Diagnostic-Response";
BA_ "FlexKomIsMotorola" SG_ 1236 D_RS_ITBM 1;
BA_ "GenSigSNA" SG_ 1236 D_RS_ITBM "0h";
BA_ "FlexKomSigStartValue" SG_ 1239 D_RS_ADCM "0000000000000000h";
BA_ "FlexKomSID" SG_ 1239 D_RS_ADCM 124;
BA_ "FlexKomSigStartPos" SG_ 1239 D_RS_ADCM 7;
BA_ "FlexKomSigLaenge" SG_ 1239 D_RS_ADCM 64;
BA_ "FlexKomSigName" SG_ 1239 D_RS_ADCM "D_RS_ADCM";
BA_ "FlexKomComment" SG_ 1239 D_RS_ADCM "Diagnostic-Response";
BA_ "FlexKomIsMotorola" SG_ 1239 D_RS_ADCM 1;
BA_ "GenSigSNA" SG_ 1239 D_RS_ADCM "0h";
BA_ "FlexKomSigStartValue" SG_ 1241 D_RS_EPB "0000000000000000h";
BA_ "FlexKomSID" SG_ 1241 D_RS_EPB 1474;
BA_ "FlexKomSigStartPos" SG_ 1241 D_RS_EPB 7;
BA_ "FlexKomSigLaenge" SG_ 1241 D_RS_EPB 64;
BA_ "FlexKomSigName" SG_ 1241 D_RS_EPB "D_RS_EPB";
BA_ "FlexKomComment" SG_ 1241 D_RS_EPB "Diagnostic-Response";
BA_ "FlexKomIsMotorola" SG_ 1241 D_RS_EPB 1;
BA_ "GenSigSNA" SG_ 1241 D_RS_EPB "0h";
BA_ "FlexKomSigStartValue" SG_ 1242 D_RS_EPS "0000000000000000h";
BA_ "FlexKomSID" SG_ 1242 D_RS_EPS 141;
BA_ "FlexKomSigStartPos" SG_ 1242 D_RS_EPS 7;
BA_ "FlexKomSigLaenge" SG_ 1242 D_RS_EPS 64;
BA_ "FlexKomSigName" SG_ 1242 D_RS_EPS "D_RS_EPS";
BA_ "FlexKomComment" SG_ 1242 D_RS_EPS "Diagnostic-Response";
BA_ "FlexKomIsMotorola" SG_ 1242 D_RS_EPS 1;
BA_ "GenSigSNA" SG_ 1242 D_RS_EPS "0h";
BA_ "FlexKomSigStartValue" SG_ 1246 D_RS_OCM "0000000000000000h";
BA_ "FlexKomSID" SG_ 1246 D_RS_OCM 1537;
BA_ "FlexKomSigStartPos" SG_ 1246 D_RS_OCM 7;
BA_ "FlexKomSigLaenge" SG_ 1246 D_RS_OCM 64;
BA_ "FlexKomSigName" SG_ 1246 D_RS_OCM "D_RS_OCM";
BA_ "FlexKomComment" SG_ 1246 D_RS_OCM "Diagnostic-Response";
BA_ "FlexKomIsMotorola" SG_ 1246 D_RS_OCM 1;
BA_ "GenSigSNA" SG_ 1246 D_RS_OCM "0h";
BA_ "FlexKomSigStartValue" SG_ 1247 D_RS_EPPM "0000000000000000h";
BA_ "FlexKomSID" SG_ 1247 D_RS_EPPM 1334;
BA_ "FlexKomSigStartPos" SG_ 1247 D_RS_EPPM 7;
BA_ "FlexKomSigLaenge" SG_ 1247 D_RS_EPPM 64;
BA_ "FlexKomSigName" SG_ 1247 D_RS_EPPM "D_RS_EPPM";
BA_ "FlexKomComment" SG_ 1247 D_RS_EPPM "Diagnostic-Response";
BA_ "FlexKomIsMotorola" SG_ 1247 D_RS_EPPM 1;
BA_ "GenSigSNA" SG_ 1247 D_RS_EPPM "0h";
BA_ "FlexKomSigStartValue" SG_ 1250 D_RS_PTS "0000000000000000h";
BA_ "FlexKomSID" SG_ 1250 D_RS_PTS 161;
BA_ "FlexKomSigStartPos" SG_ 1250 D_RS_PTS 7;
BA_ "FlexKomSigLaenge" SG_ 1250 D_RS_PTS 64;
BA_ "FlexKomSigName" SG_ 1250 D_RS_PTS "D_RS_PTS";
BA_ "FlexKomComment" SG_ 1250 D_RS_PTS "Diagnostic-Response";
BA_ "FlexKomIsMotorola" SG_ 1250 D_RS_PTS 1;
BA_ "GenSigSNA" SG_ 1250 D_RS_PTS "0h";
BA_ "FlexKomSigStartValue" SG_ 1251 D_RS_SCCM "0000000000000000h";
BA_ "FlexKomSID" SG_ 1251 D_RS_SCCM 165;
BA_ "FlexKomSigStartPos" SG_ 1251 D_RS_SCCM 7;
BA_ "FlexKomSigLaenge" SG_ 1251 D_RS_SCCM 64;
BA_ "FlexKomSigName" SG_ 1251 D_RS_SCCM "D_RS_SCCM";
BA_ "FlexKomComment" SG_ 1251 D_RS_SCCM "Diagnostic-Response";
BA_ "FlexKomIsMotorola" SG_ 1251 D_RS_SCCM 1;
BA_ "GenSigSNA" SG_ 1251 D_RS_SCCM "0h";
BA_ "FlexKomSigStartValue" SG_ 1252 D_RS_HaLF "0000000000000000h";
BA_ "FlexKomSID" SG_ 1252 D_RS_HaLF 1633;
BA_ "FlexKomSigStartPos" SG_ 1252 D_RS_HaLF 7;
BA_ "FlexKomSigLaenge" SG_ 1252 D_RS_HaLF 64;
BA_ "FlexKomSigName" SG_ 1252 D_RS_HaLF "D_RS_HaLF";
BA_ "FlexKomComment" SG_ 1252 D_RS_HaLF "Diagnostic-Response";
BA_ "FlexKomIsMotorola" SG_ 1252 D_RS_HaLF 1;
BA_ "GenSigSNA" SG_ 1252 D_RS_HaLF "0h";
BA_ "FlexKomSigStartValue" SG_ 1253 D_RS_ANC "0000000000000000h";
BA_ "FlexKomSID" SG_ 1253 D_RS_ANC 129;
BA_ "FlexKomSigStartPos" SG_ 1253 D_RS_ANC 7;
BA_ "FlexKomSigLaenge" SG_ 1253 D_RS_ANC 64;
BA_ "FlexKomSigName" SG_ 1253 D_RS_ANC "D_RS_ANC";
BA_ "FlexKomComment" SG_ 1253 D_RS_ANC "Diagnostic-Response";
BA_ "FlexKomIsMotorola" SG_ 1253 D_RS_ANC 1;
BA_ "GenSigSNA" SG_ 1253 D_RS_ANC "0h";
BA_ "FlexKomSigStartValue" SG_ 1254 D_RS_ASCM "0000000000000000h";
BA_ "FlexKomSID" SG_ 1254 D_RS_ASCM 130;
BA_ "FlexKomSigStartPos" SG_ 1254 D_RS_ASCM 7;
BA_ "FlexKomSigLaenge" SG_ 1254 D_RS_ASCM 64;
BA_ "FlexKomSigName" SG_ 1254 D_RS_ASCM "D_RS_ASCM";
BA_ "FlexKomComment" SG_ 1254 D_RS_ASCM "Diagnostic-Response";
BA_ "FlexKomIsMotorola" SG_ 1254 D_RS_ASCM 1;
BA_ "GenSigSNA" SG_ 1254 D_RS_ASCM "0h";
BA_ "FlexKomSigStartValue" SG_ 1256 D_RS_AFLS "0000000000000000h";
BA_ "FlexKomSID" SG_ 1256 D_RS_AFLS 125;
BA_ "FlexKomSigStartPos" SG_ 1256 D_RS_AFLS 7;
BA_ "FlexKomSigLaenge" SG_ 1256 D_RS_AFLS 64;
BA_ "FlexKomSigName" SG_ 1256 D_RS_AFLS "D_RS_AFLS";
BA_ "FlexKomComment" SG_ 1256 D_RS_AFLS "Diagnostic-Response";
BA_ "FlexKomIsMotorola" SG_ 1256 D_RS_AFLS 1;
BA_ "GenSigSNA" SG_ 1256 D_RS_AFLS "0h";
BA_ "FlexKomSigStartValue" SG_ 1257 D_RS_AHLM "0000000000000000h";
BA_ "FlexKomSID" SG_ 1257 D_RS_AHLM 127;
BA_ "FlexKomSigStartPos" SG_ 1257 D_RS_AHLM 7;
BA_ "FlexKomSigLaenge" SG_ 1257 D_RS_AHLM 64;
BA_ "FlexKomSigName" SG_ 1257 D_RS_AHLM "D_RS_AHLM";
BA_ "FlexKomComment" SG_ 1257 D_RS_AHLM "Diagnostic-Response";
BA_ "FlexKomIsMotorola" SG_ 1257 D_RS_AHLM 1;
BA_ "GenSigSNA" SG_ 1257 D_RS_AHLM "0h";
BA_ "FlexKomSigStartValue" SG_ 1264 D_RS_ELSD "0000000000000000h";
BA_ "FlexKomSID" SG_ 1264 D_RS_ELSD 1594;
BA_ "FlexKomSigStartPos" SG_ 1264 D_RS_ELSD 7;
BA_ "FlexKomSigLaenge" SG_ 1264 D_RS_ELSD 64;
BA_ "FlexKomSigName" SG_ 1264 D_RS_ELSD "D_RS_ELSD";
BA_ "FlexKomComment" SG_ 1264 D_RS_ELSD "Diagnostic-Response";
BA_ "FlexKomIsMotorola" SG_ 1264 D_RS_ELSD 1;
BA_ "GenSigSNA" SG_ 1264 D_RS_ELSD "0h";
BA_ "FlexKomSigStartValue" SG_ 1265 D_RS_VSIM "0000000000000000h";
BA_ "FlexKomSID" SG_ 1265 D_RS_VSIM 174;
BA_ "FlexKomSigStartPos" SG_ 1265 D_RS_VSIM 7;
BA_ "FlexKomSigLaenge" SG_ 1265 D_RS_VSIM 64;
BA_ "FlexKomSigName" SG_ 1265 D_RS_VSIM "D_RS_VSIM";
BA_ "FlexKomComment" SG_ 1265 D_RS_VSIM "Diagnostic-Response";
BA_ "FlexKomIsMotorola" SG_ 1265 D_RS_VSIM 1;
BA_ "GenSigSNA" SG_ 1265 D_RS_VSIM "0h";
BA_ "FlexKomSigStartValue" SG_ 1271 D_RS_VGT "0000000000000000h";
BA_ "FlexKomSID" SG_ 1271 D_RS_VGT 1816;
BA_ "FlexKomSigStartPos" SG_ 1271 D_RS_VGT 7;
BA_ "FlexKomSigLaenge" SG_ 1271 D_RS_VGT 64;
BA_ "FlexKomSigName" SG_ 1271 D_RS_VGT "D_RS_VGT";
BA_ "FlexKomComment" SG_ 1271 D_RS_VGT "Diagnostic-Response";
BA_ "FlexKomIsMotorola" SG_ 1271 D_RS_VGT 1;
BA_ "GenSigSNA" SG_ 1271 D_RS_VGT "0h";
BA_ "FlexKomSigStartValue" SG_ 1284 D_RS_CBC "0000000000000000h";
BA_ "FlexKomSID" SG_ 1284 D_RS_CBC 132;
BA_ "FlexKomSigStartPos" SG_ 1284 D_RS_CBC 7;
BA_ "FlexKomSigLaenge" SG_ 1284 D_RS_CBC 64;
BA_ "FlexKomSigName" SG_ 1284 D_RS_CBC "D_RS_CBC";
BA_ "FlexKomComment" SG_ 1284 D_RS_CBC "Diagnostic-Response";
BA_ "FlexKomIsMotorola" SG_ 1284 D_RS_CBC 1;
BA_ "GenSigSNA" SG_ 1284 D_RS_CBC "0h";
BA_ "GenSigSendType" SG_ 1408 ECU_APPL_RF_HUB 1;
BA_ "FlexKomSigStartValue" SG_ 1408 ECU_APPL_RF_HUB "0000000000000000h";
BA_ "FlexKomSID" SG_ 1408 ECU_APPL_RF_HUB 358;
BA_ "FlexKomSigStartPos" SG_ 1408 ECU_APPL_RF_HUB 7;
BA_ "FlexKomSigLaenge" SG_ 1408 ECU_APPL_RF_HUB 64;
BA_ "FlexKomSigName" SG_ 1408 ECU_APPL_RF_HUB "ECU_APPL_RF_HUB";
BA_ "FlexKomComment" SG_ 1408 ECU_APPL_RF_HUB "ECU to External Application";
BA_ "FlexKomIsMotorola" SG_ 1408 ECU_APPL_RF_HUB 1;
BA_ "GenSigSNA" SG_ 1408 ECU_APPL_RF_HUB "0h";
BA_ "GenSigSendType" SG_ 1409 ECU_APPL_CBC 1;
BA_ "FlexKomSigStartValue" SG_ 1409 ECU_APPL_CBC "0000000000000000h";
BA_ "FlexKomSID" SG_ 1409 ECU_APPL_CBC 344;
BA_ "FlexKomSigStartPos" SG_ 1409 ECU_APPL_CBC 7;
BA_ "FlexKomSigLaenge" SG_ 1409 ECU_APPL_CBC 64;
BA_ "FlexKomSigName" SG_ 1409 ECU_APPL_CBC "ECU_APPL_CBC";
BA_ "FlexKomComment" SG_ 1409 ECU_APPL_CBC "ECU to External Application";
BA_ "FlexKomIsMotorola" SG_ 1409 ECU_APPL_CBC 1;
BA_ "GenSigSNA" SG_ 1409 ECU_APPL_CBC "0h";
BA_ "GenSigSendType" SG_ 1410 ECU_APPL_IC 1;
BA_ "FlexKomSigStartValue" SG_ 1410 ECU_APPL_IC "0000000000000000h";
BA_ "FlexKomSID" SG_ 1410 ECU_APPL_IC 361;
BA_ "FlexKomSigStartPos" SG_ 1410 ECU_APPL_IC 7;
BA_ "FlexKomSigLaenge" SG_ 1410 ECU_APPL_IC 64;
BA_ "FlexKomSigName" SG_ 1410 ECU_APPL_IC "ECU_APPL_IC";
BA_ "FlexKomComment" SG_ 1410 ECU_APPL_IC "ECU to External Application";
BA_ "FlexKomIsMotorola" SG_ 1410 ECU_APPL_IC 1;
BA_ "GenSigSNA" SG_ 1410 ECU_APPL_IC "0h";
BA_ "GenSigSendType" SG_ 1411 ECU_APPL_TPM 1;
BA_ "FlexKomSigStartValue" SG_ 1411 ECU_APPL_TPM "0000000000000000h";
BA_ "FlexKomSID" SG_ 1411 ECU_APPL_TPM 387;
BA_ "FlexKomSigStartPos" SG_ 1411 ECU_APPL_TPM 7;
BA_ "FlexKomSigLaenge" SG_ 1411 ECU_APPL_TPM 64;
BA_ "FlexKomSigName" SG_ 1411 ECU_APPL_TPM "ECU_APPL_TPM";
BA_ "FlexKomComment" SG_ 1411 ECU_APPL_TPM "ECU to External Application";
BA_ "FlexKomIsMotorola" SG_ 1411 ECU_APPL_TPM 1;
BA_ "GenSigSNA" SG_ 1411 ECU_APPL_TPM "0h";
BA_ "GenSigSendType" SG_ 1412 ECU_APPL_ORC 1;
BA_ "FlexKomSigStartValue" SG_ 1412 ECU_APPL_ORC "0000000000000000h";
BA_ "FlexKomSID" SG_ 1412 ECU_APPL_ORC 368;
BA_ "FlexKomSigStartPos" SG_ 1412 ECU_APPL_ORC 7;
BA_ "FlexKomSigLaenge" SG_ 1412 ECU_APPL_ORC 64;
BA_ "FlexKomSigName" SG_ 1412 ECU_APPL_ORC "ECU_APPL_ORC";
BA_ "FlexKomComment" SG_ 1412 ECU_APPL_ORC "ECU to External Application";
BA_ "FlexKomIsMotorola" SG_ 1412 ECU_APPL_ORC 1;
BA_ "GenSigSNA" SG_ 1412 ECU_APPL_ORC "0h";
BA_ "GenSigSendType" SG_ 1413 ECU_APPL_RBT_DR 1;
BA_ "FlexKomSigStartValue" SG_ 1413 ECU_APPL_RBT_DR "0000000000000000h";
BA_ "FlexKomSID" SG_ 1413 ECU_APPL_RBT_DR 391;
BA_ "FlexKomSigStartPos" SG_ 1413 ECU_APPL_RBT_DR 7;
BA_ "FlexKomSigLaenge" SG_ 1413 ECU_APPL_RBT_DR 64;
BA_ "FlexKomSigName" SG_ 1413 ECU_APPL_RBT_DR "ECU_APPL_RBT_DR";
BA_ "FlexKomComment" SG_ 1413 ECU_APPL_RBT_DR "ECU to External Application";
BA_ "FlexKomIsMotorola" SG_ 1413 ECU_APPL_RBT_DR 1;
BA_ "GenSigSNA" SG_ 1413 ECU_APPL_RBT_DR "0h";
BA_ "GenSigSendType" SG_ 1414 ECU_APPL_RBT_PASS 1;
BA_ "FlexKomSigStartValue" SG_ 1414 ECU_APPL_RBT_PASS "0000000000000000h";
BA_ "FlexKomSID" SG_ 1414 ECU_APPL_RBT_PASS 379;
BA_ "FlexKomSigStartPos" SG_ 1414 ECU_APPL_RBT_PASS 7;
BA_ "FlexKomSigLaenge" SG_ 1414 ECU_APPL_RBT_PASS 64;
BA_ "FlexKomSigName" SG_ 1414 ECU_APPL_RBT_PASS "ECU_APPL_RBT_PASS";
BA_ "FlexKomComment" SG_ 1414 ECU_APPL_RBT_PASS "ECU to External Application";
BA_ "FlexKomIsMotorola" SG_ 1414 ECU_APPL_RBT_PASS 1;
BA_ "GenSigSNA" SG_ 1414 ECU_APPL_RBT_PASS "0h";
BA_ "GenSigSendType" SG_ 1415 ECU_APPL_ESC 1;
BA_ "FlexKomSigStartValue" SG_ 1415 ECU_APPL_ESC "0000000000000000h";
BA_ "FlexKomSID" SG_ 1415 ECU_APPL_ESC 356;
BA_ "FlexKomSigStartPos" SG_ 1415 ECU_APPL_ESC 7;
BA_ "FlexKomSigLaenge" SG_ 1415 ECU_APPL_ESC 64;
BA_ "FlexKomSigName" SG_ 1415 ECU_APPL_ESC "ECU_APPL_ESC";
BA_ "FlexKomComment" SG_ 1415 ECU_APPL_ESC "ECU to External Application";
BA_ "FlexKomIsMotorola" SG_ 1415 ECU_APPL_ESC 1;
BA_ "GenSigSNA" SG_ 1415 ECU_APPL_ESC "0h";
BA_ "GenSigSendType" SG_ 1417 ECU_APPL_ESM 1;
BA_ "FlexKomSigStartValue" SG_ 1417 ECU_APPL_ESM "0000000000000000h";
BA_ "FlexKomSID" SG_ 1417 ECU_APPL_ESM 355;
BA_ "FlexKomSigStartPos" SG_ 1417 ECU_APPL_ESM 7;
BA_ "FlexKomSigLaenge" SG_ 1417 ECU_APPL_ESM 64;
BA_ "FlexKomSigName" SG_ 1417 ECU_APPL_ESM "ECU_APPL_ESM";
BA_ "FlexKomComment" SG_ 1417 ECU_APPL_ESM "ECU to External Application";
BA_ "FlexKomIsMotorola" SG_ 1417 ECU_APPL_ESM 1;
BA_ "GenSigSNA" SG_ 1417 ECU_APPL_ESM "0h";
BA_ "GenSigSendType" SG_ 1419 ECU_APPL_DTCM 1;
BA_ "FlexKomSigStartValue" SG_ 1419 ECU_APPL_DTCM "0000000000000000h";
BA_ "FlexKomSID" SG_ 1419 ECU_APPL_DTCM 351;
BA_ "FlexKomSigStartPos" SG_ 1419 ECU_APPL_DTCM 7;
BA_ "FlexKomSigLaenge" SG_ 1419 ECU_APPL_DTCM 64;
BA_ "FlexKomSigName" SG_ 1419 ECU_APPL_DTCM "ECU_APPL_DTCM";
BA_ "FlexKomComment" SG_ 1419 ECU_APPL_DTCM "ECU to External Application";
BA_ "FlexKomIsMotorola" SG_ 1419 ECU_APPL_DTCM 1;
BA_ "GenSigSNA" SG_ 1419 ECU_APPL_DTCM "0h";
BA_ "GenSigSendType" SG_ 1420 ECU_APPL_FDCM 1;
BA_ "FlexKomSigStartValue" SG_ 1420 ECU_APPL_FDCM "0000000000000000h";
BA_ "FlexKomSID" SG_ 1420 ECU_APPL_FDCM 1602;
BA_ "FlexKomSigStartPos" SG_ 1420 ECU_APPL_FDCM 7;
BA_ "FlexKomSigLaenge" SG_ 1420 ECU_APPL_FDCM 64;
BA_ "FlexKomSigName" SG_ 1420 ECU_APPL_FDCM "ECU_APPL_FDCM";
BA_ "FlexKomComment" SG_ 1420 ECU_APPL_FDCM "ECU to External Application";
BA_ "FlexKomIsMotorola" SG_ 1420 ECU_APPL_FDCM 1;
BA_ "GenSigSNA" SG_ 1420 ECU_APPL_FDCM "0h";
BA_ "GenSigSendType" SG_ 1427 ECU_APPL_DASM 1;
BA_ "FlexKomSigStartValue" SG_ 1427 ECU_APPL_DASM "0000000000000000h";
BA_ "FlexKomSID" SG_ 1427 ECU_APPL_DASM 364;
BA_ "FlexKomSigStartPos" SG_ 1427 ECU_APPL_DASM 7;
BA_ "FlexKomSigLaenge" SG_ 1427 ECU_APPL_DASM 64;
BA_ "FlexKomSigName" SG_ 1427 ECU_APPL_DASM "ECU_APPL_DASM";
BA_ "FlexKomComment" SG_ 1427 ECU_APPL_DASM "ECU to External Application";
BA_ "FlexKomIsMotorola" SG_ 1427 ECU_APPL_DASM 1;
BA_ "GenSigSNA" SG_ 1427 ECU_APPL_DASM "0h";
BA_ "GenSigSendType" SG_ 1428 ECU_APPL_ITBM 1;
BA_ "FlexKomSigStartValue" SG_ 1428 ECU_APPL_ITBM "0000000000000000h";
BA_ "FlexKomSID" SG_ 1428 ECU_APPL_ITBM 1484;
BA_ "FlexKomSigStartPos" SG_ 1428 ECU_APPL_ITBM 7;
BA_ "FlexKomSigLaenge" SG_ 1428 ECU_APPL_ITBM 64;
BA_ "FlexKomSigName" SG_ 1428 ECU_APPL_ITBM "ECU_APPL_ITBM";
BA_ "FlexKomComment" SG_ 1428 ECU_APPL_ITBM "ECU to External Application";
BA_ "FlexKomIsMotorola" SG_ 1428 ECU_APPL_ITBM 1;
BA_ "GenSigSNA" SG_ 1428 ECU_APPL_ITBM "0h";
BA_ "GenSigSendType" SG_ 1431 ECU_APPL_ADCM 1;
BA_ "FlexKomSigStartValue" SG_ 1431 ECU_APPL_ADCM "0000000000000000h";
BA_ "FlexKomSID" SG_ 1431 ECU_APPL_ADCM 336;
BA_ "FlexKomSigStartPos" SG_ 1431 ECU_APPL_ADCM 7;
BA_ "FlexKomSigLaenge" SG_ 1431 ECU_APPL_ADCM 64;
BA_ "FlexKomSigName" SG_ 1431 ECU_APPL_ADCM "ECU_APPL_ADCM";
BA_ "FlexKomComment" SG_ 1431 ECU_APPL_ADCM "ECU to External Application";
BA_ "FlexKomIsMotorola" SG_ 1431 ECU_APPL_ADCM 1;
BA_ "GenSigSNA" SG_ 1431 ECU_APPL_ADCM "0h";
BA_ "GenSigSendType" SG_ 1433 ECU_APPL_EPB 1;
BA_ "FlexKomSigStartValue" SG_ 1433 ECU_APPL_EPB "0000000000000000h";
BA_ "FlexKomSID" SG_ 1433 ECU_APPL_EPB 1477;
BA_ "FlexKomSigStartPos" SG_ 1433 ECU_APPL_EPB 7;
BA_ "FlexKomSigLaenge" SG_ 1433 ECU_APPL_EPB 64;
BA_ "FlexKomSigName" SG_ 1433 ECU_APPL_EPB "ECU_APPL_EPB";
BA_ "FlexKomComment" SG_ 1433 ECU_APPL_EPB "ECU to External Application";
BA_ "FlexKomIsMotorola" SG_ 1433 ECU_APPL_EPB 1;
BA_ "GenSigSNA" SG_ 1433 ECU_APPL_EPB "0h";
BA_ "GenSigSendType" SG_ 1434 ECU_APPL_EPS 1;
BA_ "FlexKomSigStartValue" SG_ 1434 ECU_APPL_EPS "0000000000000000h";
BA_ "FlexKomSID" SG_ 1434 ECU_APPL_EPS 354;
BA_ "FlexKomSigStartPos" SG_ 1434 ECU_APPL_EPS 7;
BA_ "FlexKomSigLaenge" SG_ 1434 ECU_APPL_EPS 64;
BA_ "FlexKomSigName" SG_ 1434 ECU_APPL_EPS "ECU_APPL_EPS";
BA_ "FlexKomComment" SG_ 1434 ECU_APPL_EPS "ECU to External Application";
BA_ "FlexKomIsMotorola" SG_ 1434 ECU_APPL_EPS 1;
BA_ "GenSigSNA" SG_ 1434 ECU_APPL_EPS "0h";
BA_ "GenSigSendType" SG_ 1438 ECU_APPL_OCM 1;
BA_ "FlexKomSigStartValue" SG_ 1438 ECU_APPL_OCM "0000000000000000h";
BA_ "FlexKomSID" SG_ 1438 ECU_APPL_OCM 1540;
BA_ "FlexKomSigStartPos" SG_ 1438 ECU_APPL_OCM 7;
BA_ "FlexKomSigLaenge" SG_ 1438 ECU_APPL_OCM 64;
BA_ "FlexKomSigName" SG_ 1438 ECU_APPL_OCM "ECU_APPL_OCM";
BA_ "FlexKomComment" SG_ 1438 ECU_APPL_OCM "ECU to External Application";
BA_ "FlexKomIsMotorola" SG_ 1438 ECU_APPL_OCM 1;
BA_ "GenSigSNA" SG_ 1438 ECU_APPL_OCM "0h";
BA_ "GenSigSendType" SG_ 1439 ECU_APPL_EPPM 1;
BA_ "FlexKomSigStartValue" SG_ 1439 ECU_APPL_EPPM "0000000000000000h";
BA_ "FlexKomSID" SG_ 1439 ECU_APPL_EPPM 1336;
BA_ "FlexKomSigStartPos" SG_ 1439 ECU_APPL_EPPM 7;
BA_ "FlexKomSigLaenge" SG_ 1439 ECU_APPL_EPPM 64;
BA_ "FlexKomSigName" SG_ 1439 ECU_APPL_EPPM "ECU_APPL_EPPM";
BA_ "FlexKomComment" SG_ 1439 ECU_APPL_EPPM "ECU to External Application";
BA_ "FlexKomIsMotorola" SG_ 1439 ECU_APPL_EPPM 1;
BA_ "GenSigSNA" SG_ 1439 ECU_APPL_EPPM "0h";
BA_ "GenSigSendType" SG_ 1442 ECU_APPL_PTS 1;
BA_ "FlexKomSigStartValue" SG_ 1442 ECU_APPL_PTS "0000000000000000h";
BA_ "FlexKomSID" SG_ 1442 ECU_APPL_PTS 376;
BA_ "FlexKomSigStartPos" SG_ 1442 ECU_APPL_PTS 7;
BA_ "FlexKomSigLaenge" SG_ 1442 ECU_APPL_PTS 64;
BA_ "FlexKomSigName" SG_ 1442 ECU_APPL_PTS "ECU_APPL_PTS";
BA_ "FlexKomComment" SG_ 1442 ECU_APPL_PTS "ECU to External Application";
BA_ "FlexKomIsMotorola" SG_ 1442 ECU_APPL_PTS 1;
BA_ "GenSigSNA" SG_ 1442 ECU_APPL_PTS "0h";
BA_ "GenSigSendType" SG_ 1443 ECU_APPL_SCCM 1;
BA_ "FlexKomSigStartValue" SG_ 1443 ECU_APPL_SCCM "0000000000000000h";
BA_ "FlexKomSID" SG_ 1443 ECU_APPL_SCCM 380;
BA_ "FlexKomSigStartPos" SG_ 1443 ECU_APPL_SCCM 7;
BA_ "FlexKomSigLaenge" SG_ 1443 ECU_APPL_SCCM 64;
BA_ "FlexKomSigName" SG_ 1443 ECU_APPL_SCCM "ECU_APPL_SCCM";
BA_ "FlexKomComment" SG_ 1443 ECU_APPL_SCCM "ECU to External Application";
BA_ "FlexKomIsMotorola" SG_ 1443 ECU_APPL_SCCM 1;
BA_ "GenSigSNA" SG_ 1443 ECU_APPL_SCCM "0h";
BA_ "GenSigSendType" SG_ 1444 ECU_APPL_HaLF 1;
BA_ "FlexKomSigStartValue" SG_ 1444 ECU_APPL_HaLF "0000000000000000h";
BA_ "FlexKomSID" SG_ 1444 ECU_APPL_HaLF 1634;
BA_ "FlexKomSigStartPos" SG_ 1444 ECU_APPL_HaLF 7;
BA_ "FlexKomSigLaenge" SG_ 1444 ECU_APPL_HaLF 64;
BA_ "FlexKomSigName" SG_ 1444 ECU_APPL_HaLF "ECU_APPL_HaLF";
BA_ "FlexKomComment" SG_ 1444 ECU_APPL_HaLF "ECU to External Application";
BA_ "FlexKomIsMotorola" SG_ 1444 ECU_APPL_HaLF 1;
BA_ "GenSigSNA" SG_ 1444 ECU_APPL_HaLF "0h";
BA_ "GenSigSendType" SG_ 1445 ECU_APPL_ANC 1;
BA_ "FlexKomSigStartValue" SG_ 1445 ECU_APPL_ANC "0000000000000000h";
BA_ "FlexKomSID" SG_ 1445 ECU_APPL_ANC 341;
BA_ "FlexKomSigStartPos" SG_ 1445 ECU_APPL_ANC 7;
BA_ "FlexKomSigLaenge" SG_ 1445 ECU_APPL_ANC 64;
BA_ "FlexKomSigName" SG_ 1445 ECU_APPL_ANC "ECU_APPL_ANC";
BA_ "FlexKomComment" SG_ 1445 ECU_APPL_ANC "ECU to External Application";
BA_ "FlexKomIsMotorola" SG_ 1445 ECU_APPL_ANC 1;
BA_ "GenSigSNA" SG_ 1445 ECU_APPL_ANC "0h";
BA_ "GenSigSendType" SG_ 1446 ECU_APPL_ASCM 1;
BA_ "FlexKomSigStartValue" SG_ 1446 ECU_APPL_ASCM "0000000000000000h";
BA_ "FlexKomSID" SG_ 1446 ECU_APPL_ASCM 342;
BA_ "FlexKomSigStartPos" SG_ 1446 ECU_APPL_ASCM 7;
BA_ "FlexKomSigLaenge" SG_ 1446 ECU_APPL_ASCM 64;
BA_ "FlexKomSigName" SG_ 1446 ECU_APPL_ASCM "ECU_APPL_ASCM";
BA_ "FlexKomComment" SG_ 1446 ECU_APPL_ASCM "ECU to External Application";
BA_ "FlexKomIsMotorola" SG_ 1446 ECU_APPL_ASCM 1;
BA_ "GenSigSNA" SG_ 1446 ECU_APPL_ASCM "0h";
BA_ "GenSigSendType" SG_ 1448 ECU_APPL_AFLS 1;
BA_ "FlexKomSigStartValue" SG_ 1448 ECU_APPL_AFLS "0000000000000000h";
BA_ "FlexKomSID" SG_ 1448 ECU_APPL_AFLS 337;
BA_ "FlexKomSigStartPos" SG_ 1448 ECU_APPL_AFLS 7;
BA_ "FlexKomSigLaenge" SG_ 1448 ECU_APPL_AFLS 64;
BA_ "FlexKomSigName" SG_ 1448 ECU_APPL_AFLS "ECU_APPL_AFLS";
BA_ "FlexKomComment" SG_ 1448 ECU_APPL_AFLS "ECU to External Application";
BA_ "FlexKomIsMotorola" SG_ 1448 ECU_APPL_AFLS 1;
BA_ "GenSigSNA" SG_ 1448 ECU_APPL_AFLS "0h";
BA_ "GenSigSendType" SG_ 1449 ECU_APPL_AHLM 1;
BA_ "FlexKomSigStartValue" SG_ 1449 ECU_APPL_AHLM "0000000000000000h";
BA_ "FlexKomSID" SG_ 1449 ECU_APPL_AHLM 339;
BA_ "FlexKomSigStartPos" SG_ 1449 ECU_APPL_AHLM 7;
BA_ "FlexKomSigLaenge" SG_ 1449 ECU_APPL_AHLM 64;
BA_ "FlexKomSigName" SG_ 1449 ECU_APPL_AHLM "ECU_APPL_AHLM";
BA_ "FlexKomComment" SG_ 1449 ECU_APPL_AHLM "ECU to External Application";
BA_ "FlexKomIsMotorola" SG_ 1449 ECU_APPL_AHLM 1;
BA_ "GenSigSNA" SG_ 1449 ECU_APPL_AHLM "0h";
BA_ "GenSigSendType" SG_ 1456 ECU_APPL_ELSD 1;
BA_ "FlexKomSigStartValue" SG_ 1456 ECU_APPL_ELSD "0000000000000000h";
BA_ "FlexKomSID" SG_ 1456 ECU_APPL_ELSD 1596;
BA_ "FlexKomSigStartPos" SG_ 1456 ECU_APPL_ELSD 7;
BA_ "FlexKomSigLaenge" SG_ 1456 ECU_APPL_ELSD 64;
BA_ "FlexKomSigName" SG_ 1456 ECU_APPL_ELSD "ECU_APPL_ELSD";
BA_ "FlexKomComment" SG_ 1456 ECU_APPL_ELSD "ECU to External Application";
BA_ "FlexKomIsMotorola" SG_ 1456 ECU_APPL_ELSD 1;
BA_ "GenSigSNA" SG_ 1456 ECU_APPL_ELSD "0h";
BA_ "GenSigSendType" SG_ 1457 ECU_APPL_VSIM 1;
BA_ "FlexKomSigStartValue" SG_ 1457 ECU_APPL_VSIM "0000000000000000h";
BA_ "FlexKomSID" SG_ 1457 ECU_APPL_VSIM 389;
BA_ "FlexKomSigStartPos" SG_ 1457 ECU_APPL_VSIM 7;
BA_ "FlexKomSigLaenge" SG_ 1457 ECU_APPL_VSIM 64;
BA_ "FlexKomSigName" SG_ 1457 ECU_APPL_VSIM "ECU_APPL_VSIM";
BA_ "FlexKomComment" SG_ 1457 ECU_APPL_VSIM "ECU to External Application";
BA_ "FlexKomIsMotorola" SG_ 1457 ECU_APPL_VSIM 1;
BA_ "GenSigSNA" SG_ 1457 ECU_APPL_VSIM "0h";
BA_ "GenSigSendType" SG_ 1464 ECU_APPL_ECM 1;
BA_ "FlexKomSigStartValue" SG_ 1464 ECU_APPL_ECM "0000000000000000h";
BA_ "FlexKomSID" SG_ 1464 ECU_APPL_ECM 352;
BA_ "FlexKomSigStartPos" SG_ 1464 ECU_APPL_ECM 7;
BA_ "FlexKomSigLaenge" SG_ 1464 ECU_APPL_ECM 64;
BA_ "FlexKomSigName" SG_ 1464 ECU_APPL_ECM "ECU_APPL_ECM";
BA_ "FlexKomComment" SG_ 1464 ECU_APPL_ECM "ECU to External Application";
BA_ "FlexKomIsMotorola" SG_ 1464 ECU_APPL_ECM 1;
BA_ "GenSigSNA" SG_ 1464 ECU_APPL_ECM "0h";
BA_ "GenSigSendType" SG_ 1465 ECU_APPL_TCM 1;
BA_ "FlexKomSigStartValue" SG_ 1465 ECU_APPL_TCM "0000000000000000h";
BA_ "FlexKomSID" SG_ 1465 ECU_APPL_TCM 384;
BA_ "FlexKomSigStartPos" SG_ 1465 ECU_APPL_TCM 7;
BA_ "FlexKomSigLaenge" SG_ 1465 ECU_APPL_TCM 64;
BA_ "FlexKomSigName" SG_ 1465 ECU_APPL_TCM "ECU_APPL_TCM";
BA_ "FlexKomComment" SG_ 1465 ECU_APPL_TCM "ECU to External Application";
BA_ "FlexKomIsMotorola" SG_ 1465 ECU_APPL_TCM 1;
BA_ "GenSigSNA" SG_ 1465 ECU_APPL_TCM "0h";
BA_ "GenSigSendType" SG_ 1536 SD_RS_RF_HUB 1;
BA_ "FlexKomSigStartValue" SG_ 1536 SD_RS_RF_HUB "0000000000000000h";
BA_ "FlexKomSID" SG_ 1536 SD_RS_RF_HUB 198;
BA_ "FlexKomSigStartPos" SG_ 1536 SD_RS_RF_HUB 7;
BA_ "FlexKomSigLaenge" SG_ 1536 SD_RS_RF_HUB 64;
BA_ "FlexKomSigName" SG_ 1536 SD_RS_RF_HUB "SD_RS_RF_HUB";
BA_ "FlexKomComment" SG_ 1536 SD_RS_RF_HUB "Response on Event - light";
BA_ "FlexKomIsMotorola" SG_ 1536 SD_RS_RF_HUB 1;
BA_ "GenSigSNA" SG_ 1536 SD_RS_RF_HUB "0h";
BA_ "GenSigSendType" SG_ 1537 SD_RS_CBC 1;
BA_ "FlexKomSigStartValue" SG_ 1537 SD_RS_CBC "0000000000000000h";
BA_ "FlexKomSID" SG_ 1537 SD_RS_CBC 185;
BA_ "FlexKomSigStartPos" SG_ 1537 SD_RS_CBC 7;
BA_ "FlexKomSigLaenge" SG_ 1537 SD_RS_CBC 64;
BA_ "FlexKomSigName" SG_ 1537 SD_RS_CBC "SD_RS_CBC";
BA_ "FlexKomComment" SG_ 1537 SD_RS_CBC "Response on Event - light";
BA_ "FlexKomIsMotorola" SG_ 1537 SD_RS_CBC 1;
BA_ "GenSigSNA" SG_ 1537 SD_RS_CBC "0h";
BA_ "GenSigSendType" SG_ 1538 SD_RS_IC 1;
BA_ "FlexKomSigStartValue" SG_ 1538 SD_RS_IC "0000000000000000h";
BA_ "FlexKomSID" SG_ 1538 SD_RS_IC 201;
BA_ "FlexKomSigStartPos" SG_ 1538 SD_RS_IC 7;
BA_ "FlexKomSigLaenge" SG_ 1538 SD_RS_IC 64;
BA_ "FlexKomSigName" SG_ 1538 SD_RS_IC "SD_RS_IC";
BA_ "FlexKomComment" SG_ 1538 SD_RS_IC "Response on Event - light";
BA_ "FlexKomIsMotorola" SG_ 1538 SD_RS_IC 1;
BA_ "GenSigSNA" SG_ 1538 SD_RS_IC "0h";
BA_ "GenSigSendType" SG_ 1539 SD_RS_TPM 1;
BA_ "FlexKomSigStartValue" SG_ 1539 SD_RS_TPM "0000000000000000h";
BA_ "FlexKomSID" SG_ 1539 SD_RS_TPM 226;
BA_ "FlexKomSigStartPos" SG_ 1539 SD_RS_TPM 7;
BA_ "FlexKomSigLaenge" SG_ 1539 SD_RS_TPM 64;
BA_ "FlexKomSigName" SG_ 1539 SD_RS_TPM "SD_RS_TPM";
BA_ "FlexKomComment" SG_ 1539 SD_RS_TPM "Response on Event - light";
BA_ "FlexKomIsMotorola" SG_ 1539 SD_RS_TPM 1;
BA_ "GenSigSNA" SG_ 1539 SD_RS_TPM "0h";
BA_ "GenSigSendType" SG_ 1540 SD_RS_ORC 1;
BA_ "FlexKomSigStartValue" SG_ 1540 SD_RS_ORC "0000000000000000h";
BA_ "FlexKomSID" SG_ 1540 SD_RS_ORC 207;
BA_ "FlexKomSigStartPos" SG_ 1540 SD_RS_ORC 7;
BA_ "FlexKomSigLaenge" SG_ 1540 SD_RS_ORC 64;
BA_ "FlexKomSigName" SG_ 1540 SD_RS_ORC "SD_RS_ORC";
BA_ "FlexKomComment" SG_ 1540 SD_RS_ORC "Response on Event - light";
BA_ "FlexKomIsMotorola" SG_ 1540 SD_RS_ORC 1;
BA_ "GenSigSNA" SG_ 1540 SD_RS_ORC "0h";
BA_ "GenSigSendType" SG_ 1541 SD_RS_RBT_DR 1;
BA_ "FlexKomSigStartValue" SG_ 1541 SD_RS_RBT_DR "0000000000000000h";
BA_ "FlexKomSID" SG_ 1541 SD_RS_RBT_DR 217;
BA_ "FlexKomSigStartPos" SG_ 1541 SD_RS_RBT_DR 7;
BA_ "FlexKomSigLaenge" SG_ 1541 SD_RS_RBT_DR 64;
BA_ "FlexKomSigName" SG_ 1541 SD_RS_RBT_DR "SD_RS_RBT_DR";
BA_ "FlexKomComment" SG_ 1541 SD_RS_RBT_DR "Response on Event - light";
BA_ "FlexKomIsMotorola" SG_ 1541 SD_RS_RBT_DR 1;
BA_ "GenSigSNA" SG_ 1541 SD_RS_RBT_DR "0h";
BA_ "GenSigSendType" SG_ 1542 SD_RS_RBT_PASS 1;
BA_ "FlexKomSigStartValue" SG_ 1542 SD_RS_RBT_PASS "0000000000000000h";
BA_ "FlexKomSID" SG_ 1542 SD_RS_RBT_PASS 218;
BA_ "FlexKomSigStartPos" SG_ 1542 SD_RS_RBT_PASS 7;
BA_ "FlexKomSigLaenge" SG_ 1542 SD_RS_RBT_PASS 64;
BA_ "FlexKomSigName" SG_ 1542 SD_RS_RBT_PASS "SD_RS_RBT_PASS";
BA_ "FlexKomComment" SG_ 1542 SD_RS_RBT_PASS "Response on Event - light";
BA_ "FlexKomIsMotorola" SG_ 1542 SD_RS_RBT_PASS 1;
BA_ "GenSigSNA" SG_ 1542 SD_RS_RBT_PASS "0h";
BA_ "GenSigSendType" SG_ 1543 SD_RS_ESC 1;
BA_ "FlexKomSigStartValue" SG_ 1543 SD_RS_ESC "0000000000000000h";
BA_ "FlexKomSID" SG_ 1543 SD_RS_ESC 196;
BA_ "FlexKomSigStartPos" SG_ 1543 SD_RS_ESC 7;
BA_ "FlexKomSigLaenge" SG_ 1543 SD_RS_ESC 64;
BA_ "FlexKomSigName" SG_ 1543 SD_RS_ESC "SD_RS_ESC";
BA_ "FlexKomComment" SG_ 1543 SD_RS_ESC "Response on Event - light";
BA_ "FlexKomIsMotorola" SG_ 1543 SD_RS_ESC 1;
BA_ "GenSigSNA" SG_ 1543 SD_RS_ESC "0h";
BA_ "GenSigSendType" SG_ 1545 SD_RS_ESM 1;
BA_ "FlexKomSigStartValue" SG_ 1545 SD_RS_ESM "0000000000000000h";
BA_ "FlexKomSID" SG_ 1545 SD_RS_ESM 195;
BA_ "FlexKomSigStartPos" SG_ 1545 SD_RS_ESM 7;
BA_ "FlexKomSigLaenge" SG_ 1545 SD_RS_ESM 64;
BA_ "FlexKomSigName" SG_ 1545 SD_RS_ESM "SD_RS_ESM";
BA_ "FlexKomComment" SG_ 1545 SD_RS_ESM "Response on Event - light";
BA_ "FlexKomIsMotorola" SG_ 1545 SD_RS_ESM 1;
BA_ "GenSigSNA" SG_ 1545 SD_RS_ESM "0h";
BA_ "GenSigSendType" SG_ 1547 SD_RS_DTCM 1;
BA_ "FlexKomSigStartValue" SG_ 1547 SD_RS_DTCM "0000000000000000h";
BA_ "FlexKomSID" SG_ 1547 SD_RS_DTCM 191;
BA_ "FlexKomSigStartPos" SG_ 1547 SD_RS_DTCM 7;
BA_ "FlexKomSigLaenge" SG_ 1547 SD_RS_DTCM 64;
BA_ "FlexKomSigName" SG_ 1547 SD_RS_DTCM "SD_RS_DTCM";
BA_ "FlexKomComment" SG_ 1547 SD_RS_DTCM "Response on Event - light";
BA_ "FlexKomIsMotorola" SG_ 1547 SD_RS_DTCM 1;
BA_ "GenSigSNA" SG_ 1547 SD_RS_DTCM "0h";
BA_ "GenSigSendType" SG_ 1548 SD_RS_FDCM 1;
BA_ "FlexKomSigStartValue" SG_ 1548 SD_RS_FDCM "0000000000000000h";
BA_ "FlexKomSID" SG_ 1548 SD_RS_FDCM 1603;
BA_ "FlexKomSigStartPos" SG_ 1548 SD_RS_FDCM 7;
BA_ "FlexKomSigLaenge" SG_ 1548 SD_RS_FDCM 64;
BA_ "FlexKomSigName" SG_ 1548 SD_RS_FDCM "SD_RS_FDCM";
BA_ "FlexKomComment" SG_ 1548 SD_RS_FDCM "Response on Event - light";
BA_ "FlexKomIsMotorola" SG_ 1548 SD_RS_FDCM 1;
BA_ "GenSigSNA" SG_ 1548 SD_RS_FDCM "0h";
BA_ "GenSigSendType" SG_ 1555 SD_RS_DASM 1;
BA_ "FlexKomSigStartValue" SG_ 1555 SD_RS_DASM "0000000000000000h";
BA_ "FlexKomSID" SG_ 1555 SD_RS_DASM 203;
BA_ "FlexKomSigStartPos" SG_ 1555 SD_RS_DASM 7;
BA_ "FlexKomSigLaenge" SG_ 1555 SD_RS_DASM 64;
BA_ "FlexKomSigName" SG_ 1555 SD_RS_DASM "SD_RS_DASM";
BA_ "FlexKomComment" SG_ 1555 SD_RS_DASM "Response on Event - light";
BA_ "FlexKomIsMotorola" SG_ 1555 SD_RS_DASM 1;
BA_ "GenSigSNA" SG_ 1555 SD_RS_DASM "0h";
BA_ "GenSigSendType" SG_ 1556 SD_RS_ITBM 1;
BA_ "FlexKomSigStartValue" SG_ 1556 SD_RS_ITBM "0000000000000000h";
BA_ "FlexKomSID" SG_ 1556 SD_RS_ITBM 1482;
BA_ "FlexKomSigStartPos" SG_ 1556 SD_RS_ITBM 7;
BA_ "FlexKomSigLaenge" SG_ 1556 SD_RS_ITBM 64;
BA_ "FlexKomSigName" SG_ 1556 SD_RS_ITBM "SD_RS_ITBM";
BA_ "FlexKomComment" SG_ 1556 SD_RS_ITBM "Response on Event - light";
BA_ "FlexKomIsMotorola" SG_ 1556 SD_RS_ITBM 1;
BA_ "GenSigSNA" SG_ 1556 SD_RS_ITBM "0h";
BA_ "GenSigSendType" SG_ 1559 SD_RS_ADCM 1;
BA_ "FlexKomSigStartValue" SG_ 1559 SD_RS_ADCM "0000000000000000h";
BA_ "FlexKomSID" SG_ 1559 SD_RS_ADCM 177;
BA_ "FlexKomSigStartPos" SG_ 1559 SD_RS_ADCM 7;
BA_ "FlexKomSigLaenge" SG_ 1559 SD_RS_ADCM 64;
BA_ "FlexKomSigName" SG_ 1559 SD_RS_ADCM "SD_RS_ADCM";
BA_ "FlexKomComment" SG_ 1559 SD_RS_ADCM "Response on Event - light";
BA_ "FlexKomIsMotorola" SG_ 1559 SD_RS_ADCM 1;
BA_ "GenSigSNA" SG_ 1559 SD_RS_ADCM "0h";
BA_ "GenSigSendType" SG_ 1561 SD_RS_EPB 1;
BA_ "FlexKomSigStartValue" SG_ 1561 SD_RS_EPB "0000000000000000h";
BA_ "FlexKomSID" SG_ 1561 SD_RS_EPB 1475;
BA_ "FlexKomSigStartPos" SG_ 1561 SD_RS_EPB 7;
BA_ "FlexKomSigLaenge" SG_ 1561 SD_RS_EPB 64;
BA_ "FlexKomSigName" SG_ 1561 SD_RS_EPB "SD_RS_EPB";
BA_ "FlexKomComment" SG_ 1561 SD_RS_EPB "Response on Event - light";
BA_ "FlexKomIsMotorola" SG_ 1561 SD_RS_EPB 1;
BA_ "GenSigSNA" SG_ 1561 SD_RS_EPB "0h";
BA_ "GenSigSendType" SG_ 1562 SD_RS_EPS 1;
BA_ "FlexKomSigStartValue" SG_ 1562 SD_RS_EPS "0000000000000000h";
BA_ "FlexKomSID" SG_ 1562 SD_RS_EPS 194;
BA_ "FlexKomSigStartPos" SG_ 1562 SD_RS_EPS 7;
BA_ "FlexKomSigLaenge" SG_ 1562 SD_RS_EPS 64;
BA_ "FlexKomSigName" SG_ 1562 SD_RS_EPS "SD_RS_EPS";
BA_ "FlexKomComment" SG_ 1562 SD_RS_EPS "Response on Event - light";
BA_ "FlexKomIsMotorola" SG_ 1562 SD_RS_EPS 1;
BA_ "GenSigSNA" SG_ 1562 SD_RS_EPS "0h";
BA_ "GenSigSendType" SG_ 1566 SD_RS_OCM 9;
BA_ "GenSigCycleTime" SG_ 1566 SD_RS_OCM 200;
BA_ "FlexKomSigStartValue" SG_ 1566 SD_RS_OCM "0000000000000000h";
BA_ "FlexKomSID" SG_ 1566 SD_RS_OCM 1538;
BA_ "FlexKomSigStartPos" SG_ 1566 SD_RS_OCM 7;
BA_ "FlexKomSigLaenge" SG_ 1566 SD_RS_OCM 64;
BA_ "FlexKomSigName" SG_ 1566 SD_RS_OCM "SD_RS_OCM";
BA_ "FlexKomComment" SG_ 1566 SD_RS_OCM "Response on Event - light";
BA_ "FlexKomIsMotorola" SG_ 1566 SD_RS_OCM 1;
BA_ "GenSigSNA" SG_ 1566 SD_RS_OCM "0h";
BA_ "GenSigSendType" SG_ 1567 SD_RS_EPPM 1;
BA_ "FlexKomSigStartValue" SG_ 1567 SD_RS_EPPM "0000000000000000h";
BA_ "FlexKomSID" SG_ 1567 SD_RS_EPPM 1335;
BA_ "FlexKomSigStartPos" SG_ 1567 SD_RS_EPPM 7;
BA_ "FlexKomSigLaenge" SG_ 1567 SD_RS_EPPM 64;
BA_ "FlexKomSigName" SG_ 1567 SD_RS_EPPM "SD_RS_EPPM";
BA_ "FlexKomComment" SG_ 1567 SD_RS_EPPM "Response on Event - light";
BA_ "FlexKomIsMotorola" SG_ 1567 SD_RS_EPPM 1;
BA_ "GenSigSNA" SG_ 1567 SD_RS_EPPM "0h";
BA_ "FlexKomSigStartValue" SG_ 1568 D_RQ_CBC "0000000000000000h";
BA_ "FlexKomSID" SG_ 1568 D_RQ_CBC 78;
BA_ "FlexKomSigStartPos" SG_ 1568 D_RQ_CBC 7;
BA_ "FlexKomSigLaenge" SG_ 1568 D_RQ_CBC 64;
BA_ "FlexKomSigName" SG_ 1568 D_RQ_CBC "D_RQ_CBC";
BA_ "FlexKomComment" SG_ 1568 D_RQ_CBC "Diagnostic-Request";
BA_ "FlexKomIsMotorola" SG_ 1568 D_RQ_CBC 1;
BA_ "GenSigSNA" SG_ 1568 D_RQ_CBC "0h";
BA_ "GenSigSendType" SG_ 1570 SD_RS_PTS 1;
BA_ "FlexKomSigStartValue" SG_ 1570 SD_RS_PTS "0000000000000000h";
BA_ "FlexKomSID" SG_ 1570 SD_RS_PTS 215;
BA_ "FlexKomSigStartPos" SG_ 1570 SD_RS_PTS 7;
BA_ "FlexKomSigLaenge" SG_ 1570 SD_RS_PTS 64;
BA_ "FlexKomSigName" SG_ 1570 SD_RS_PTS "SD_RS_PTS";
BA_ "FlexKomComment" SG_ 1570 SD_RS_PTS "Response on Event - light";
BA_ "FlexKomIsMotorola" SG_ 1570 SD_RS_PTS 1;
BA_ "GenSigSNA" SG_ 1570 SD_RS_PTS "0h";
BA_ "GenSigSendType" SG_ 1571 SD_RS_SCCM 1;
BA_ "FlexKomSigStartValue" SG_ 1571 SD_RS_SCCM "0000000000000000h";
BA_ "FlexKomSID" SG_ 1571 SD_RS_SCCM 219;
BA_ "FlexKomSigStartPos" SG_ 1571 SD_RS_SCCM 7;
BA_ "FlexKomSigLaenge" SG_ 1571 SD_RS_SCCM 64;
BA_ "FlexKomSigName" SG_ 1571 SD_RS_SCCM "SD_RS_SCCM";
BA_ "FlexKomComment" SG_ 1571 SD_RS_SCCM "Response on Event - light";
BA_ "FlexKomIsMotorola" SG_ 1571 SD_RS_SCCM 1;
BA_ "GenSigSNA" SG_ 1571 SD_RS_SCCM "0h";
BA_ "GenSigSendType" SG_ 1572 SD_RS_HaLF 1;
BA_ "FlexKomSigStartValue" SG_ 1572 SD_RS_HaLF "0000000000000000h";
BA_ "FlexKomSID" SG_ 1572 SD_RS_HaLF 1635;
BA_ "FlexKomSigStartPos" SG_ 1572 SD_RS_HaLF 7;
BA_ "FlexKomSigLaenge" SG_ 1572 SD_RS_HaLF 64;
BA_ "FlexKomSigName" SG_ 1572 SD_RS_HaLF "SD_RS_HaLF";
BA_ "FlexKomComment" SG_ 1572 SD_RS_HaLF "Response on Event - light";
BA_ "FlexKomIsMotorola" SG_ 1572 SD_RS_HaLF 1;
BA_ "GenSigSNA" SG_ 1572 SD_RS_HaLF "0h";
BA_ "GenSigSendType" SG_ 1573 SD_RS_ANC 1;
BA_ "FlexKomSigStartValue" SG_ 1573 SD_RS_ANC "0000000000000000h";
BA_ "FlexKomSID" SG_ 1573 SD_RS_ANC 182;
BA_ "FlexKomSigStartPos" SG_ 1573 SD_RS_ANC 7;
BA_ "FlexKomSigLaenge" SG_ 1573 SD_RS_ANC 64;
BA_ "FlexKomSigName" SG_ 1573 SD_RS_ANC "SD_RS_ANC";
BA_ "FlexKomComment" SG_ 1573 SD_RS_ANC "Response on Event - light";
BA_ "FlexKomIsMotorola" SG_ 1573 SD_RS_ANC 1;
BA_ "GenSigSNA" SG_ 1573 SD_RS_ANC "0h";
BA_ "GenSigSendType" SG_ 1574 SD_RS_ASCM 1;
BA_ "FlexKomSigStartValue" SG_ 1574 SD_RS_ASCM "0000000000000000h";
BA_ "FlexKomSID" SG_ 1574 SD_RS_ASCM 183;
BA_ "FlexKomSigStartPos" SG_ 1574 SD_RS_ASCM 7;
BA_ "FlexKomSigLaenge" SG_ 1574 SD_RS_ASCM 64;
BA_ "FlexKomSigName" SG_ 1574 SD_RS_ASCM "SD_RS_ASCM";
BA_ "FlexKomComment" SG_ 1574 SD_RS_ASCM "Response on Event - light";
BA_ "FlexKomIsMotorola" SG_ 1574 SD_RS_ASCM 1;
BA_ "GenSigSNA" SG_ 1574 SD_RS_ASCM "0h";
BA_ "GenSigSendType" SG_ 1576 SD_RS_AFLS 1;
BA_ "FlexKomSigStartValue" SG_ 1576 SD_RS_AFLS "0000000000000000h";
BA_ "FlexKomSID" SG_ 1576 SD_RS_AFLS 178;
BA_ "FlexKomSigStartPos" SG_ 1576 SD_RS_AFLS 7;
BA_ "FlexKomSigLaenge" SG_ 1576 SD_RS_AFLS 64;
BA_ "FlexKomSigName" SG_ 1576 SD_RS_AFLS "SD_RS_AFLS";
BA_ "FlexKomComment" SG_ 1576 SD_RS_AFLS "Response on Event - light";
BA_ "FlexKomIsMotorola" SG_ 1576 SD_RS_AFLS 1;
BA_ "GenSigSNA" SG_ 1576 SD_RS_AFLS "0h";
BA_ "GenSigSendType" SG_ 1577 SD_RS_AHLM 1;
BA_ "FlexKomSigStartValue" SG_ 1577 SD_RS_AHLM "0000000000000000h";
BA_ "FlexKomSID" SG_ 1577 SD_RS_AHLM 180;
BA_ "FlexKomSigStartPos" SG_ 1577 SD_RS_AHLM 7;
BA_ "FlexKomSigLaenge" SG_ 1577 SD_RS_AHLM 64;
BA_ "FlexKomSigName" SG_ 1577 SD_RS_AHLM "SD_RS_AHLM";
BA_ "FlexKomComment" SG_ 1577 SD_RS_AHLM "Response on Event - light";
BA_ "FlexKomIsMotorola" SG_ 1577 SD_RS_AHLM 1;
BA_ "GenSigSNA" SG_ 1577 SD_RS_AHLM "0h";
BA_ "GenSigSendType" SG_ 1584 SD_RS_ELSD 1;
BA_ "FlexKomSigStartValue" SG_ 1584 SD_RS_ELSD "0000000000000000h";
BA_ "FlexKomSID" SG_ 1584 SD_RS_ELSD 1595;
BA_ "FlexKomSigStartPos" SG_ 1584 SD_RS_ELSD 7;
BA_ "FlexKomSigLaenge" SG_ 1584 SD_RS_ELSD 64;
BA_ "FlexKomSigName" SG_ 1584 SD_RS_ELSD "SD_RS_ELSD";
BA_ "FlexKomComment" SG_ 1584 SD_RS_ELSD "Response on Event - light";
BA_ "FlexKomIsMotorola" SG_ 1584 SD_RS_ELSD 1;
BA_ "GenSigSNA" SG_ 1584 SD_RS_ELSD "0h";
BA_ "GenSigSendType" SG_ 1585 SD_RS_VSIM 1;
BA_ "FlexKomSigStartValue" SG_ 1585 SD_RS_VSIM "0000000000000000h";
BA_ "FlexKomSID" SG_ 1585 SD_RS_VSIM 228;
BA_ "FlexKomSigStartPos" SG_ 1585 SD_RS_VSIM 7;
BA_ "FlexKomSigLaenge" SG_ 1585 SD_RS_VSIM 64;
BA_ "FlexKomSigName" SG_ 1585 SD_RS_VSIM "SD_RS_VSIM";
BA_ "FlexKomComment" SG_ 1585 SD_RS_VSIM "Response on Event - light";
BA_ "FlexKomIsMotorola" SG_ 1585 SD_RS_VSIM 1;
BA_ "GenSigSNA" SG_ 1585 SD_RS_VSIM "0h";
BA_ "GenSigSendType" SG_ 1592 SD_RS_ECM 1;
BA_ "FlexKomSigStartValue" SG_ 1592 SD_RS_ECM "0000000000000000h";
BA_ "FlexKomSID" SG_ 1592 SD_RS_ECM 192;
BA_ "FlexKomSigStartPos" SG_ 1592 SD_RS_ECM 7;
BA_ "FlexKomSigLaenge" SG_ 1592 SD_RS_ECM 64;
BA_ "FlexKomSigName" SG_ 1592 SD_RS_ECM "SD_RS_ECM";
BA_ "FlexKomComment" SG_ 1592 SD_RS_ECM "Response on Event - light";
BA_ "FlexKomIsMotorola" SG_ 1592 SD_RS_ECM 1;
BA_ "GenSigSNA" SG_ 1592 SD_RS_ECM "0h";
BA_ "GenSigSendType" SG_ 1593 SD_RS_TCM 1;
BA_ "FlexKomSigStartValue" SG_ 1593 SD_RS_TCM "0000000000000000h";
BA_ "FlexKomSID" SG_ 1593 SD_RS_TCM 223;
BA_ "FlexKomSigStartPos" SG_ 1593 SD_RS_TCM 7;
BA_ "FlexKomSigLaenge" SG_ 1593 SD_RS_TCM 64;
BA_ "FlexKomSigName" SG_ 1593 SD_RS_TCM "SD_RS_TCM";
BA_ "FlexKomComment" SG_ 1593 SD_RS_TCM "Response on Event - light";
BA_ "FlexKomIsMotorola" SG_ 1593 SD_RS_TCM 1;
BA_ "GenSigSNA" SG_ 1593 SD_RS_TCM "0h";
BA_ "GenSigSendType" SG_ 1728 APPL_ECU_RF_HUB 1;
BA_ "FlexKomSigStartValue" SG_ 1728 APPL_ECU_RF_HUB "0000000000000000h";
BA_ "FlexKomSID" SG_ 1728 APPL_ECU_RF_HUB 293;
BA_ "FlexKomSigStartPos" SG_ 1728 APPL_ECU_RF_HUB 7;
BA_ "FlexKomSigLaenge" SG_ 1728 APPL_ECU_RF_HUB 64;
BA_ "FlexKomSigName" SG_ 1728 APPL_ECU_RF_HUB "APPL_ECU_RF_HUB";
BA_ "FlexKomComment" SG_ 1728 APPL_ECU_RF_HUB "External Application to ECU";
BA_ "FlexKomIsMotorola" SG_ 1728 APPL_ECU_RF_HUB 1;
BA_ "GenSigSNA" SG_ 1728 APPL_ECU_RF_HUB "0h";
BA_ "GenSigSendType" SG_ 1729 APPL_ECU_CBC 1;
BA_ "FlexKomSigStartValue" SG_ 1729 APPL_ECU_CBC "0000000000000000h";
BA_ "FlexKomSID" SG_ 1729 APPL_ECU_CBC 280;
BA_ "FlexKomSigStartPos" SG_ 1729 APPL_ECU_CBC 7;
BA_ "FlexKomSigLaenge" SG_ 1729 APPL_ECU_CBC 64;
BA_ "FlexKomSigName" SG_ 1729 APPL_ECU_CBC "APPL_ECU_CBC";
BA_ "FlexKomComment" SG_ 1729 APPL_ECU_CBC "External Application to ECU";
BA_ "FlexKomIsMotorola" SG_ 1729 APPL_ECU_CBC 1;
BA_ "GenSigSNA" SG_ 1729 APPL_ECU_CBC "0h";
BA_ "GenSigSendType" SG_ 1730 APPL_ECU_IC 1;
BA_ "FlexKomSigStartValue" SG_ 1730 APPL_ECU_IC "0000000000000000h";
BA_ "FlexKomSID" SG_ 1730 APPL_ECU_IC 296;
BA_ "FlexKomSigStartPos" SG_ 1730 APPL_ECU_IC 7;
BA_ "FlexKomSigLaenge" SG_ 1730 APPL_ECU_IC 64;
BA_ "FlexKomSigName" SG_ 1730 APPL_ECU_IC "APPL_ECU_IC";
BA_ "FlexKomComment" SG_ 1730 APPL_ECU_IC "External Application to ECU";
BA_ "FlexKomIsMotorola" SG_ 1730 APPL_ECU_IC 1;
BA_ "GenSigSNA" SG_ 1730 APPL_ECU_IC "0h";
BA_ "GenSigSendType" SG_ 1731 APPL_ECU_TPM 1;
BA_ "FlexKomSigStartValue" SG_ 1731 APPL_ECU_TPM "0000000000000000h";
BA_ "FlexKomSID" SG_ 1731 APPL_ECU_TPM 321;
BA_ "FlexKomSigStartPos" SG_ 1731 APPL_ECU_TPM 7;
BA_ "FlexKomSigLaenge" SG_ 1731 APPL_ECU_TPM 64;
BA_ "FlexKomSigName" SG_ 1731 APPL_ECU_TPM "APPL_ECU_TPM";
BA_ "FlexKomComment" SG_ 1731 APPL_ECU_TPM "External Application to ECU";
BA_ "FlexKomIsMotorola" SG_ 1731 APPL_ECU_TPM 1;
BA_ "GenSigSNA" SG_ 1731 APPL_ECU_TPM "0h";
BA_ "GenSigSendType" SG_ 1732 APPL_ECU_ORC 1;
BA_ "FlexKomSigStartValue" SG_ 1732 APPL_ECU_ORC "0000000000000000h";
BA_ "FlexKomSID" SG_ 1732 APPL_ECU_ORC 302;
BA_ "FlexKomSigStartPos" SG_ 1732 APPL_ECU_ORC 7;
BA_ "FlexKomSigLaenge" SG_ 1732 APPL_ECU_ORC 64;
BA_ "FlexKomSigName" SG_ 1732 APPL_ECU_ORC "APPL_ECU_ORC";
BA_ "FlexKomComment" SG_ 1732 APPL_ECU_ORC "External Application to ECU";
BA_ "FlexKomIsMotorola" SG_ 1732 APPL_ECU_ORC 1;
BA_ "GenSigSNA" SG_ 1732 APPL_ECU_ORC "0h";
BA_ "GenSigSendType" SG_ 1733 APPL_ECU_RBT_DR 1;
BA_ "FlexKomSigStartValue" SG_ 1733 APPL_ECU_RBT_DR "0000000000000000h";
BA_ "FlexKomSID" SG_ 1733 APPL_ECU_RBT_DR 312;
BA_ "FlexKomSigStartPos" SG_ 1733 APPL_ECU_RBT_DR 7;
BA_ "FlexKomSigLaenge" SG_ 1733 APPL_ECU_RBT_DR 64;
BA_ "FlexKomSigName" SG_ 1733 APPL_ECU_RBT_DR "APPL_ECU_RBT_DR";
BA_ "FlexKomComment" SG_ 1733 APPL_ECU_RBT_DR "External Application to ECU";
BA_ "FlexKomIsMotorola" SG_ 1733 APPL_ECU_RBT_DR 1;
BA_ "GenSigSNA" SG_ 1733 APPL_ECU_RBT_DR "0h";
BA_ "GenSigSendType" SG_ 1734 APPL_ECU_RBT_PASS 1;
BA_ "FlexKomSigStartValue" SG_ 1734 APPL_ECU_RBT_PASS "0000000000000000h";
BA_ "FlexKomSID" SG_ 1734 APPL_ECU_RBT_PASS 313;
BA_ "FlexKomSigStartPos" SG_ 1734 APPL_ECU_RBT_PASS 7;
BA_ "FlexKomSigLaenge" SG_ 1734 APPL_ECU_RBT_PASS 64;
BA_ "FlexKomSigName" SG_ 1734 APPL_ECU_RBT_PASS "APPL_ECU_RBT_PASS";
BA_ "FlexKomComment" SG_ 1734 APPL_ECU_RBT_PASS "External Application to ECU";
BA_ "FlexKomIsMotorola" SG_ 1734 APPL_ECU_RBT_PASS 1;
BA_ "GenSigSNA" SG_ 1734 APPL_ECU_RBT_PASS "0h";
BA_ "GenSigSendType" SG_ 1735 APPL_ECU_ESC 1;
BA_ "FlexKomSigStartValue" SG_ 1735 APPL_ECU_ESC "0000000000000000h";
BA_ "FlexKomSID" SG_ 1735 APPL_ECU_ESC 291;
BA_ "FlexKomSigStartPos" SG_ 1735 APPL_ECU_ESC 7;
BA_ "FlexKomSigLaenge" SG_ 1735 APPL_ECU_ESC 64;
BA_ "FlexKomSigName" SG_ 1735 APPL_ECU_ESC "APPL_ECU_ESC";
BA_ "FlexKomComment" SG_ 1735 APPL_ECU_ESC "External Application to ECU";
BA_ "FlexKomIsMotorola" SG_ 1735 APPL_ECU_ESC 1;
BA_ "GenSigSNA" SG_ 1735 APPL_ECU_ESC "0h";
BA_ "GenSigSendType" SG_ 1737 APPL_ECU_ESM 1;
BA_ "FlexKomSigStartValue" SG_ 1737 APPL_ECU_ESM "0000000000000000h";
BA_ "FlexKomSID" SG_ 1737 APPL_ECU_ESM 290;
BA_ "FlexKomSigStartPos" SG_ 1737 APPL_ECU_ESM 7;
BA_ "FlexKomSigLaenge" SG_ 1737 APPL_ECU_ESM 64;
BA_ "FlexKomSigName" SG_ 1737 APPL_ECU_ESM "APPL_ECU_ESM";
BA_ "FlexKomComment" SG_ 1737 APPL_ECU_ESM "External Application to ECU";
BA_ "FlexKomIsMotorola" SG_ 1737 APPL_ECU_ESM 1;
BA_ "GenSigSNA" SG_ 1737 APPL_ECU_ESM "0h";
BA_ "GenSigSendType" SG_ 1739 APPL_ECU_DTCM 1;
BA_ "FlexKomSigStartValue" SG_ 1739 APPL_ECU_DTCM "0000000000000000h";
BA_ "FlexKomSID" SG_ 1739 APPL_ECU_DTCM 286;
BA_ "FlexKomSigStartPos" SG_ 1739 APPL_ECU_DTCM 7;
BA_ "FlexKomSigLaenge" SG_ 1739 APPL_ECU_DTCM 64;
BA_ "FlexKomSigName" SG_ 1739 APPL_ECU_DTCM "APPL_ECU_DTCM";
BA_ "FlexKomComment" SG_ 1739 APPL_ECU_DTCM "External Application to ECU";
BA_ "FlexKomIsMotorola" SG_ 1739 APPL_ECU_DTCM 1;
BA_ "GenSigSNA" SG_ 1739 APPL_ECU_DTCM "0h";
BA_ "GenSigSendType" SG_ 1740 APPL_ECU_FDCM 1;
BA_ "FlexKomSigStartValue" SG_ 1740 APPL_ECU_FDCM "0000000000000000h";
BA_ "FlexKomSID" SG_ 1740 APPL_ECU_FDCM 1600;
BA_ "FlexKomSigStartPos" SG_ 1740 APPL_ECU_FDCM 7;
BA_ "FlexKomSigLaenge" SG_ 1740 APPL_ECU_FDCM 64;
BA_ "FlexKomSigName" SG_ 1740 APPL_ECU_FDCM "APPL_ECU_FDCM";
BA_ "FlexKomComment" SG_ 1740 APPL_ECU_FDCM "External Application to ECU";
BA_ "FlexKomIsMotorola" SG_ 1740 APPL_ECU_FDCM 1;
BA_ "GenSigSNA" SG_ 1740 APPL_ECU_FDCM "0h";
BA_ "GenSigSendType" SG_ 1747 APPL_ECU_DASM 1;
BA_ "FlexKomSigStartValue" SG_ 1747 APPL_ECU_DASM "0000000000000000h";
BA_ "FlexKomSID" SG_ 1747 APPL_ECU_DASM 298;
BA_ "FlexKomSigStartPos" SG_ 1747 APPL_ECU_DASM 7;
BA_ "FlexKomSigLaenge" SG_ 1747 APPL_ECU_DASM 64;
BA_ "FlexKomSigName" SG_ 1747 APPL_ECU_DASM "APPL_ECU_DASM";
BA_ "FlexKomComment" SG_ 1747 APPL_ECU_DASM "External Application to ECU";
BA_ "FlexKomIsMotorola" SG_ 1747 APPL_ECU_DASM 1;
BA_ "GenSigSNA" SG_ 1747 APPL_ECU_DASM "0h";
BA_ "GenSigSendType" SG_ 1748 APPL_ECU_ITBM 1;
BA_ "FlexKomSigStartValue" SG_ 1748 APPL_ECU_ITBM "0000000000000000h";
BA_ "FlexKomSID" SG_ 1748 APPL_ECU_ITBM 1483;
BA_ "FlexKomSigStartPos" SG_ 1748 APPL_ECU_ITBM 7;
BA_ "FlexKomSigLaenge" SG_ 1748 APPL_ECU_ITBM 64;
BA_ "FlexKomSigName" SG_ 1748 APPL_ECU_ITBM "APPL_ECU_ITBM";
BA_ "FlexKomComment" SG_ 1748 APPL_ECU_ITBM "External Application to ECU";
BA_ "FlexKomIsMotorola" SG_ 1748 APPL_ECU_ITBM 1;
BA_ "GenSigSNA" SG_ 1748 APPL_ECU_ITBM "0h";
BA_ "GenSigSendType" SG_ 1751 APPL_ECU_ADCM 1;
BA_ "FlexKomSigStartValue" SG_ 1751 APPL_ECU_ADCM "0000000000000000h";
BA_ "FlexKomSID" SG_ 1751 APPL_ECU_ADCM 272;
BA_ "FlexKomSigStartPos" SG_ 1751 APPL_ECU_ADCM 7;
BA_ "FlexKomSigLaenge" SG_ 1751 APPL_ECU_ADCM 64;
BA_ "FlexKomSigName" SG_ 1751 APPL_ECU_ADCM "APPL_ECU_ADCM";
BA_ "FlexKomComment" SG_ 1751 APPL_ECU_ADCM "External Application to ECU";
BA_ "FlexKomIsMotorola" SG_ 1751 APPL_ECU_ADCM 1;
BA_ "GenSigSNA" SG_ 1751 APPL_ECU_ADCM "0h";
BA_ "GenSigSendType" SG_ 1753 APPL_ECU_EPB 1;
BA_ "FlexKomSigStartValue" SG_ 1753 APPL_ECU_EPB "0000000000000000h";
BA_ "FlexKomSID" SG_ 1753 APPL_ECU_EPB 1476;
BA_ "FlexKomSigStartPos" SG_ 1753 APPL_ECU_EPB 7;
BA_ "FlexKomSigLaenge" SG_ 1753 APPL_ECU_EPB 64;
BA_ "FlexKomSigName" SG_ 1753 APPL_ECU_EPB "APPL_ECU_EPB";
BA_ "FlexKomComment" SG_ 1753 APPL_ECU_EPB "External Application to ECU";
BA_ "FlexKomIsMotorola" SG_ 1753 APPL_ECU_EPB 1;
BA_ "GenSigSNA" SG_ 1753 APPL_ECU_EPB "0h";
BA_ "GenSigSendType" SG_ 1754 APPL_ECU_EPS 1;
BA_ "FlexKomSigStartValue" SG_ 1754 APPL_ECU_EPS "0000000000000000h";
BA_ "FlexKomSID" SG_ 1754 APPL_ECU_EPS 289;
BA_ "FlexKomSigStartPos" SG_ 1754 APPL_ECU_EPS 7;
BA_ "FlexKomSigLaenge" SG_ 1754 APPL_ECU_EPS 64;
BA_ "FlexKomSigName" SG_ 1754 APPL_ECU_EPS "APPL_ECU_EPS";
BA_ "FlexKomComment" SG_ 1754 APPL_ECU_EPS "External Application to ECU";
BA_ "FlexKomIsMotorola" SG_ 1754 APPL_ECU_EPS 1;
BA_ "GenSigSNA" SG_ 1754 APPL_ECU_EPS "0h";
BA_ "GenSigSendType" SG_ 1758 APPL_ECU_OCM 1;
BA_ "FlexKomSigStartValue" SG_ 1758 APPL_ECU_OCM "0000000000000000h";
BA_ "FlexKomSID" SG_ 1758 APPL_ECU_OCM 1539;
BA_ "FlexKomSigStartPos" SG_ 1758 APPL_ECU_OCM 7;
BA_ "FlexKomSigLaenge" SG_ 1758 APPL_ECU_OCM 64;
BA_ "FlexKomSigName" SG_ 1758 APPL_ECU_OCM "APPL_ECU_OCM";
BA_ "FlexKomComment" SG_ 1758 APPL_ECU_OCM "External Application to ECU";
BA_ "FlexKomIsMotorola" SG_ 1758 APPL_ECU_OCM 1;
BA_ "GenSigSNA" SG_ 1758 APPL_ECU_OCM "0h";
BA_ "GenSigSendType" SG_ 1759 APPL_ECU_EPPM 1;
BA_ "FlexKomSigStartValue" SG_ 1759 APPL_ECU_EPPM "0000000000000000h";
BA_ "FlexKomSID" SG_ 1759 APPL_ECU_EPPM 1337;
BA_ "FlexKomSigStartPos" SG_ 1759 APPL_ECU_EPPM 7;
BA_ "FlexKomSigLaenge" SG_ 1759 APPL_ECU_EPPM 64;
BA_ "FlexKomSigName" SG_ 1759 APPL_ECU_EPPM "APPL_ECU_EPPM";
BA_ "FlexKomComment" SG_ 1759 APPL_ECU_EPPM "External Application to ECU";
BA_ "FlexKomIsMotorola" SG_ 1759 APPL_ECU_EPPM 1;
BA_ "GenSigSNA" SG_ 1759 APPL_ECU_EPPM "0h";
BA_ "GenSigSendType" SG_ 1762 APPL_ECU_PTS 1;
BA_ "FlexKomSigStartValue" SG_ 1762 APPL_ECU_PTS "0000000000000000h";
BA_ "FlexKomSID" SG_ 1762 APPL_ECU_PTS 310;
BA_ "FlexKomSigStartPos" SG_ 1762 APPL_ECU_PTS 7;
BA_ "FlexKomSigLaenge" SG_ 1762 APPL_ECU_PTS 64;
BA_ "FlexKomSigName" SG_ 1762 APPL_ECU_PTS "APPL_ECU_PTS";
BA_ "FlexKomComment" SG_ 1762 APPL_ECU_PTS "External Application to ECU";
BA_ "FlexKomIsMotorola" SG_ 1762 APPL_ECU_PTS 1;
BA_ "GenSigSNA" SG_ 1762 APPL_ECU_PTS "0h";
BA_ "GenSigSendType" SG_ 1763 APPL_ECU_SCCM 1;
BA_ "FlexKomSigStartValue" SG_ 1763 APPL_ECU_SCCM "0000000000000000h";
BA_ "FlexKomSID" SG_ 1763 APPL_ECU_SCCM 314;
BA_ "FlexKomSigStartPos" SG_ 1763 APPL_ECU_SCCM 7;
BA_ "FlexKomSigLaenge" SG_ 1763 APPL_ECU_SCCM 64;
BA_ "FlexKomSigName" SG_ 1763 APPL_ECU_SCCM "APPL_ECU_SCCM";
BA_ "FlexKomComment" SG_ 1763 APPL_ECU_SCCM "External Application to ECU";
BA_ "FlexKomIsMotorola" SG_ 1763 APPL_ECU_SCCM 1;
BA_ "GenSigSNA" SG_ 1763 APPL_ECU_SCCM "0h";
BA_ "GenSigSendType" SG_ 1764 APPL_ECU_HaLF 1;
BA_ "FlexKomSigStartValue" SG_ 1764 APPL_ECU_HaLF "0000000000000000h";
BA_ "FlexKomSID" SG_ 1764 APPL_ECU_HaLF 1631;
BA_ "FlexKomSigStartPos" SG_ 1764 APPL_ECU_HaLF 7;
BA_ "FlexKomSigLaenge" SG_ 1764 APPL_ECU_HaLF 64;
BA_ "FlexKomSigName" SG_ 1764 APPL_ECU_HaLF "APPL_ECU_HaLF";
BA_ "FlexKomComment" SG_ 1764 APPL_ECU_HaLF "External Application to ECU";
BA_ "FlexKomIsMotorola" SG_ 1764 APPL_ECU_HaLF 1;
BA_ "GenSigSNA" SG_ 1764 APPL_ECU_HaLF "0h";
BA_ "GenSigSendType" SG_ 1765 APPL_ECU_ANC 1;
BA_ "FlexKomSigStartValue" SG_ 1765 APPL_ECU_ANC "0000000000000000h";
BA_ "FlexKomSID" SG_ 1765 APPL_ECU_ANC 277;
BA_ "FlexKomSigStartPos" SG_ 1765 APPL_ECU_ANC 7;
BA_ "FlexKomSigLaenge" SG_ 1765 APPL_ECU_ANC 64;
BA_ "FlexKomSigName" SG_ 1765 APPL_ECU_ANC "APPL_ECU_ANC";
BA_ "FlexKomComment" SG_ 1765 APPL_ECU_ANC "External Application to ECU";
BA_ "FlexKomIsMotorola" SG_ 1765 APPL_ECU_ANC 1;
BA_ "GenSigSNA" SG_ 1765 APPL_ECU_ANC "0h";
BA_ "GenSigSendType" SG_ 1766 APPL_ECU_ASCM 1;
BA_ "FlexKomSigStartValue" SG_ 1766 APPL_ECU_ASCM "0000000000000000h";
BA_ "FlexKomSID" SG_ 1766 APPL_ECU_ASCM 278;
BA_ "FlexKomSigStartPos" SG_ 1766 APPL_ECU_ASCM 7;
BA_ "FlexKomSigLaenge" SG_ 1766 APPL_ECU_ASCM 64;
BA_ "FlexKomSigName" SG_ 1766 APPL_ECU_ASCM "APPL_ECU_ASCM";
BA_ "FlexKomComment" SG_ 1766 APPL_ECU_ASCM "External Application to ECU";
BA_ "FlexKomIsMotorola" SG_ 1766 APPL_ECU_ASCM 1;
BA_ "GenSigSNA" SG_ 1766 APPL_ECU_ASCM "0h";
BA_ "GenSigSendType" SG_ 1768 APPL_ECU_AFLS 1;
BA_ "FlexKomSigStartValue" SG_ 1768 APPL_ECU_AFLS "0000000000000000h";
BA_ "FlexKomSID" SG_ 1768 APPL_ECU_AFLS 273;
BA_ "FlexKomSigStartPos" SG_ 1768 APPL_ECU_AFLS 7;
BA_ "FlexKomSigLaenge" SG_ 1768 APPL_ECU_AFLS 64;
BA_ "FlexKomSigName" SG_ 1768 APPL_ECU_AFLS "APPL_ECU_AFLS";
BA_ "FlexKomComment" SG_ 1768 APPL_ECU_AFLS "External Application to ECU";
BA_ "FlexKomIsMotorola" SG_ 1768 APPL_ECU_AFLS 1;
BA_ "GenSigSNA" SG_ 1768 APPL_ECU_AFLS "0h";
BA_ "GenSigSendType" SG_ 1769 APPL_ECU_AHLM 1;
BA_ "FlexKomSigStartValue" SG_ 1769 APPL_ECU_AHLM "0000000000000000h";
BA_ "FlexKomSID" SG_ 1769 APPL_ECU_AHLM 275;
BA_ "FlexKomSigStartPos" SG_ 1769 APPL_ECU_AHLM 7;
BA_ "FlexKomSigLaenge" SG_ 1769 APPL_ECU_AHLM 64;
BA_ "FlexKomSigName" SG_ 1769 APPL_ECU_AHLM "APPL_ECU_AHLM";
BA_ "FlexKomComment" SG_ 1769 APPL_ECU_AHLM "External Application to ECU";
BA_ "FlexKomIsMotorola" SG_ 1769 APPL_ECU_AHLM 1;
BA_ "GenSigSNA" SG_ 1769 APPL_ECU_AHLM "0h";
BA_ "GenSigSendType" SG_ 1776 APPL_ECU_ELSD 1;
BA_ "FlexKomSigStartValue" SG_ 1776 APPL_ECU_ELSD "0000000000000000h";
BA_ "FlexKomSID" SG_ 1776 APPL_ECU_ELSD 1597;
BA_ "FlexKomSigStartPos" SG_ 1776 APPL_ECU_ELSD 7;
BA_ "FlexKomSigLaenge" SG_ 1776 APPL_ECU_ELSD 64;
BA_ "FlexKomSigName" SG_ 1776 APPL_ECU_ELSD "APPL_ECU_ELSD";
BA_ "FlexKomComment" SG_ 1776 APPL_ECU_ELSD "External Application to ECU";
BA_ "FlexKomIsMotorola" SG_ 1776 APPL_ECU_ELSD 1;
BA_ "GenSigSNA" SG_ 1776 APPL_ECU_ELSD "0h";
BA_ "GenSigSendType" SG_ 1777 APPL_ECU_VSIM 1;
BA_ "FlexKomSigStartValue" SG_ 1777 APPL_ECU_VSIM "0000000000000000h";
BA_ "FlexKomSID" SG_ 1777 APPL_ECU_VSIM 323;
BA_ "FlexKomSigStartPos" SG_ 1777 APPL_ECU_VSIM 7;
BA_ "FlexKomSigLaenge" SG_ 1777 APPL_ECU_VSIM 64;
BA_ "FlexKomSigName" SG_ 1777 APPL_ECU_VSIM "APPL_ECU_VSIM";
BA_ "FlexKomComment" SG_ 1777 APPL_ECU_VSIM "External Application to ECU";
BA_ "FlexKomIsMotorola" SG_ 1777 APPL_ECU_VSIM 1;
BA_ "GenSigSNA" SG_ 1777 APPL_ECU_VSIM "0h";
BA_ "GenSigSendType" SG_ 1784 APPL_ECU_ECM 1;
BA_ "FlexKomSigStartValue" SG_ 1784 APPL_ECU_ECM "0000000000000000h";
BA_ "FlexKomSID" SG_ 1784 APPL_ECU_ECM 287;
BA_ "FlexKomSigStartPos" SG_ 1784 APPL_ECU_ECM 7;
BA_ "FlexKomSigLaenge" SG_ 1784 APPL_ECU_ECM 64;
BA_ "FlexKomSigName" SG_ 1784 APPL_ECU_ECM "APPL_ECU_ECM";
BA_ "FlexKomComment" SG_ 1784 APPL_ECU_ECM "External Application to ECU";
BA_ "FlexKomIsMotorola" SG_ 1784 APPL_ECU_ECM 1;
BA_ "GenSigSNA" SG_ 1784 APPL_ECU_ECM "0h";
BA_ "GenSigSendType" SG_ 1785 APPL_ECU_TCM 1;
BA_ "FlexKomSigStartValue" SG_ 1785 APPL_ECU_TCM "0000000000000000h";
BA_ "FlexKomSID" SG_ 1785 APPL_ECU_TCM 318;
BA_ "FlexKomSigStartPos" SG_ 1785 APPL_ECU_TCM 7;
BA_ "FlexKomSigLaenge" SG_ 1785 APPL_ECU_TCM 64;
BA_ "FlexKomSigName" SG_ 1785 APPL_ECU_TCM "APPL_ECU_TCM";
BA_ "FlexKomComment" SG_ 1785 APPL_ECU_TCM "External Application to ECU";
BA_ "FlexKomIsMotorola" SG_ 1785 APPL_ECU_TCM 1;
BA_ "GenSigSNA" SG_ 1785 APPL_ECU_TCM "0h";
BA_ "FlexKomSigStartValue" SG_ 1856 D_RQ_RF_HUB "0000000000000000h";
BA_ "FlexKomSID" SG_ 1856 D_RQ_RF_HUB 92;
BA_ "FlexKomSigStartPos" SG_ 1856 D_RQ_RF_HUB 7;
BA_ "FlexKomSigLaenge" SG_ 1856 D_RQ_RF_HUB 64;
BA_ "FlexKomSigName" SG_ 1856 D_RQ_RF_HUB "D_RQ_RF_HUB";
BA_ "FlexKomComment" SG_ 1856 D_RQ_RF_HUB "Diagnostic-Request";
BA_ "FlexKomIsMotorola" SG_ 1856 D_RQ_RF_HUB 1;
BA_ "GenSigSNA" SG_ 1856 D_RQ_RF_HUB "0h";
BA_ "FlexKomSigStartValue" SG_ 1858 D_RQ_IC "0000000000000000h";
BA_ "FlexKomSID" SG_ 1858 D_RQ_IC 95;
BA_ "FlexKomSigStartPos" SG_ 1858 D_RQ_IC 7;
BA_ "FlexKomSigLaenge" SG_ 1858 D_RQ_IC 64;
BA_ "FlexKomSigName" SG_ 1858 D_RQ_IC "D_RQ_IC";
BA_ "FlexKomComment" SG_ 1858 D_RQ_IC "Diagnostic-Request";
BA_ "FlexKomIsMotorola" SG_ 1858 D_RQ_IC 1;
BA_ "GenSigSNA" SG_ 1858 D_RQ_IC "0h";
BA_ "FlexKomSigStartValue" SG_ 1859 D_RQ_TPM "0000000000000000h";
BA_ "FlexKomSID" SG_ 1859 D_RQ_TPM 120;
BA_ "FlexKomSigStartPos" SG_ 1859 D_RQ_TPM 7;
BA_ "FlexKomSigLaenge" SG_ 1859 D_RQ_TPM 64;
BA_ "FlexKomSigName" SG_ 1859 D_RQ_TPM "D_RQ_TPM";
BA_ "FlexKomComment" SG_ 1859 D_RQ_TPM "Diagnostic-Request";
BA_ "FlexKomIsMotorola" SG_ 1859 D_RQ_TPM 1;
BA_ "GenSigSNA" SG_ 1859 D_RQ_TPM "0h";
BA_ "FlexKomSigStartValue" SG_ 1860 D_RQ_ORC "0000000000000000h";
BA_ "FlexKomSID" SG_ 1860 D_RQ_ORC 101;
BA_ "FlexKomSigStartPos" SG_ 1860 D_RQ_ORC 7;
BA_ "FlexKomSigLaenge" SG_ 1860 D_RQ_ORC 64;
BA_ "FlexKomSigName" SG_ 1860 D_RQ_ORC "D_RQ_ORC";
BA_ "FlexKomComment" SG_ 1860 D_RQ_ORC "Diagnostic-Request";
BA_ "FlexKomIsMotorola" SG_ 1860 D_RQ_ORC 1;
BA_ "GenSigSNA" SG_ 1860 D_RQ_ORC "0h";
BA_ "FlexKomSigStartValue" SG_ 1861 D_RQ_RBT_DR "0000000000000000h";
BA_ "FlexKomSID" SG_ 1861 D_RQ_RBT_DR 111;
BA_ "FlexKomSigStartPos" SG_ 1861 D_RQ_RBT_DR 7;
BA_ "FlexKomSigLaenge" SG_ 1861 D_RQ_RBT_DR 64;
BA_ "FlexKomSigName" SG_ 1861 D_RQ_RBT_DR "D_RQ_RBT_DR";
BA_ "FlexKomComment" SG_ 1861 D_RQ_RBT_DR "Diagnostic-Request";
BA_ "FlexKomIsMotorola" SG_ 1861 D_RQ_RBT_DR 1;
BA_ "GenSigSNA" SG_ 1861 D_RQ_RBT_DR "0h";
BA_ "FlexKomSigStartValue" SG_ 1862 D_RQ_RBT_PASS "0000000000000000h";
BA_ "FlexKomSID" SG_ 1862 D_RQ_RBT_PASS 112;
BA_ "FlexKomSigStartPos" SG_ 1862 D_RQ_RBT_PASS 7;
BA_ "FlexKomSigLaenge" SG_ 1862 D_RQ_RBT_PASS 64;
BA_ "FlexKomSigName" SG_ 1862 D_RQ_RBT_PASS "D_RQ_RBT_PASS";
BA_ "FlexKomComment" SG_ 1862 D_RQ_RBT_PASS "Diagnostic-Request";
BA_ "FlexKomIsMotorola" SG_ 1862 D_RQ_RBT_PASS 1;
BA_ "GenSigSNA" SG_ 1862 D_RQ_RBT_PASS "0h";
BA_ "FlexKomSigStartValue" SG_ 1863 D_RQ_ESC "0000000000000000h";
BA_ "FlexKomSID" SG_ 1863 D_RQ_ESC 14;
BA_ "FlexKomSigStartPos" SG_ 1863 D_RQ_ESC 7;
BA_ "FlexKomSigLaenge" SG_ 1863 D_RQ_ESC 64;
BA_ "FlexKomSigName" SG_ 1863 D_RQ_ESC "D_RQ_ESC";
BA_ "FlexKomComment" SG_ 1863 D_RQ_ESC "Diagnostic-Request";
BA_ "FlexKomIsMotorola" SG_ 1863 D_RQ_ESC 1;
BA_ "GenSigSNA" SG_ 1863 D_RQ_ESC "0h";
BA_ "FlexKomSigStartValue" SG_ 1865 D_RQ_ESM "0000000000000000h";
BA_ "FlexKomSID" SG_ 1865 D_RQ_ESM 90;
BA_ "FlexKomSigStartPos" SG_ 1865 D_RQ_ESM 7;
BA_ "FlexKomSigLaenge" SG_ 1865 D_RQ_ESM 64;
BA_ "FlexKomSigName" SG_ 1865 D_RQ_ESM "D_RQ_ESM";
BA_ "FlexKomComment" SG_ 1865 D_RQ_ESM "Diagnostic-Request";
BA_ "FlexKomIsMotorola" SG_ 1865 D_RQ_ESM 1;
BA_ "GenSigSNA" SG_ 1865 D_RQ_ESM "0h";
BA_ "FlexKomSigStartValue" SG_ 1867 D_RQ_DTCM "0000000000000000h";
BA_ "FlexKomSID" SG_ 1867 D_RQ_DTCM 84;
BA_ "FlexKomSigStartPos" SG_ 1867 D_RQ_DTCM 7;
BA_ "FlexKomSigLaenge" SG_ 1867 D_RQ_DTCM 64;
BA_ "FlexKomSigName" SG_ 1867 D_RQ_DTCM "D_RQ_DTCM";
BA_ "FlexKomComment" SG_ 1867 D_RQ_DTCM "Diagnostic-Request";
BA_ "FlexKomIsMotorola" SG_ 1867 D_RQ_DTCM 1;
BA_ "GenSigSNA" SG_ 1867 D_RQ_DTCM "0h";
BA_ "FlexKomSigStartValue" SG_ 1868 D_RQ_FDCM "0000000000000000h";
BA_ "FlexKomSID" SG_ 1868 D_RQ_FDCM 1599;
BA_ "FlexKomSigStartPos" SG_ 1868 D_RQ_FDCM 7;
BA_ "FlexKomSigLaenge" SG_ 1868 D_RQ_FDCM 64;
BA_ "FlexKomSigName" SG_ 1868 D_RQ_FDCM "D_RQ_FDCM";
BA_ "FlexKomComment" SG_ 1868 D_RQ_FDCM "Diagnostic-Request";
BA_ "FlexKomIsMotorola" SG_ 1868 D_RQ_FDCM 1;
BA_ "GenSigSNA" SG_ 1868 D_RQ_FDCM "0h";
BA_ "FlexKomSigStartValue" SG_ 1872 D_RQ_SCRSM "0000000000000000h";
BA_ "FlexKomSID" SG_ 1872 D_RQ_SCRSM 114;
BA_ "FlexKomSigStartPos" SG_ 1872 D_RQ_SCRSM 7;
BA_ "FlexKomSigLaenge" SG_ 1872 D_RQ_SCRSM 64;
BA_ "FlexKomSigName" SG_ 1872 D_RQ_SCRSM "D_RQ_SCRSM";
BA_ "FlexKomComment" SG_ 1872 D_RQ_SCRSM "Diagnostic-Request";
BA_ "FlexKomIsMotorola" SG_ 1872 D_RQ_SCRSM 1;
BA_ "GenSigSNA" SG_ 1872 D_RQ_SCRSM "0h";
BA_ "FlexKomSigStartValue" SG_ 1875 D_RQ_DASM "0000000000000000h";
BA_ "FlexKomSID" SG_ 1875 D_RQ_DASM 97;
BA_ "FlexKomSigStartPos" SG_ 1875 D_RQ_DASM 7;
BA_ "FlexKomSigLaenge" SG_ 1875 D_RQ_DASM 64;
BA_ "FlexKomSigName" SG_ 1875 D_RQ_DASM "D_RQ_DASM";
BA_ "FlexKomComment" SG_ 1875 D_RQ_DASM "Diagnostic-Request";
BA_ "FlexKomIsMotorola" SG_ 1875 D_RQ_DASM 1;
BA_ "GenSigSNA" SG_ 1875 D_RQ_DASM "0h";
BA_ "FlexKomSigStartValue" SG_ 1876 D_RQ_ITBM "0000000000000000h";
BA_ "FlexKomSID" SG_ 1876 D_RQ_ITBM 1480;
BA_ "FlexKomSigStartPos" SG_ 1876 D_RQ_ITBM 7;
BA_ "FlexKomSigLaenge" SG_ 1876 D_RQ_ITBM 64;
BA_ "FlexKomSigName" SG_ 1876 D_RQ_ITBM "D_RQ_ITBM";
BA_ "FlexKomComment" SG_ 1876 D_RQ_ITBM "Diagnostic-Request";
BA_ "FlexKomIsMotorola" SG_ 1876 D_RQ_ITBM 1;
BA_ "GenSigSNA" SG_ 1876 D_RQ_ITBM "0h";
BA_ "FlexKomSigStartValue" SG_ 1879 D_RQ_ADCM "0000000000000000h";
BA_ "FlexKomSID" SG_ 1879 D_RQ_ADCM 70;
BA_ "FlexKomSigStartPos" SG_ 1879 D_RQ_ADCM 7;
BA_ "FlexKomSigLaenge" SG_ 1879 D_RQ_ADCM 64;
BA_ "FlexKomSigName" SG_ 1879 D_RQ_ADCM "D_RQ_ADCM";
BA_ "FlexKomComment" SG_ 1879 D_RQ_ADCM "Diagnostic-Request";
BA_ "FlexKomIsMotorola" SG_ 1879 D_RQ_ADCM 1;
BA_ "GenSigSNA" SG_ 1879 D_RQ_ADCM "0h";
BA_ "FlexKomSigStartValue" SG_ 1881 D_RQ_EPB "0000000000000000h";
BA_ "FlexKomSID" SG_ 1881 D_RQ_EPB 1473;
BA_ "FlexKomSigStartPos" SG_ 1881 D_RQ_EPB 7;
BA_ "FlexKomSigLaenge" SG_ 1881 D_RQ_EPB 64;
BA_ "FlexKomSigName" SG_ 1881 D_RQ_EPB "D_RQ_EPB";
BA_ "FlexKomComment" SG_ 1881 D_RQ_EPB "Diagnostic-Request";
BA_ "FlexKomIsMotorola" SG_ 1881 D_RQ_EPB 1;
BA_ "GenSigSNA" SG_ 1881 D_RQ_EPB "0h";
BA_ "FlexKomSigStartValue" SG_ 1882 D_RQ_EPS "0000000000000000h";
BA_ "FlexKomSID" SG_ 1882 D_RQ_EPS 87;
BA_ "FlexKomSigStartPos" SG_ 1882 D_RQ_EPS 7;
BA_ "FlexKomSigLaenge" SG_ 1882 D_RQ_EPS 64;
BA_ "FlexKomSigName" SG_ 1882 D_RQ_EPS "D_RQ_EPS";
BA_ "FlexKomComment" SG_ 1882 D_RQ_EPS "Diagnostic-Request";
BA_ "FlexKomIsMotorola" SG_ 1882 D_RQ_EPS 1;
BA_ "GenSigSNA" SG_ 1882 D_RQ_EPS "0h";
BA_ "GenSigSendType" SG_ 1883 APPL_ECU_75Bh 1;
BA_ "FlexKomSigStartValue" SG_ 1883 APPL_ECU_75Bh "0000000000000000h";
BA_ "FlexKomSID" SG_ 1883 APPL_ECU_75Bh 1383;
BA_ "FlexKomSigStartPos" SG_ 1883 APPL_ECU_75Bh 7;
BA_ "FlexKomSigLaenge" SG_ 1883 APPL_ECU_75Bh 64;
BA_ "FlexKomSigName" SG_ 1883 APPL_ECU_75Bh "APPL_ECU_75Bh";
BA_ "FlexKomComment" SG_ 1883 APPL_ECU_75Bh "ID 75Bh held for use by CPG/APG test equipment";
BA_ "FlexKomIsMotorola" SG_ 1883 APPL_ECU_75Bh 1;
BA_ "GenSigSNA" SG_ 1883 APPL_ECU_75Bh "0h";
BA_ "GenSigSendType" SG_ 1884 APPL_ECU_75Ch 1;
BA_ "FlexKomSigStartValue" SG_ 1884 APPL_ECU_75Ch "0000000000000000h";
BA_ "FlexKomSID" SG_ 1884 APPL_ECU_75Ch 1384;
BA_ "FlexKomSigStartPos" SG_ 1884 APPL_ECU_75Ch 7;
BA_ "FlexKomSigLaenge" SG_ 1884 APPL_ECU_75Ch 64;
BA_ "FlexKomSigName" SG_ 1884 APPL_ECU_75Ch "APPL_ECU_75Ch";
BA_ "FlexKomComment" SG_ 1884 APPL_ECU_75Ch "ID 75Ch held for use by CPG/APG test equipment";
BA_ "FlexKomIsMotorola" SG_ 1884 APPL_ECU_75Ch 1;
BA_ "GenSigSNA" SG_ 1884 APPL_ECU_75Ch "0h";
BA_ "GenSigSendType" SG_ 1885 APPL_ECU_75Dh 1;
BA_ "FlexKomSigStartValue" SG_ 1885 APPL_ECU_75Dh "0000000000000000h";
BA_ "FlexKomSID" SG_ 1885 APPL_ECU_75Dh 1385;
BA_ "FlexKomSigStartPos" SG_ 1885 APPL_ECU_75Dh 7;
BA_ "FlexKomSigLaenge" SG_ 1885 APPL_ECU_75Dh 64;
BA_ "FlexKomSigName" SG_ 1885 APPL_ECU_75Dh "APPL_ECU_75Dh";
BA_ "FlexKomComment" SG_ 1885 APPL_ECU_75Dh "ID 75Dh held for use by CPG/APG test equipment";
BA_ "FlexKomIsMotorola" SG_ 1885 APPL_ECU_75Dh 1;
BA_ "GenSigSNA" SG_ 1885 APPL_ECU_75Dh "0h";
BA_ "FlexKomSigStartValue" SG_ 1886 D_RQ_OCM "0000000000000000h";
BA_ "FlexKomSID" SG_ 1886 D_RQ_OCM 1536;
BA_ "FlexKomSigStartPos" SG_ 1886 D_RQ_OCM 7;
BA_ "FlexKomSigLaenge" SG_ 1886 D_RQ_OCM 64;
BA_ "FlexKomSigName" SG_ 1886 D_RQ_OCM "D_RQ_OCM";
BA_ "FlexKomComment" SG_ 1886 D_RQ_OCM "Diagnostic-Request";
BA_ "FlexKomIsMotorola" SG_ 1886 D_RQ_OCM 1;
BA_ "GenSigSNA" SG_ 1886 D_RQ_OCM "0h";
BA_ "FlexKomSigStartValue" SG_ 1887 D_RQ_EPPM "0000000000000000h";
BA_ "FlexKomSID" SG_ 1887 D_RQ_EPPM 1333;
BA_ "FlexKomSigStartPos" SG_ 1887 D_RQ_EPPM 7;
BA_ "FlexKomSigLaenge" SG_ 1887 D_RQ_EPPM 64;
BA_ "FlexKomSigName" SG_ 1887 D_RQ_EPPM "D_RQ_EPPM";
BA_ "FlexKomComment" SG_ 1887 D_RQ_EPPM "Diagnostic-Request";
BA_ "FlexKomIsMotorola" SG_ 1887 D_RQ_EPPM 1;
BA_ "GenSigSNA" SG_ 1887 D_RQ_EPPM "0h";
BA_ "FlexKomSigStartValue" SG_ 1890 D_RQ_PTS "0000000000000000h";
BA_ "FlexKomSID" SG_ 1890 D_RQ_PTS 109;
BA_ "FlexKomSigStartPos" SG_ 1890 D_RQ_PTS 7;
BA_ "FlexKomSigLaenge" SG_ 1890 D_RQ_PTS 64;
BA_ "FlexKomSigName" SG_ 1890 D_RQ_PTS "D_RQ_PTS";
BA_ "FlexKomComment" SG_ 1890 D_RQ_PTS "Diagnostic-Request";
BA_ "FlexKomIsMotorola" SG_ 1890 D_RQ_PTS 1;
BA_ "GenSigSNA" SG_ 1890 D_RQ_PTS "0h";
BA_ "FlexKomSigStartValue" SG_ 1891 D_RQ_SCCM "0000000000000000h";
BA_ "FlexKomSID" SG_ 1891 D_RQ_SCCM 113;
BA_ "FlexKomSigStartPos" SG_ 1891 D_RQ_SCCM 7;
BA_ "FlexKomSigLaenge" SG_ 1891 D_RQ_SCCM 64;
BA_ "FlexKomSigName" SG_ 1891 D_RQ_SCCM "D_RQ_SCCM";
BA_ "FlexKomComment" SG_ 1891 D_RQ_SCCM "Diagnostic-Request";
BA_ "FlexKomIsMotorola" SG_ 1891 D_RQ_SCCM 1;
BA_ "GenSigSNA" SG_ 1891 D_RQ_SCCM "0h";
BA_ "FlexKomSigStartValue" SG_ 1892 D_RQ_HaLF "0000000000000000h";
BA_ "FlexKomSID" SG_ 1892 D_RQ_HaLF 1632;
BA_ "FlexKomSigStartPos" SG_ 1892 D_RQ_HaLF 7;
BA_ "FlexKomSigLaenge" SG_ 1892 D_RQ_HaLF 64;
BA_ "FlexKomSigName" SG_ 1892 D_RQ_HaLF "D_RQ_HaLF";
BA_ "FlexKomComment" SG_ 1892 D_RQ_HaLF "Diagnostic-Request";
BA_ "FlexKomIsMotorola" SG_ 1892 D_RQ_HaLF 1;
BA_ "GenSigSNA" SG_ 1892 D_RQ_HaLF "0h";
BA_ "FlexKomSigStartValue" SG_ 1893 D_RQ_ANC "0000000000000000h";
BA_ "FlexKomSID" SG_ 1893 D_RQ_ANC 75;
BA_ "FlexKomSigStartPos" SG_ 1893 D_RQ_ANC 7;
BA_ "FlexKomSigLaenge" SG_ 1893 D_RQ_ANC 64;
BA_ "FlexKomSigName" SG_ 1893 D_RQ_ANC "D_RQ_ANC";
BA_ "FlexKomComment" SG_ 1893 D_RQ_ANC "Diagnostic-Request";
BA_ "FlexKomIsMotorola" SG_ 1893 D_RQ_ANC 1;
BA_ "GenSigSNA" SG_ 1893 D_RQ_ANC "0h";
BA_ "FlexKomSigStartValue" SG_ 1894 D_RQ_ASCM "0000000000000000h";
BA_ "FlexKomSID" SG_ 1894 D_RQ_ASCM 76;
BA_ "FlexKomSigStartPos" SG_ 1894 D_RQ_ASCM 7;
BA_ "FlexKomSigLaenge" SG_ 1894 D_RQ_ASCM 64;
BA_ "FlexKomSigName" SG_ 1894 D_RQ_ASCM "D_RQ_ASCM";
BA_ "FlexKomComment" SG_ 1894 D_RQ_ASCM "Diagnostic-Request";
BA_ "FlexKomIsMotorola" SG_ 1894 D_RQ_ASCM 1;
BA_ "GenSigSNA" SG_ 1894 D_RQ_ASCM "0h";
BA_ "FlexKomSigStartValue" SG_ 1896 D_RQ_AFLS "0000000000000000h";
BA_ "FlexKomSID" SG_ 1896 D_RQ_AFLS 71;
BA_ "FlexKomSigStartPos" SG_ 1896 D_RQ_AFLS 7;
BA_ "FlexKomSigLaenge" SG_ 1896 D_RQ_AFLS 64;
BA_ "FlexKomSigName" SG_ 1896 D_RQ_AFLS "D_RQ_AFLS";
BA_ "FlexKomComment" SG_ 1896 D_RQ_AFLS "Diagnostic-Request";
BA_ "FlexKomIsMotorola" SG_ 1896 D_RQ_AFLS 1;
BA_ "GenSigSNA" SG_ 1896 D_RQ_AFLS "0h";
BA_ "FlexKomSigStartValue" SG_ 1897 D_RQ_AHLM "0000000000000000h";
BA_ "FlexKomSID" SG_ 1897 D_RQ_AHLM 73;
BA_ "FlexKomSigStartPos" SG_ 1897 D_RQ_AHLM 7;
BA_ "FlexKomSigLaenge" SG_ 1897 D_RQ_AHLM 64;
BA_ "FlexKomSigName" SG_ 1897 D_RQ_AHLM "D_RQ_AHLM";
BA_ "FlexKomComment" SG_ 1897 D_RQ_AHLM "Diagnostic-Request";
BA_ "FlexKomIsMotorola" SG_ 1897 D_RQ_AHLM 1;
BA_ "GenSigSNA" SG_ 1897 D_RQ_AHLM "0h";
BA_ "FlexKomSigStartValue" SG_ 1904 D_RQ_ELSD "0000000000000000h";
BA_ "FlexKomSID" SG_ 1904 D_RQ_ELSD 1593;
BA_ "FlexKomSigStartPos" SG_ 1904 D_RQ_ELSD 7;
BA_ "FlexKomSigLaenge" SG_ 1904 D_RQ_ELSD 64;
BA_ "FlexKomSigName" SG_ 1904 D_RQ_ELSD "D_RQ_ELSD";
BA_ "FlexKomComment" SG_ 1904 D_RQ_ELSD "Diagnostic-Request";
BA_ "FlexKomIsMotorola" SG_ 1904 D_RQ_ELSD 1;
BA_ "GenSigSNA" SG_ 1904 D_RQ_ELSD "0h";
BA_ "FlexKomSigStartValue" SG_ 1905 D_RQ_VSIM "0000000000000000h";
BA_ "FlexKomSID" SG_ 1905 D_RQ_VSIM 122;
BA_ "FlexKomSigStartPos" SG_ 1905 D_RQ_VSIM 7;
BA_ "FlexKomSigLaenge" SG_ 1905 D_RQ_VSIM 64;
BA_ "FlexKomSigName" SG_ 1905 D_RQ_VSIM "D_RQ_VSIM";
BA_ "FlexKomComment" SG_ 1905 D_RQ_VSIM "Diagnostic-Request";
BA_ "FlexKomIsMotorola" SG_ 1905 D_RQ_VSIM 1;
BA_ "GenSigSNA" SG_ 1905 D_RQ_VSIM "0h";
BA_ "FlexKomSigStartValue" SG_ 1911 D_RQ_VGT "0000000000000000h";
BA_ "FlexKomSID" SG_ 1911 D_RQ_VGT 1815;
BA_ "FlexKomSigStartPos" SG_ 1911 D_RQ_VGT 7;
BA_ "FlexKomSigLaenge" SG_ 1911 D_RQ_VGT 64;
BA_ "FlexKomSigName" SG_ 1911 D_RQ_VGT "D_RQ_VGT";
BA_ "FlexKomComment" SG_ 1911 D_RQ_VGT "Diagnostic-Request";
BA_ "FlexKomIsMotorola" SG_ 1911 D_RQ_VGT 1;
BA_ "GenSigSNA" SG_ 1911 D_RQ_VGT "0h";
BA_ "FlexKomSigStartValue" SG_ 2015 DG_RQ_GLOBAL "0000000000000000h";
BA_ "FlexKomSID" SG_ 2015 DG_RQ_GLOBAL 392;
BA_ "FlexKomSigStartPos" SG_ 2015 DG_RQ_GLOBAL 7;
BA_ "FlexKomSigLaenge" SG_ 2015 DG_RQ_GLOBAL 64;
BA_ "FlexKomSigName" SG_ 2015 DG_RQ_GLOBAL "DG_RQ_GLOBAL";
BA_ "FlexKomComment" SG_ 2015 DG_RQ_GLOBAL "Diagnostic-Request";
BA_ "FlexKomIsMotorola" SG_ 2015 DG_RQ_GLOBAL 1;
BA_ "GenSigSNA" SG_ 2015 DG_RQ_GLOBAL "0h";
BA_ "FlexKomSigStartValue" SG_ 2016 D_RQ_ECM "0000000000000000h";
BA_ "FlexKomSID" SG_ 2016 D_RQ_ECM 85;
BA_ "FlexKomSigStartPos" SG_ 2016 D_RQ_ECM 7;
BA_ "FlexKomSigLaenge" SG_ 2016 D_RQ_ECM 64;
BA_ "FlexKomSigName" SG_ 2016 D_RQ_ECM "D_RQ_ECM";
BA_ "FlexKomComment" SG_ 2016 D_RQ_ECM "Diagnostic-Request";
BA_ "FlexKomIsMotorola" SG_ 2016 D_RQ_ECM 1;
BA_ "GenSigSNA" SG_ 2016 D_RQ_ECM "0h";
BA_ "FlexKomSigStartValue" SG_ 2017 D_RQ_TCM "0000000000000000h";
BA_ "FlexKomSID" SG_ 2017 D_RQ_TCM 117;
BA_ "FlexKomSigStartPos" SG_ 2017 D_RQ_TCM 7;
BA_ "FlexKomSigLaenge" SG_ 2017 D_RQ_TCM 64;
BA_ "FlexKomSigName" SG_ 2017 D_RQ_TCM "D_RQ_TCM";
BA_ "FlexKomComment" SG_ 2017 D_RQ_TCM "Diagnostic-Request";
BA_ "FlexKomIsMotorola" SG_ 2017 D_RQ_TCM 1;
BA_ "GenSigSNA" SG_ 2017 D_RQ_TCM "0h";
BA_ "FlexKomSigStartValue" SG_ 2024 D_RS_ECM "0000000000000000h";
BA_ "FlexKomSID" SG_ 2024 D_RS_ECM 139;
BA_ "FlexKomSigStartPos" SG_ 2024 D_RS_ECM 7;
BA_ "FlexKomSigLaenge" SG_ 2024 D_RS_ECM 64;
BA_ "FlexKomSigName" SG_ 2024 D_RS_ECM "D_RS_ECM";
BA_ "FlexKomComment" SG_ 2024 D_RS_ECM "Diagnostic-Response";
BA_ "FlexKomIsMotorola" SG_ 2024 D_RS_ECM 1;
BA_ "GenSigSNA" SG_ 2024 D_RS_ECM "0h";
BA_ "FlexKomSigStartValue" SG_ 2025 D_RS_TCM "0000000000000000h";
BA_ "FlexKomSID" SG_ 2025 D_RS_TCM 169;
BA_ "FlexKomSigStartPos" SG_ 2025 D_RS_TCM 7;
BA_ "FlexKomSigLaenge" SG_ 2025 D_RS_TCM 64;
BA_ "FlexKomSigName" SG_ 2025 D_RS_TCM "D_RS_TCM";
BA_ "FlexKomComment" SG_ 2025 D_RS_TCM "Diagnostic-Response";
BA_ "FlexKomIsMotorola" SG_ 2025 D_RS_TCM 1;
BA_ "GenSigSNA" SG_ 2025 D_RS_TCM "0h";
VAL_ 1099 VC_BU_VehCfg5_Stat 3 "SNA" 2 "NA1" 1 "PROGAMMED" 0 "NA" ;
VAL_ 1099 VC_BU_AmbTempLct 3 "SNA" 1 "DCM" 0 "CBC" ;
VAL_ 1099 VC_BU_Strng_Rt_0 255 "SNA" ;
VAL_ 1099 VC_BU_Strng_Rt_pls1 255 "SNA" ;
VAL_ 1099 VC_BU_Strng_Rt_pls2 255 "SNA" ;
VAL_ 1099 VC_BU_Strng_Rt_pls3 255 "SNA" ;
VAL_ 1099 VC_BU_Strng_Rt_pls4 255 "SNA" ;
VAL_ 1099 VC_BU_Strng_Rt_pls5 255 "SNA" ;
VAL_ 1100 VC_VehCfg6_Stat 3 "SNA" 2 "REQUEST_DATA" 1 "PROGAMMED" 0 "NA" ;
VAL_ 1100 VC_AnlgDrSnsr 3 "ALL" 2 "FT" 1 "DRV" 0 "NONE" ;
VAL_ 1100 VC_BrkTyp 7 "SNA" 3 "MB" 2 "CB" 1 "PB" 0 "SMALL" ;
VAL_ 1100 VC_Strng_Rt_Mns1 255 "SNA" ;
VAL_ 1100 VC_Strng_Rt_Mns2 255 "SNA" ;
VAL_ 1100 VC_Strng_Rt_Mns3 255 "SNA" ;
VAL_ 1100 VC_Strng_Rt_Mns4 255 "SNA" ;
VAL_ 1100 VC_Strng_Rt_Mns5 255 "SNA" ;
VAL_ 1100 VC_TireCircumfFT 65535 "SNA" ;
VAL_ 1101 VC_BU_VehCfg6_Stat 3 "SNA" 2 "NA1" 1 "PROGAMMED" 0 "NA" ;
VAL_ 1101 VC_BU_AnlgDrSnsr 3 "ALL" 2 "FT" 1 "DRV" 0 "NONE" ;
VAL_ 1101 VC_BU_BrkTyp 7 "SNA" 3 "MB" 2 "CB" 1 "PB" 0 "SMALL" ;
VAL_ 1101 VC_BU_Strng_Rt_Mns1 255 "SNA" ;
VAL_ 1101 VC_BU_Strng_Rt_Mns2 255 "SNA" ;
VAL_ 1101 VC_BU_Strng_Rt_Mns3 255 "SNA" ;
VAL_ 1101 VC_BU_Strng_Rt_Mns4 255 "SNA" ;
VAL_ 1101 VC_BU_Strng_Rt_Mns5 255 "SNA" ;
VAL_ 1101 VC_BU_TireCircumfFT 65535 "SNA" ;
